[part 2 of 3: package /Cluster]
AUTOSAR XML (schema 00048)
package /Cluster
  5 x can cluster, all with protocol-name=CAN:
    ATOM_CANFD_Matrix_CH_V600_202502  # ATOM_CANFD_Matrix_CH_V6.0.0_20250507 | Revision:V1.0, Revision:V1.0.1, Revision:V1.0.1, Revision:V1.0.1, Revision:V1.0.1, Revision:V1.0.2, Revision:V1.0.2, Revision:V1.0.2, Revision:V1.0.2, Revision:V1.0.2, Revision:V1.0.2, Revision:V1.0.2, Revision:V1.0.2, Revision:V1.0.2, Revision:V1.0.2, Revision:V1.0.2, Revision:V1.0.2, Revision:V1.0.2, Revision:V1.0.2, Revision:V1.0.2, Revision:V1.0.2, Revision:V1.0.2, Revision:V1.0.2, Revision:V1.0.2, Revision:V1.1, Revision:V1.1, Revision:V1.1, Revision:V1.1, Revision:V1.1, Revision:V1.1, Revision:V1.1, Revision:V1.1, Revision:V1.1, Revision:V1.1, Revision:V1.1, Revision:V1.1, Revision:V1.1, Revision:V1.1, Revision:V1.1, Revision:V1.1, Revision:V1.1, Revision:V1.1, Revision:V1.1, Revision:V1.1, Revision:V1.1, Revision:V1.1, Revision:V1.2, Revision:V0.1.3, Revision:V0.1.3, Revision:V0.1.3, Revision:V0.1.3, Revision:V0.1.3, Revision:V0.1.3, Revision:V0.1.3, Revision:V0.1.3, Revision:V0.1.3, Revision:V0.1.3, Revision:V0.1.3, Revision:V0.1.3, Revision:
      can physical channel CHNL: comm-connectors=CN_ATOM_CANFD_Matrix_CH_V600_202502
        frame ACU_01_oATOM_CANFD_Matrix_CH_V600_202502: id 0xF5, to VCU, frame-length=8, can-addressing-mode=STANDARD, can-frame-rx-behavior=ANY, can-frame-tx-behavior=CAN-FD
          pdu ACU_01_oATOM_CANFD_Matrix_CH_V600_202502: length=8, minimum-delay=0, transmission-mode-false-timing=cyclic-timing={time-offset=0, time-period=0.02}, transmission-mode-true-timing=cyclic-timing={time-offset=0, time-period=0.02}, unused-bit-pattern=0
            signal Checksum_0F5_oACU_01_oATOM_CANFD_Matrix_CH_V600_202502: start 7, 8 bit, big-endian, i-signal-type=PRIMITIVE, init-value=0, base-type=uint8, compu {identical}, range raw 0..255, transfer-property=PENDING, to VCU  # Checksum signal for frame
            signal MessageCounter_0F5_oACU_01_oATOM_CANFD_Matrix_CH_V600_202502: start 11, 4 bit, big-endian, i-signal-type=PRIMITIVE, init-value=0, base-type=uint8, compu {15=CxF_Invalid}, range raw 0..15, transfer-property=PENDING, to VCU  # Message counter signal for frame
            signal ACU_YawRate_oACU_01_oATOM_CANFD_Matrix_CH_V600_202502: start 23, 16 bit, big-endian, i-signal-type=PRIMITIVE, init-value=30000, base-type=uint16, compu {65535=CxFFFF_Invalid, phys=raw*0.01-300 for raw 0..65534; unit degrees/s}, range raw 0..65535, unit=degrees/s, transfer-property=PENDING, to VCU  # Yaw rate (clockwise is negative, counterclockwise is positive)
            signal ACU_YawRateStatus_oACU_01_oATOM_CANFD_Matrix_CH_V600_202502: start 39, 2 bit, big-endian, i-signal-type=PRIMITIVE, init-value=0, base-type=uint8, compu {0=Cx0_Invalid, 1=Cx1_Valid, 2=Cx2_Reserved, 3=Cx3_Reserved}, range raw 0..3, transfer-property=PENDING, to VCU  # Yaw rate status
            mapping SG_ACU_01_SigGroup: i-signal-group=SG_ACU_01_SigGroup_oACU_01_oATOM_CANFD_Matrix_CH_V600_202502, transfer-property=PENDING
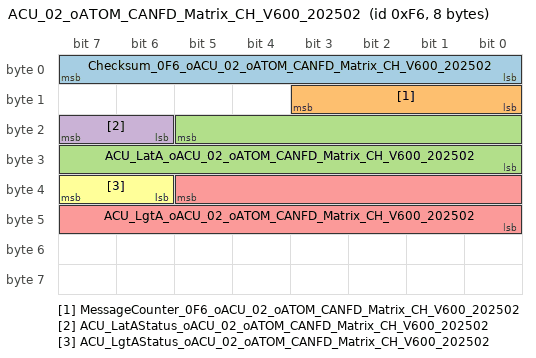
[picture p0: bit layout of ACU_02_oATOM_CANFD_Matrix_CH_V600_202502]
        frame ACU_02_oATOM_CANFD_Matrix_CH_V600_202502: id 0xF6, to VCU, frame-length=8, can-addressing-mode=STANDARD, can-frame-rx-behavior=ANY, can-frame-tx-behavior=CAN-FD
          pdu ACU_02_oATOM_CANFD_Matrix_CH_V600_202502: length=8, minimum-delay=0, transmission-mode-false-timing=cyclic-timing={time-offset=0, time-period=0.02}, transmission-mode-true-timing=cyclic-timing={time-offset=0, time-period=0.02}, unused-bit-pattern=0
            signal Checksum_0F6_oACU_02_oATOM_CANFD_Matrix_CH_V600_202502: start 7, 8 bit, big-endian, i-signal-type=PRIMITIVE, init-value=0, base-type=uint8, compu {identical}, range raw 0..255, transfer-property=PENDING, to VCU  # Checksum signal for frame
            signal MessageCounter_0F6_oACU_02_oATOM_CANFD_Matrix_CH_V600_202502: start 11, 4 bit, big-endian, i-signal-type=PRIMITIVE, init-value=0, base-type=uint8, compu {15=CxF_Invalid}, range raw 0..15, transfer-property=PENDING, to VCU  # Message counter signal for frame
            signal ACU_LatA_oACU_02_oATOM_CANFD_Matrix_CH_V600_202502: start 21, 14 bit, big-endian, i-signal-type=PRIMITIVE, init-value=4905, base-type=uint16, compu {16383=Cx3FFF_Invalid, phys=raw*0.01-49.05 for raw 0..16382; unit m/s^2} "Source signal range: [0,16383]", range raw 0..16383, unit=m/s^2, transfer-property=PENDING, to VCU  # Lateral acceleration(From the driver's perspective, from left to right is the positive direction of lateral acceleration)
            signal ACU_LatAStatus_oACU_02_oATOM_CANFD_Matrix_CH_V600_202502: start 23, 2 bit, big-endian, i-signal-type=PRIMITIVE, init-value=0, base-type=uint8, compu {0=Cx0_Invalid, 1=Cx1_Valid, 2=Cx2_Reserved, 3=Cx3_Reserved}, range raw 0..3, transfer-property=PENDING, to VCU  # Lateral acceleration status
            signal ACU_LgtA_oACU_02_oATOM_CANFD_Matrix_CH_V600_202502: start 37, 14 bit, big-endian, i-signal-type=PRIMITIVE, init-value=4905, base-type=uint16, compu {16383=Cx3FFF_Invalid, phys=raw*0.01-49.05 for raw 0..16382; unit m/s^2} "Source signal range: [0,16383]", range raw 0..16383, unit=m/s^2, transfer-property=PENDING, to VCU  # Longitudinal acceleration(The forward direction of the vehicle is the positive direction of the longitudinal acceleration)
            signal ACU_LgtAStatus_oACU_02_oATOM_CANFD_Matrix_CH_V600_202502: start 39, 2 bit, big-endian, i-signal-type=PRIMITIVE, init-value=0, base-type=uint8, compu {0=Cx0_Invalid, 1=Cx1_Valid, 2=Cx2_Reserved, 3=Cx3_Reserved}, range raw 0..3, transfer-property=PENDING, to VCU  # Longitudinal acceleration status
            mapping SG_ACU_02_SigGroup: i-signal-group=SG_ACU_02_SigGroup_oACU_02_oATOM_CANFD_Matrix_CH_V600_202502, transfer-property=PENDING
        frame ACU_info_oATOM_CANFD_Matrix_CH_V600_202502: id 0x97, to VCU, frame-length=8, can-addressing-mode=STANDARD, can-frame-rx-behavior=ANY, can-frame-tx-behavior=CAN-FD
          pdu ACU_info_oATOM_CANFD_Matrix_CH_V600_202502: length=8, minimum-delay=0, transmission-mode-false-timing=cyclic-timing={time-offset=0, time-period=0.02}, transmission-mode-true-timing=cyclic-timing={time-offset=0, time-period=0.02}, unused-bit-pattern=0
            signal Checksum_097_oACU_info_oATOM_CANFD_Matrix_CH_V600_202502: start 7, 8 bit, big-endian, i-signal-type=PRIMITIVE, init-value=0, base-type=uint8, compu {identical}, range raw 0..255, transfer-property=PENDING, to VCU  # Checksum signal for frame
            signal MessageCounter_097_oACU_info_oATOM_CANFD_Matrix_CH_V600_202502: start 11, 4 bit, big-endian, i-signal-type=PRIMITIVE, init-value=0, base-type=uint8, compu {15=CxF_Invalid}, range raw 0..15, transfer-property=PENDING, to VCU  # Message counter signal for frame
            signal ACU_CrashOutputStsValid_oACU_info_oATOM_CANFD_Matrix_CH_V600_202502: start 16, 1 bit, big-endian, i-signal-type=PRIMITIVE, init-value=1, base-type=boolean, compu {0=Cx0_INVALID, 1=Cx1_VALID}, range raw 0..1, transfer-property=PENDING, to VCU  # Collision signal effective indication
            signal ACU_CrashOutputSts_oACU_info_oATOM_CANFD_Matrix_CH_V600_202502: start 23, 5 bit, big-endian, i-signal-type=PRIMITIVE, init-value=0, base-type=uint8, compu {0=Cx00_No_Crash (No Crash), 1=Cx01_Rollover, 2=Cx02_BPT_Crash (BPT Crash), 3=Cx03_Rollover_BPT (Rollover + BPT), 4=Cx04_Front_Crash (Front Crash), 5=Cx05_Rollover_Front (Rollover + Front), 6=Cx06_BPT_Front (BPT+Front), 7=Cx07_Rollover_BPT_Front (Rollover+BPT+Front), 8=Cx08_Side_Crash (Side Crash), 9=Cx09_Rollover_Side (Rollover+Side), 10=Cx0A_BPT_Side (BPT+Side), 11=Cx0B_Rollover_BPT_Side (Rollover+BPT+Side), 12=Cx0C_Front_Side (Front+Side), 13=Cx0D_Rollover_Front_Side (Rollover+Front+Side), 14=Cx0E_BPT_Front_Side (BPT+Front+Side), 15=Cx0F_Rollover_BPT_Front_Side (Rollover+BPT+Front+Side), 16=Cx10_Rear_Crash (Rear Crash), 17=Cx11_Rollover_Rear (Rollover+Rear), 18=Cx12_BPT_Rear (BPT+Rear), 19=Cx13_Rollover_BPT_Rear (Rollover+BPT+Rear), 20=Cx14_Front_Rear (Front+Rear), 21=Cx15_Rollover_Front_Rear (Rollover+Front+Rear), 22=Cx16_BPT_Front_Rear (BPT+Front+Rear), 23=Cx17_Rollover_BPT_Front_Rear (Rollover+BPT+Front+Rear), 24=Cx18_Side_Rear (Side+Rear), 25=Cx19_Rollover_Side_Rear (Rollover+Side+Rear), 26=Cx1A_BPT_Side_Rear (BPT+Side+Rear), 27=Cx1B_Rollover_BPT_Side_Rear (Rollover+BPT+Side+Rear), 28=Cx1C_Front_Side_Rear (Front+Side+Rear), 29=Cx1D_Rollover_Front_Side_Rear (Rollover+Front+Side+Rear), 30=Cx1E_BPT_Front_Side_Rear (BPT+Front+Side+Rear), 31=Cx1F_Rollover_BPT_Front_Side_Rear (Rollover+BPT+Front+Side+Rear)}, range raw 0..31, transfer-property=PENDING, to VCU  # Crash Output Status
            signal ACU_PassengerSts_oACU_info_oATOM_CANFD_Matrix_CH_V600_202502: start 25, 1 bit, big-endian, i-signal-type=PRIMITIVE, init-value=0, base-type=boolean, compu {0=Cx0_UNOCCUPIED, 1=Cx1_OCCUPIED}, range raw 0..1, transfer-property=PENDING, to VCU  # Passenger seat occupied state
            signal ACU_PassengerSeatBeltStsValid_oACU_info_oATOM_CANFD_Matrix_CH_V600_202502: start 26, 1 bit, big-endian, i-signal-type=PRIMITIVE, init-value=0, base-type=boolean, compu {0=Cx0_INVALID, 1=Cx1_VALID}, range raw 0..1, transfer-property=PENDING, to VCU  # Passenger seat belt status invalid signal
            signal ACU_PassengerSeatBeltSts_oACU_info_oATOM_CANFD_Matrix_CH_V600_202502: start 27, 1 bit, big-endian, i-signal-type=PRIMITIVE, init-value=0, base-type=boolean, compu {0=Cx0_UNTIED, 1=Cx1_TIED}, range raw 0..1, transfer-property=PENDING, to VCU  # Passenger seat belt status
            signal ACU_DriverSeatBeltStsValid_oACU_info_oATOM_CANFD_Matrix_CH_V600_202502: start 30, 1 bit, big-endian, i-signal-type=PRIMITIVE, init-value=0, base-type=boolean, compu {0=Cx0_INVALID, 1=Cx1_VALID}, range raw 0..1, transfer-property=PENDING, to VCU  # Driver seat belt state invalid
            signal ACU_DriverSeatBeltSts_oACU_info_oATOM_CANFD_Matrix_CH_V600_202502: start 31, 1 bit, big-endian, i-signal-type=PRIMITIVE, init-value=0, base-type=boolean, compu {0=Cx0_UNTIED, 1=Cx1_TIED}, range raw 0..1, transfer-property=PENDING, to VCU  # Driver seat belt status
            signal ACU_SecondLeftSts_oACU_info_oATOM_CANFD_Matrix_CH_V600_202502: start 37, 1 bit, big-endian, i-signal-type=PRIMITIVE, init-value=0, base-type=boolean, compu {0=Cx0_UNOCCUPIED, 1=Cx1_OCCUPIED}, range raw 0..1, transfer-property=PENDING, to VCU  # The left seat of the second row is occupied
            signal ACU_RLSeatBeltStatusValid_oACU_info_oATOM_CANFD_Matrix_CH_V600_202502: start 38, 1 bit, big-endian, i-signal-type=PRIMITIVE, init-value=0, base-type=boolean, compu {0=Cx0_INVALID, 1=Cx1_VALID}, range raw 0..1, transfer-property=PENDING, to VCU  # Second row seat belt status on the left is valid
            signal ACU_SecondLeftSeatBeltSts_oACU_info_oATOM_CANFD_Matrix_CH_V600_202502: start 39, 1 bit, big-endian, i-signal-type=PRIMITIVE, init-value=0, base-type=boolean, compu {0=Cx0_UNTIED, 1=Cx1_TIED}, range raw 0..1, transfer-property=PENDING, to VCU  # Second row left seat belt condition
            signal ACU_SecondRightSts_oACU_info_oATOM_CANFD_Matrix_CH_V600_202502: start 53, 1 bit, big-endian, i-signal-type=PRIMITIVE, init-value=0, base-type=boolean, compu {0=Cx0_UNOCCUPIED, 1=Cx1_OCCUPIED}, range raw 0..1, transfer-property=PENDING, to VCU  # The right seat of the second row is occupied
            signal ACU_RRSeatBeltStatusValid_oACU_info_oATOM_CANFD_Matrix_CH_V600_202502: start 54, 1 bit, big-endian, i-signal-type=PRIMITIVE, init-value=0, base-type=boolean, compu {0=Cx0_INVALID, 1=Cx1_VALID}, range raw 0..1, transfer-property=PENDING, to VCU  # Second row seat belt status on the lright is valid
            signal ACU_SecondRightSeatBeltSts_oACU_info_oATOM_CANFD_Matrix_CH_V600_202502: start 55, 1 bit, big-endian, i-signal-type=PRIMITIVE, init-value=0, base-type=boolean, compu {0=Cx0_UNTIED, 1=Cx1_TIED}, range raw 0..1, transfer-property=PENDING, to VCU  # Second row right seat belt status
            signal ACU_WarningLampSts_oACU_info_oATOM_CANFD_Matrix_CH_V600_202502: start 57, 2 bit, big-endian, i-signal-type=PRIMITIVE, init-value=0, base-type=uint8, compu {0=Cx0_OFF, 1=Cx1_ON, 2=Cx2_FLASH}, range raw 0..2, transfer-property=PENDING, to VCU  # WarningLampStatus
            signal ACU_PassengerWarningLampSts_oACU_info_oATOM_CANFD_Matrix_CH_V600_202502: start 59, 2 bit, big-endian, i-signal-type=PRIMITIVE, init-value=0, base-type=uint8, compu {0=Cx0_OFF, 1=Cx1_ON, 2=Cx2_FLASH}, range raw 0..2, transfer-property=PENDING, to VCU  # Passenger Warning Lamp Status
            signal ACU_DriverWarningLampSts_oACU_info_oATOM_CANFD_Matrix_CH_V600_202502: start 61, 2 bit, big-endian, i-signal-type=PRIMITIVE, init-value=0, base-type=uint8, compu {0=Cx0_OFF, 1=Cx1_ON, 2=Cx2_FLASH}, range raw 0..2, transfer-property=PENDING, to VCU  # Driver Warning Lamp Status
            signal ACU_PassengerAirbagSts_oACU_info_oATOM_CANFD_Matrix_CH_V600_202502: start 63, 2 bit, big-endian, i-signal-type=PRIMITIVE, init-value=0, base-type=uint8, compu {0=Cx0_RESERVED, 1=Cx1_Disabled, 2=Cx2_Enabled, 3=Cx3_RESERVED}, range raw 0..3, transfer-property=PENDING, to VCU  # Passenger Airbag Status, closed or not
            mapping SG_ACU_info_SigGroup: i-signal-group=SG_ACU_info_SigGroup_oACU_info_oATOM_CANFD_Matrix_CH_V600_202502, transfer-property=PENDING
        frame ADCU_ACC_02_oATOM_CANFD_Matrix_CH_V600_202502: id 0xE0, to VCU, frame-length=8, can-addressing-mode=STANDARD, can-frame-rx-behavior=ANY, can-frame-tx-behavior=CAN-FD
          pdu ADCU_ACC_02_oATOM_CANFD_Matrix_CH_V600_202502: length=8, minimum-delay=0, transmission-mode-false-timing=cyclic-timing={time-offset=0, time-period=0.02}, transmission-mode-true-timing=cyclic-timing={time-offset=0, time-period=0.02}, unused-bit-pattern=0
            signal Checksum_0E0_oADCU_ACC_02_oATOM_CANFD_Matrix_CH_V600_202502: start 7, 8 bit, big-endian, i-signal-type=PRIMITIVE, init-value=0, base-type=uint8, compu {identical}, range raw 0..255, transfer-property=PENDING, to VCU  # Checksum signal for frame
            signal MessageCounter_0E0_oADCU_ACC_02_oATOM_CANFD_Matrix_CH_V600_202502: start 11, 4 bit, big-endian, i-signal-type=PRIMITIVE, init-value=0, base-type=uint8, compu {15=CxF_Invalid}, range raw 0..15, transfer-property=PENDING, to VCU  # Message counter signal for frame
            signal ADCU_ACCDA_HandsOFF_Warning_oADCU_ACC_02_oATOM_CANFD_Matrix_CH_V600_202502: start 18, 3 bit, big-endian, i-signal-type=PRIMITIVE, init-value=0, base-type=uint8, compu {0=Cx0_No_Warning (No Warning), 1=Cx1_Hands_Off_1st_Warning (Hands Off 1st Warning), 2=Cx2_Hands_Off_2nd_Warning (Hands Off 2nd Warning), 3=Cx3_Function_Automatic_exit_Warning (Function Automatic exit Warning), 4=Cx4_Reserved, 5=Cx5_Reserved, 6=Cx6_Reserved, 7=Cx7_Reserved}, range raw 0..7, transfer-property=PENDING, to VCU  # ACC/DA Hands off warning
            signal ADCU_ACC_Mode_oADCU_ACC_02_oATOM_CANFD_Matrix_CH_V600_202502: start 21, 3 bit, big-endian, i-signal-type=PRIMITIVE, init-value=0, base-type=uint8, compu {0=Cx0_Off, 1=Cx1_Active_State (Active State), 2=Cx2_Override_State (Override State), 3=Cx3_Shut_off_State (Shut-off State), 4=Cx4_Standby_State (Standby State), 5=Cx5_Fail_State (Fail State), 6=Cx6_Reserved, 7=Cx7_Reserved}, range raw 0..7, transfer-property=PENDING, to VCU  # ACC mode for system state
            signal ADCU_ACCDA_SYS_Failure_oADCU_ACC_02_oATOM_CANFD_Matrix_CH_V600_202502: start 23, 2 bit, big-endian, i-signal-type=PRIMITIVE, init-value=0, base-type=uint8, compu {0=Cx0_No_Error (No Error), 1=Cx1_Error, 2=Cx2_Reserved, 3=Cx3_Reserved}, range raw 0..3, transfer-property=PENDING, to VCU  # ACC/DA system failure state If this signal is set to anything other than 0, the IBS shall ignore any requests from ACC
            mapping SG_ADCU_ACC_02_SigGroup: i-signal-group=SG_ADCU_ACC_02_SigGroup_oADCU_ACC_02_oATOM_CANFD_Matrix_CH_V600_202502, transfer-property=PENDING
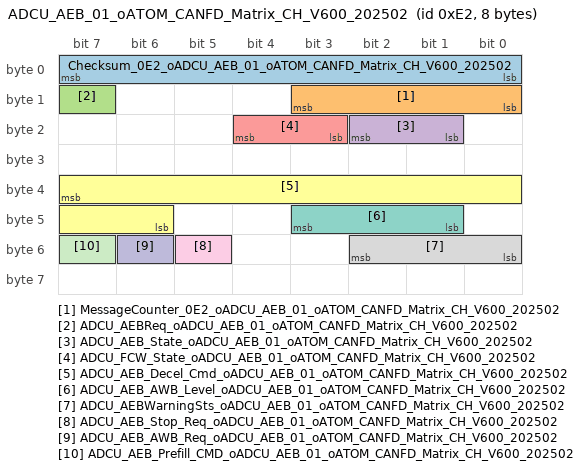
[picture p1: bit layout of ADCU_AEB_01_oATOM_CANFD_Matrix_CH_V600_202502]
        frame ADCU_AEB_01_oATOM_CANFD_Matrix_CH_V600_202502: id 0xE2, to VCU, frame-length=8, can-addressing-mode=STANDARD, can-frame-rx-behavior=ANY, can-frame-tx-behavior=CAN-FD
          pdu ADCU_AEB_01_oATOM_CANFD_Matrix_CH_V600_202502: length=8, minimum-delay=0, transmission-mode-false-timing=cyclic-timing={time-offset=0, time-period=0.02}, transmission-mode-true-timing=cyclic-timing={time-offset=0, time-period=0.02}, unused-bit-pattern=0
            signal Checksum_0E2_oADCU_AEB_01_oATOM_CANFD_Matrix_CH_V600_202502: start 7, 8 bit, big-endian, i-signal-type=PRIMITIVE, init-value=0, base-type=uint8, compu {identical}, range raw 0..255, transfer-property=PENDING, to VCU  # Checksum signal for frame
            signal MessageCounter_0E2_oADCU_AEB_01_oATOM_CANFD_Matrix_CH_V600_202502: start 11, 4 bit, big-endian, i-signal-type=PRIMITIVE, init-value=0, base-type=uint8, compu {15=CxF_Invalid}, range raw 0..15, transfer-property=PENDING, to VCU  # Message counter signal for frame
            signal ADCU_AEBReq_oADCU_AEB_01_oATOM_CANFD_Matrix_CH_V600_202502: start 15, 1 bit, big-endian, i-signal-type=PRIMITIVE, init-value=0, base-type=boolean, compu {0=Cx0_No_active (No active), 1=Cx1_active}, range raw 0..1, transfer-property=PENDING, to VCU  # A control requeset flag for AEB
            signal ADCU_AEB_State_oADCU_AEB_01_oATOM_CANFD_Matrix_CH_V600_202502: start 18, 2 bit, big-endian, i-signal-type=PRIMITIVE, init-value=0, base-type=uint8, compu {0=Cx0_Off, 1=Cx1_Standby, 2=Cx2_Active, 3=Cx3_Failure}, range raw 0..3, transfer-property=PENDING, to VCU  # This signal describes the state AEB Function.
            signal ADCU_FCW_State_oADCU_AEB_01_oATOM_CANFD_Matrix_CH_V600_202502: start 20, 2 bit, big-endian, i-signal-type=PRIMITIVE, init-value=0, base-type=uint8, compu {0=Cx0_Off, 1=Cx1_Standby, 2=Cx2_Active, 3=Cx3_Failure}, range raw 0..3, transfer-property=PENDING, to VCU  # This signal describes the state FCW Function.
            signal ADCU_AEB_Decel_Cmd_oADCU_AEB_01_oATOM_CANFD_Matrix_CH_V600_202502: start 39, 10 bit, big-endian, i-signal-type=PRIMITIVE, init-value=0, base-type=sint16, compu {phys=raw*0.05-16 for raw 0..511; unit m/s^2}, range raw 0..511, unit=m/s^2, transfer-property=PENDING, to VCU  # Depending on the driving situation, ADCU gives IBS the AEB deceleration command. IBS maintains the deceleration.
            signal ADCU_AEB_AWB_Level_oADCU_AEB_01_oATOM_CANFD_Matrix_CH_V600_202502: start 43, 3 bit, big-endian, i-signal-type=PRIMITIVE, init-value=0, base-type=uint8, compu {0=Cx0_No_level (No level), 1=Cx1_Level_1 (Level 1), 2=Cx2_Level_2 (Level 2), 3=Cx3_Level_3 (Level 3), 4=Cx4_Level_4 (Level 4), 5=Cx5_Reserved}, range raw 0..5, transfer-property=PENDING, to VCU  # AWB level
            signal ADCU_AEBWarningSts_oADCU_AEB_01_oATOM_CANFD_Matrix_CH_V600_202502: start 50, 3 bit, big-endian, i-signal-type=PRIMITIVE, init-value=0, base-type=uint8, compu {0=Cx0_NO_WARNING, 1=Cx1_PreWarning_to_car (PreWarning to car), 2=Cx2_Latent_distance_Warning (Latent distance Warning), 3=Cx3_Braking_to_car (Braking to car), 4=Cx4_PreWarning_to_PED (PreWarning to PED), 5=Cx5_Braking_to_PED (Braking to PED), 6=Cx6_Reserved, 7=Cx7_Reserved}, range raw 0..7, transfer-property=PENDING, to VCU  # PEBSWarning,include PreWarning and emergency Warning.
            signal ADCU_AEB_Stop_Req_oADCU_AEB_01_oATOM_CANFD_Matrix_CH_V600_202502: start 53, 1 bit, big-endian, i-signal-type=PRIMITIVE, init-value=0, base-type=boolean, compu {0=Cx0_No_request (No request), 1=Cx1_Stop_control_is_required (Stop control is required)}, range raw 0..1, transfer-property=PENDING, to VCU  # A control request flag for vehicle stop. AEB expects vehicle to be controlled to a complete stop and hold its state by ESC.
            signal ADCU_AEB_AWB_Req_oADCU_AEB_01_oATOM_CANFD_Matrix_CH_V600_202502: start 54, 1 bit, big-endian, i-signal-type=PRIMITIVE, init-value=0, base-type=boolean, compu {0=Cx0_No_Request (No Request), 1=Cx1_Request}, range raw 0..1, transfer-property=PENDING, to VCU  # This signal means command to activate AWB
            signal ADCU_AEB_Prefill_CMD_oADCU_AEB_01_oATOM_CANFD_Matrix_CH_V600_202502: start 55, 1 bit, big-endian, i-signal-type=PRIMITIVE, init-value=0, base-type=boolean, compu {0=Cx0_No_pre_fill (No pre-fill), 1=Cx1_Pre_fill_act (Pre-fill act)}, range raw 0..1, transfer-property=PENDING, to VCU  # This signal means command to activate pre-fill
            mapping SG_ADCU_AEB_01_SigGroup: i-signal-group=SG_ADCU_AEB_01_SigGroup_oADCU_AEB_01_oATOM_CANFD_Matrix_CH_V600_202502, transfer-property=PENDING
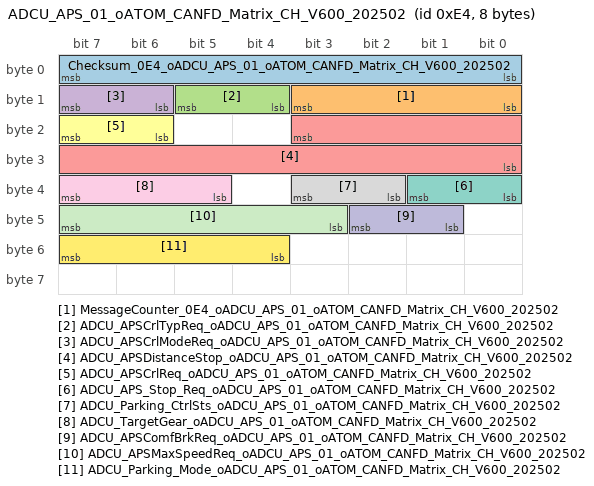
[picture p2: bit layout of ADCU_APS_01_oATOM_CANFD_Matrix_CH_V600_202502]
        frame ADCU_APS_01_oATOM_CANFD_Matrix_CH_V600_202502: id 0xE4, to VCU, frame-length=8, can-addressing-mode=STANDARD, can-frame-rx-behavior=ANY, can-frame-tx-behavior=CAN-FD
          pdu ADCU_APS_01_oATOM_CANFD_Matrix_CH_V600_202502: length=8, minimum-delay=0, transmission-mode-false-timing=cyclic-timing={time-offset=0, time-period=0.02}, transmission-mode-true-timing=cyclic-timing={time-offset=0, time-period=0.02}, unused-bit-pattern=0
            signal Checksum_0E4_oADCU_APS_01_oATOM_CANFD_Matrix_CH_V600_202502: start 7, 8 bit, big-endian, i-signal-type=PRIMITIVE, init-value=0, base-type=uint8, compu {identical}, range raw 0..255, transfer-property=PENDING, to VCU  # Checksum signal for frame
            signal MessageCounter_0E4_oADCU_APS_01_oATOM_CANFD_Matrix_CH_V600_202502: start 11, 4 bit, big-endian, i-signal-type=PRIMITIVE, init-value=0, base-type=uint8, compu {15=CxF_Invalid}, range raw 0..15, transfer-property=PENDING, to VCU  # Message counter signal for frame
            signal ADCU_APSCrlTypReq_oADCU_APS_01_oATOM_CANFD_Matrix_CH_V600_202502: start 13, 2 bit, big-endian, i-signal-type=PRIMITIVE, init-value=0, base-type=uint8, compu {0=Cx0_None, 1=Cx1_Comfort, 2=Cx2_Emergency, 3=Cx3_Reserved}, range raw 0..3, transfer-property=PENDING, to VCU  # Request comfort or emergency brake
            signal ADCU_APSCrlModeReq_oADCU_APS_01_oATOM_CANFD_Matrix_CH_V600_202502: start 15, 2 bit, big-endian, i-signal-type=PRIMITIVE, init-value=0, base-type=uint8, compu {0=Cx0_None, 1=Cx1_APS, 2=Cx2_RC, 3=Cx3_Reserved}, range raw 0..3, transfer-property=PENDING, to VCU  # Request Low Speed Maneuvering Control Mode (PAS (full/semi auto) or RC)
            signal ADCU_APSDistanceStop_oADCU_APS_01_oATOM_CANFD_Matrix_CH_V600_202502: start 19, 12 bit, big-endian, i-signal-type=PRIMITIVE, init-value=0, base-type=uint16, compu {4095=CxFFF_Invalid; unit cm}, range raw 0..4095, unit=cm, transfer-property=PENDING, to VCU  # Stopdistance request
            signal ADCU_APSCrlReq_oADCU_APS_01_oATOM_CANFD_Matrix_CH_V600_202502: start 23, 2 bit, big-endian, i-signal-type=PRIMITIVE, init-value=0, base-type=uint8, compu {0=Cx0_Req_None, 1=Cx1_Req_Drive, 2=Cx2_Req_LSM}, range raw 0..2, transfer-property=PENDING, to VCU  # Request Maneuvering dynamic control function (Driving or Low Speed Maneuvering)
            signal ADCU_APS_Stop_Req_oADCU_APS_01_oATOM_CANFD_Matrix_CH_V600_202502: start 33, 2 bit, big-endian, i-signal-type=PRIMITIVE, init-value=0, base-type=uint8, compu {0=Cx0_No_request (No request), 1=Cx1_Stop_control_is_required (Stop control is required), 2=Cx2_No_need_to_stop (No need to stop)}, range raw 0..2, transfer-property=PENDING, to VCU  # Request complete stop and hold its state by IBS
            signal ADCU_Parking_CtrlSts_oADCU_APS_01_oATOM_CANFD_Matrix_CH_V600_202502: start 35, 2 bit, big-endian, i-signal-type=PRIMITIVE, init-value=0, base-type=uint8, compu {0=Cx0_OFF, 1=Cx1_ON, 2=Cx2_Failure, 3=Cx3_Reserved}, range raw 0..3, transfer-property=PENDING, to VCU  # Parking indicator light status
            signal ADCU_TargetGear_oADCU_APS_01_oATOM_CANFD_Matrix_CH_V600_202502: start 39, 3 bit, big-endian, i-signal-type=PRIMITIVE, init-value=0, base-type=uint8, compu {0=Cx0_No_Request (No Request), 1=Cx1_P, 2=Cx2_N, 3=Cx3_R, 4=Cx4_D}, range raw 0..4, transfer-property=PENDING, to VCU  # Shift request signal
            signal ADCU_APSComfBrkReq_oADCU_APS_01_oATOM_CANFD_Matrix_CH_V600_202502: start 42, 2 bit, big-endian, i-signal-type=PRIMITIVE, init-value=0, base-type=uint8, compu {0=Cx0_ComfBrakeReq_NoReq, 1=Cx1_ComfBrakeReq_Type1, 2=Cx2_ComfBrakeReq_Type2}, range raw 0..2, transfer-property=PENDING, to VCU  # BrakeMode Request
            signal ADCU_APSMaxSpeedReq_oADCU_APS_01_oATOM_CANFD_Matrix_CH_V600_202502: start 47, 5 bit, big-endian, i-signal-type=PRIMITIVE, init-value=0, base-type=uint8, compu {31=Cx1F_Invalid; unit km/h} "Source signal range: [0,30]", range raw 0..31, unit=km/h, transfer-property=PENDING, to VCU  # V Max request
            signal ADCU_Parking_Mode_oADCU_APS_01_oATOM_CANFD_Matrix_CH_V600_202502: start 55, 4 bit, big-endian, i-signal-type=PRIMITIVE, init-value=0, base-type=uint8, compu {0=Cx0_Off, 1=Cx1_Standby, 2=Cx2_Background_searching (Background searching), 3=Cx3_Searching, 4=Cx4_Guidance_active (Guidance active), 5=Cx5_Recovery_interrupt (Recovery interrupt), 6=Cx6_Completed, 7=Cx7_Failure, 8=Cx8_Terminated, 9=Cx9_Reserved, 10=CxA_Reserved, 11=CxB_Reserved, 12=CxC_Reserved, 13=CxD_Reserved, 14=CxE_Reserved, 15=CxF_Reserved}, range raw 0..15, transfer-property=PENDING, to VCU  # APS function status.
            mapping SG_ADCU_APS_01_SigGroup: i-signal-group=SG_ADCU_APS_01_SigGroup_oADCU_APS_01_oATOM_CANFD_Matrix_CH_V600_202502, transfer-property=PENDING
        frame ADCU_APS_02_oATOM_CANFD_Matrix_CH_V600_202502: id 0x20D, to VCU, frame-length=8, can-addressing-mode=STANDARD, can-frame-rx-behavior=ANY, can-frame-tx-behavior=CAN-FD
          pdu ADCU_APS_02_oATOM_CANFD_Matrix_CH_V600_202502: length=8, minimum-delay=0, transmission-mode-false-timing=cyclic-timing={time-offset=0, time-period=0.1}, transmission-mode-true-timing=cyclic-timing={time-offset=0, time-period=0.1}, unused-bit-pattern=0
            signal ADCU_RemoteParkingMode_oADCU_APS_02_oATOM_CANFD_Matrix_CH_V600_202502: start 23, 4 bit, big-endian, i-signal-type=PRIMITIVE, init-value=0, base-type=uint8, compu {0=Cx0_Off, 1=Cx1_Prepare, 2=Cx2_Standby, 3=Cx3_Moving, 4=Cx4_Recovery_interrupt (Recovery interrupt), 5=Cx5_Voluntarily_Exit (Voluntarily Exit), 6=Cx6_Passive_Exit (Passive Exit), 7=Cx7_Failure, 8=Cx8_Reserved, 9=Cx9_Reserved, 10=CxA_Reserved, 11=CxB_Reserved, 12=CxC_Reserved, 13=CxD_Reserved, 14=CxE_Reserved, 15=CxF_Reserved}, range raw 0..15, transfer-property=PENDING, to VCU  # Remote parking function status
            mapping SG_ADCU_APS_02_SigGroup: i-signal-group=SG_ADCU_APS_02_SigGroup_oADCU_APS_02_oATOM_CANFD_Matrix_CH_V600_202502, transfer-property=PENDING
        frame ADCU_DA_oATOM_CANFD_Matrix_CH_V600_202502: id 0xE6, to VCU, frame-length=8, can-addressing-mode=STANDARD, can-frame-rx-behavior=ANY, can-frame-tx-behavior=CAN-FD
          pdu ADCU_DA_oATOM_CANFD_Matrix_CH_V600_202502: length=8, minimum-delay=0, transmission-mode-false-timing=cyclic-timing={time-offset=0, time-period=0.1}, transmission-mode-true-timing=cyclic-timing={time-offset=0, time-period=0.1}, unused-bit-pattern=0
            signal Checksum_0E6_oADCU_DA_oATOM_CANFD_Matrix_CH_V600_202502: start 7, 8 bit, big-endian, i-signal-type=PRIMITIVE, init-value=0, base-type=uint8, compu {identical}, range raw 0..255, transfer-property=PENDING, to VCU  # Checksum signal for frame
            signal MessageCounter_0E6_oADCU_DA_oATOM_CANFD_Matrix_CH_V600_202502: start 11, 4 bit, big-endian, i-signal-type=PRIMITIVE, init-value=0, base-type=uint8, compu {15=CxF_Invalid}, range raw 0..15, transfer-property=PENDING, to VCU  # Message counter signal for frame
            signal ADCU_DA_Mode_oADCU_DA_oATOM_CANFD_Matrix_CH_V600_202502: start 23, 3 bit, big-endian, i-signal-type=PRIMITIVE, init-value=0, base-type=uint8, compu {0=Cx0_Off, 1=Cx1_Standby_Inhibit (Standby-Inhibit), 2=Cx2_Standby_Available (Standby-Available), 3=Cx3_Active, 4=Cx4_Override_longitudinal (Override-longitudinal), 5=Cx5_Override_lateral (Override-lateral), 6=Cx6_Failure, 7=Cx7_Reserved}, range raw 0..7, transfer-property=PENDING, to VCU  # DA mode for system state
            mapping SG_ADCU_DA_SigGroup: i-signal-group=SG_ADCU_DA_SigGroup_oADCU_DA_oATOM_CANFD_Matrix_CH_V600_202502, transfer-property=PENDING
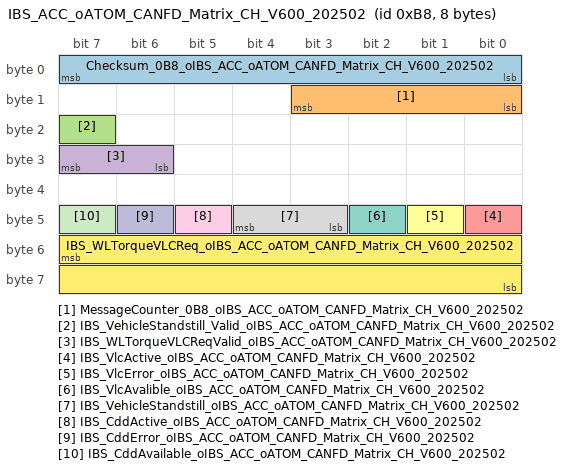
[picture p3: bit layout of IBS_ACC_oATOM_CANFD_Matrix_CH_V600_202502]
        frame IBS_ACC_oATOM_CANFD_Matrix_CH_V600_202502: id 0xB8, to VCU, frame-length=8, can-addressing-mode=STANDARD, can-frame-rx-behavior=ANY, can-frame-tx-behavior=CAN-FD
          pdu IBS_ACC_oATOM_CANFD_Matrix_CH_V600_202502: length=8, minimum-delay=0, transmission-mode-false-timing=cyclic-timing={time-offset=0, time-period=0.02}, transmission-mode-true-timing=cyclic-timing={time-offset=0, time-period=0.02}, unused-bit-pattern=0
            signal Checksum_0B8_oIBS_ACC_oATOM_CANFD_Matrix_CH_V600_202502: start 7, 8 bit, big-endian, i-signal-type=PRIMITIVE, init-value=0, base-type=uint8, compu {identical}, range raw 0..255, transfer-property=PENDING, to VCU  # Checksum signal for frame
            signal MessageCounter_0B8_oIBS_ACC_oATOM_CANFD_Matrix_CH_V600_202502: start 11, 4 bit, big-endian, i-signal-type=PRIMITIVE, init-value=0, base-type=uint8, compu {15=CxF_Invalid}, range raw 0..15, transfer-property=PENDING, to VCU  # Message counter signal for frame
            signal IBS_VehicleStandstill_Valid_oIBS_ACC_oATOM_CANFD_Matrix_CH_V600_202502: start 23, 1 bit, big-endian, i-signal-type=PRIMITIVE, init-value=0, base-type=boolean, compu {0=Cx0_Invalid, 1=Cx1_Valid}, range raw 0..1, transfer-property=PENDING, to VCU  # Validity of indicating signal IBS_vehiclestill
            signal IBS_WLTorqueVLCReqValid_oIBS_ACC_oATOM_CANFD_Matrix_CH_V600_202502: start 31, 2 bit, big-endian, i-signal-type=PRIMITIVE, init-value=0, base-type=uint8, compu {0=Cx0_NotIntialized, 1=Cx1_Normal, 2=Cx2_Faulty}, range raw 0..2, transfer-property=PENDING, to VCU  # VLC Wheel Torque Request Valid
            signal IBS_VlcActive_oIBS_ACC_oATOM_CANFD_Matrix_CH_V600_202502: start 40, 1 bit, big-endian, i-signal-type=PRIMITIVE, init-value=0, base-type=boolean, compu {0=Cx0_INACTIVE, 1=Cx1_ACTIVE}, range raw 0..1, transfer-property=PENDING, to VCU  # Indicates VLC is active or not.
            signal IBS_VlcError_oIBS_ACC_oATOM_CANFD_Matrix_CH_V600_202502: start 41, 1 bit, big-endian, i-signal-type=PRIMITIVE, init-value=0, base-type=boolean, compu {0=Cx0_NOT_ERROR, 1=Cx1_ERROR}, range raw 0..1, transfer-property=PENDING, to VCU  # Indicate the failure status of VLC.
            signal IBS_VlcAvalible_oIBS_ACC_oATOM_CANFD_Matrix_CH_V600_202502: start 42, 1 bit, big-endian, i-signal-type=PRIMITIVE, init-value=0, base-type=boolean, compu {0=Cx0_NOT_AVAILABLE, 1=Cx1_AVAILABLE}, range raw 0..1, transfer-property=PENDING, to VCU  # Indicating whether VLC is basically ready for activation or not. It could be combined with VLCFail.
            signal IBS_VehicleStandstill_oIBS_ACC_oATOM_CANFD_Matrix_CH_V600_202502: start 44, 2 bit, big-endian, i-signal-type=PRIMITIVE, init-value=0, base-type=uint8, compu {0=Cx0_NOT_STANDSTILL, 1=Cx1_STANDSTILL, 2=Cx2_RESERVED}, range raw 0..2, transfer-property=PENDING, to VCU  # Indicating whether the vehicle is standstill or not Cannot be set until standstill is surely reached.
            signal IBS_CddActive_oIBS_ACC_oATOM_CANFD_Matrix_CH_V600_202502: start 45, 1 bit, big-endian, i-signal-type=PRIMITIVE, init-value=0, base-type=boolean, compu {0=Cx0_INACTIVE, 1=Cx1_ACTIVE}, range raw 0..1, transfer-property=PENDING, to VCU  # Indicate CDD is active or not.
            signal IBS_CddError_oIBS_ACC_oATOM_CANFD_Matrix_CH_V600_202502: start 46, 1 bit, big-endian, i-signal-type=PRIMITIVE, init-value=0, base-type=boolean, compu {0=Cx0_NOT_ERROR, 1=Cx1_ERROR}, range raw 0..1, transfer-property=PENDING, to VCU  # Indicate the failure status of CDD
            signal IBS_CddAvailable_oIBS_ACC_oATOM_CANFD_Matrix_CH_V600_202502: start 47, 1 bit, big-endian, i-signal-type=PRIMITIVE, init-value=0, base-type=boolean, compu {0=Cx0_NOT_AVAILABLE, 1=Cx1_AVAILABLE}, range raw 0..1, transfer-property=PENDING, to VCU  # Indicate CDD is available or not.
            signal IBS_WLTorqueVLCReq_oIBS_ACC_oATOM_CANFD_Matrix_CH_V600_202502: start 55, 16 bit, big-endian, i-signal-type=PRIMITIVE, init-value=0, base-type=sint16, compu {phys=raw-20000 for raw 0..32767; unit Nm}, range raw 0..32767, unit=Nm, transfer-property=PENDING, to VCU  # VLC Wheel Torque Request
            mapping SG_IBS_ACC_SigGroup: i-signal-group=SG_IBS_ACC_SigGroup_oIBS_ACC_oATOM_CANFD_Matrix_CH_V600_202502, transfer-property=PENDING
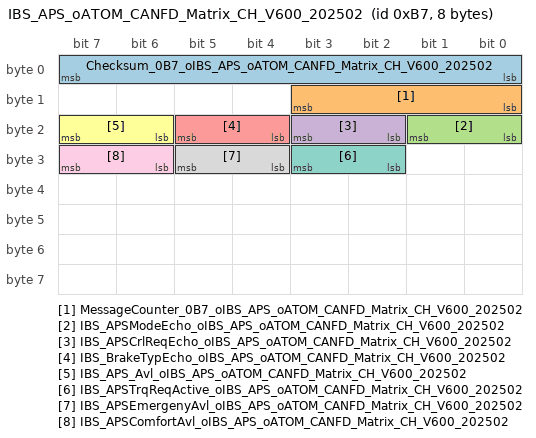
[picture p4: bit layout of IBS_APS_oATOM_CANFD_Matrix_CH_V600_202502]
        frame IBS_APS_oATOM_CANFD_Matrix_CH_V600_202502: id 0xB7, to VCU, frame-length=8, can-addressing-mode=STANDARD, can-frame-rx-behavior=ANY, can-frame-tx-behavior=CAN-FD
          pdu IBS_APS_oATOM_CANFD_Matrix_CH_V600_202502: length=8, minimum-delay=0, transmission-mode-false-timing=cyclic-timing={time-offset=0, time-period=0.02}, transmission-mode-true-timing=cyclic-timing={time-offset=0, time-period=0.02}, unused-bit-pattern=0
            signal Checksum_0B7_oIBS_APS_oATOM_CANFD_Matrix_CH_V600_202502: start 7, 8 bit, big-endian, i-signal-type=PRIMITIVE, init-value=0, base-type=uint8, compu {identical}, range raw 0..255, transfer-property=PENDING, to VCU  # Checksum signal for frame
            signal MessageCounter_0B7_oIBS_APS_oATOM_CANFD_Matrix_CH_V600_202502: start 11, 4 bit, big-endian, i-signal-type=PRIMITIVE, init-value=0, base-type=uint8, compu {15=CxF_Invalid}, range raw 0..15, transfer-property=PENDING, to VCU  # Message counter signal for frame
            signal IBS_APSModeEcho_oIBS_APS_oATOM_CANFD_Matrix_CH_V600_202502: start 17, 2 bit, big-endian, i-signal-type=PRIMITIVE, init-value=0, base-type=uint8, compu {0=Cx0_None, 1=Cx1_APS, 2=Cx2_RC, 3=Cx3_Reserved}, range raw 0..3, transfer-property=PENDING, to VCU  # FeedbackÂ to upper system
            signal IBS_APSCrlReqEcho_oIBS_APS_oATOM_CANFD_Matrix_CH_V600_202502: start 19, 2 bit, big-endian, i-signal-type=PRIMITIVE, init-value=0, base-type=uint8, compu {0=Cx0_None, 1=Cx1_Drive, 2=Cx2_LSM, 3=Cx3_reserved}, range raw 0..3, transfer-property=PENDING, to VCU  # Feedback control status to upper system
            signal IBS_BrakeTypEcho_oIBS_APS_oATOM_CANFD_Matrix_CH_V600_202502: start 21, 2 bit, big-endian, i-signal-type=PRIMITIVE, init-value=0, base-type=uint8, compu {0=Cx0_None, 1=Cx1_Comfort, 2=Cx2_Emergency, 3=Cx3_Reserved}, range raw 0..3, transfer-property=PENDING, to VCU  # Feedback Comfort or emergency to upper system
            signal IBS_APS_Avl_oIBS_APS_oATOM_CANFD_Matrix_CH_V600_202502: start 23, 2 bit, big-endian, i-signal-type=PRIMITIVE, init-value=0, base-type=uint8, compu {0=Cx0_AxCapbl_Full, 1=Cx1_reversed, 2=Cx2_AxCapbl_VehBlocked, 3=Cx3_reversed}, range raw 0..3, transfer-property=PENDING, to VCU  # Indicate the function availability
            signal IBS_APSTrqReqActive_oIBS_APS_oATOM_CANFD_Matrix_CH_V600_202502: start 27, 2 bit, big-endian, i-signal-type=PRIMITIVE, init-value=0, base-type=uint8, compu {0=Cx0_INACTIVE, 1=Cx1_ACTIVE}, range raw 0..1, transfer-property=PENDING, to VCU  # APS function activation flag bit
            signal IBS_APSEmergenyAvl_oIBS_APS_oATOM_CANFD_Matrix_CH_V600_202502: start 29, 2 bit, big-endian, i-signal-type=PRIMITIVE, init-value=0, base-type=uint8, compu {0=Cx0_NotAvailable, 1=Cx1_Brake_failure (Brake failure), 2=Cx2_Excessive_slope (Excessive slope), 3=Cx3_Available}, range raw 0..3, transfer-property=PENDING, to VCU  # Feedback ofÂ APS Emergency Availability
            signal IBS_APSComfortAvl_oIBS_APS_oATOM_CANFD_Matrix_CH_V600_202502: start 31, 2 bit, big-endian, i-signal-type=PRIMITIVE, init-value=0, base-type=uint8, compu {0=Cx0_NotAvailable, 1=Cx1_Brake_failure (Brake failure), 2=Cx2_Excessive_slope (Excessive slope), 3=Cx3_Available}, range raw 0..3, transfer-property=PENDING, to VCU  # Feedback of APS Comfort Availability
            mapping SG_IBS_APS_SigGroup: i-signal-group=SG_IBS_APS_SigGroup_oIBS_APS_oATOM_CANFD_Matrix_CH_V600_202502, transfer-property=PENDING
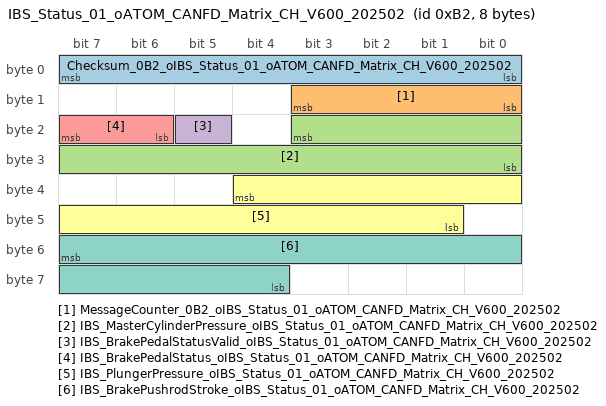
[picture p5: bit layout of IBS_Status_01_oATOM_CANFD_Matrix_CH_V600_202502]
        frame IBS_Status_01_oATOM_CANFD_Matrix_CH_V600_202502: id 0xB2, to VCU, frame-length=8, can-addressing-mode=STANDARD, can-frame-rx-behavior=ANY, can-frame-tx-behavior=CAN-FD
          pdu IBS_Status_01_oATOM_CANFD_Matrix_CH_V600_202502: length=8, minimum-delay=0, transmission-mode-false-timing=cyclic-timing={time-offset=0, time-period=0.02}, transmission-mode-true-timing=cyclic-timing={time-offset=0, time-period=0.02}, unused-bit-pattern=0
            signal Checksum_0B2_oIBS_Status_01_oATOM_CANFD_Matrix_CH_V600_202502: start 7, 8 bit, big-endian, i-signal-type=PRIMITIVE, init-value=0, base-type=uint8, compu {identical}, range raw 0..255, transfer-property=PENDING, to VCU  # Checksum signal for frame
            signal MessageCounter_0B2_oIBS_Status_01_oATOM_CANFD_Matrix_CH_V600_202502: start 11, 4 bit, big-endian, i-signal-type=PRIMITIVE, init-value=0, base-type=uint8, compu {15=CxF_Invalid}, range raw 0..15, transfer-property=PENDING, to VCU  # Message counter signal for frame
            signal IBS_MasterCylinderPressure_oIBS_Status_01_oATOM_CANFD_Matrix_CH_V600_202502: start 19, 12 bit, big-endian, i-signal-type=PRIMITIVE, init-value=0, base-type=uint16, compu {phys=raw*0.1 for raw 0..2500; unit BAR}, range raw 0..2500, unit=BAR, transfer-property=PENDING, to VCU  # EN: Master Cylinder Pressure signal
            signal IBS_BrakePedalStatusValid_oIBS_Status_01_oATOM_CANFD_Matrix_CH_V600_202502: start 21, 1 bit, big-endian, i-signal-type=PRIMITIVE, init-value=1, base-type=boolean, compu {0=Cx0_Invalid, 1=Cx1_Valid}, range raw 0..1, transfer-property=PENDING, to VCU  # Brake Pedal Status Valid
            signal IBS_BrakePedalStatus_oIBS_Status_01_oATOM_CANFD_Matrix_CH_V600_202502: start 23, 2 bit, big-endian, i-signal-type=PRIMITIVE, init-value=0, base-type=uint8, compu {0=Cx0_NOT_PRESSED_INIT_DEFAULT, 1=Cx1_PRESSED, 2=Cx2_RESERVED, 3=Cx3_ERROR}, range raw 0..3, transfer-property=PENDING, to VCU  # Brake Pedal Status
            signal IBS_PlungerPressure_oIBS_Status_01_oATOM_CANFD_Matrix_CH_V600_202502: start 36, 12 bit, big-endian, i-signal-type=PRIMITIVE, init-value=0, base-type=sint16, compu {phys=raw*0.1-5 for raw 0..2047; unit BAR}, range raw 0..2047, unit=BAR, transfer-property=PENDING, to VCU  # pressure of PSU
            signal IBS_BrakePushrodStroke_oIBS_Status_01_oATOM_CANFD_Matrix_CH_V600_202502: start 55, 12 bit, big-endian, i-signal-type=PRIMITIVE, init-value=0, base-type=sint16, compu {phys=raw/64-5 for raw 0..2047; unit mm}, range raw 0..2047, unit=mm, transfer-property=PENDING, to VCU  # IBS pushrod stroke
            mapping SG_IBS_Status_01_SigGroup: i-signal-group=SG_IBS_Status_01_SigGroup_oIBS_Status_01_oATOM_CANFD_Matrix_CH_V600_202502, transfer-property=PENDING
        frame IBS_Status_02_oATOM_CANFD_Matrix_CH_V600_202502: id 0xB3, to VCU, frame-length=8, can-addressing-mode=STANDARD, can-frame-rx-behavior=ANY, can-frame-tx-behavior=CAN-FD
          pdu IBS_Status_02_oATOM_CANFD_Matrix_CH_V600_202502: length=8, minimum-delay=0, transmission-mode-false-timing=cyclic-timing={time-offset=0, time-period=0.02}, transmission-mode-true-timing=cyclic-timing={time-offset=0, time-period=0.02}, unused-bit-pattern=0
            signal Checksum_0B3_oIBS_Status_02_oATOM_CANFD_Matrix_CH_V600_202502: start 7, 8 bit, big-endian, i-signal-type=PRIMITIVE, init-value=0, base-type=uint8, compu {identical}, range raw 0..255, transfer-property=PENDING, to VCU  # Checksum signal for frame
            signal MessageCounter_0B3_oIBS_Status_02_oATOM_CANFD_Matrix_CH_V600_202502: start 11, 4 bit, big-endian, i-signal-type=PRIMITIVE, init-value=0, base-type=uint8, compu {15=CxF_Invalid}, range raw 0..15, transfer-property=PENDING, to VCU  # Message counter signal for frame
            signal IBS_EPBworkingSts_oIBS_Status_02_oATOM_CANFD_Matrix_CH_V600_202502: start 19, 3 bit, big-endian, i-signal-type=PRIMITIVE, init-value=0, base-type=uint8, compu {0=Cx0_UNKNOWN, 1=Cx1_APPLIED, 2=Cx2_RELEASED, 3=Cx3_APPLY_IN_PROGRESS (APPLY IN PROGRESS), 4=Cx4_RELEASE_IN_PROGRESS (RELEASE IN PROGRESS), 5=Cx5_COMPLETELY_RELEASED (COMPLETELY RELEASED), 6=Cx6_DYNAMIC_APPLY (DYNAMIC APPLY), 7=Cx7_RESERVED}, range raw 0..7, transfer-property=PENDING, to VCU  # EN: EPB Status
            signal IBS_BrakeLightRequest_oIBS_Status_02_oATOM_CANFD_Matrix_CH_V600_202502: start 21, 2 bit, big-endian, i-signal-type=PRIMITIVE, init-value=0, base-type=uint8, compu {0=Cx0_brakelightOFF, 1=Cx1_brakelightON, 2=Cx2_notused, 3=Cx3_signalnotavailable}, range raw 0..3, transfer-property=PENDING, to VCU  # EN: IBS request to turn on the stop lamp when the active braking is triggered
            signal IBS_EPBFailureLamp_oIBS_Status_02_oATOM_CANFD_Matrix_CH_V600_202502: start 23, 2 bit, big-endian, i-signal-type=PRIMITIVE, init-value=0, base-type=uint8, compu {0=Cx0_LampOFF, 1=Cx1_LampON}, range raw 0..1, transfer-property=PENDING, to VCU  # EN: EPB Failure Lamp
            signal IBS_HHCAvailable_oIBS_Status_02_oATOM_CANFD_Matrix_CH_V600_202502: start 24, 1 bit, big-endian, i-signal-type=PRIMITIVE, init-value=0, base-type=boolean, compu {0=Cx0_NOT_AVAILABLE, 1=Cx1_AVAILABLE}, range raw 0..1, transfer-property=PENDING, to VCU  # EN: HHC Function Available
            signal IBS_HHCActive_oIBS_Status_02_oATOM_CANFD_Matrix_CH_V600_202502: start 25, 1 bit, big-endian, i-signal-type=PRIMITIVE, init-value=0, base-type=boolean, compu {0=Cx0_notactive, 1=Cx1_active}, range raw 0..1, transfer-property=PENDING, to VCU  # EN: HHC Function Active
            signal IBS_AEBActive_oIBS_Status_02_oATOM_CANFD_Matrix_CH_V600_202502: start 26, 1 bit, big-endian, i-signal-type=PRIMITIVE, init-value=0, base-type=boolean, compu {0=Cx0_notactive, 1=Cx1_active}, range raw 0..1, transfer-property=PENDING, to VCU  # EN: AEB Function Active
            signal IBS_HDCAvailable_oIBS_Status_02_oATOM_CANFD_Matrix_CH_V600_202502: start 27, 1 bit, big-endian, i-signal-type=PRIMITIVE, init-value=0, base-type=boolean, compu {0=Cx0_NOT_AVAILABLE, 1=Cx1_AVAILABLE}, range raw 0..1, transfer-property=PENDING, to VCU  # EN: HDC Function Available
            signal IBS_VDCActive_oIBS_Status_02_oATOM_CANFD_Matrix_CH_V600_202502: start 30, 1 bit, big-endian, i-signal-type=PRIMITIVE, init-value=0, base-type=boolean, compu {0=Cx0_NotActive, 1=Cx1_Active}, range raw 0..1, transfer-property=PENDING, to VCU  # EN: indicates VDC intervention active, ESP will detect other vehicle slip/slide situations, and brake individual wheels to counteract the vehicle slid
            signal IBS_TCSActive_oIBS_Status_02_oATOM_CANFD_Matrix_CH_V600_202502: start 31, 1 bit, big-endian, i-signal-type=PRIMITIVE, init-value=0, base-type=boolean, compu {0=Cx0_NotActive, 1=Cx1_Active}, range raw 0..1, transfer-property=PENDING, to VCU  # EN: Tindicates TCS intervention active,TCS will detect spinning wheels and request torque reduction/limitation
            signal IBS_AWBAvailable_oIBS_Status_02_oATOM_CANFD_Matrix_CH_V600_202502: start 32, 1 bit, big-endian, i-signal-type=PRIMITIVE, init-value=0, base-type=boolean, compu {0=Cx0_NOT_AVAILABLE, 1=Cx1_AVAILABLE}, range raw 0..1, transfer-property=PENDING, to VCU  # AWB is available or not
            signal IBS_AEBAvailable_oIBS_Status_02_oATOM_CANFD_Matrix_CH_V600_202502: start 33, 1 bit, big-endian, i-signal-type=PRIMITIVE, init-value=0, base-type=boolean, compu {0=Cx0_NOT_AVAILABLE, 1=Cx1_AVAILABLE}, range raw 0..1, transfer-property=PENDING, to VCU  # Information indicating whether braking control for AEB is possible or not
            signal IBS_EPBFunctionLamp_oIBS_Status_02_oATOM_CANFD_Matrix_CH_V600_202502: start 35, 2 bit, big-endian, i-signal-type=PRIMITIVE, init-value=0, base-type=uint8, compu {0=Cx0_LampOFF, 1=Cx1_LampON, 2=Cx2_flash, 3=Cx3_Invalid}, range raw 0..3, transfer-property=PENDING, to VCU  # EN: EPB Function Lamp
            signal IBS_AWBActive_oIBS_Status_02_oATOM_CANFD_Matrix_CH_V600_202502: start 36, 1 bit, big-endian, i-signal-type=PRIMITIVE, init-value=0, base-type=boolean, compu {0=Cx0_NotActive, 1=Cx1_Active}, range raw 0..1, transfer-property=PENDING, to VCU  # AWB is active or not
            signal IBS_HazWarnReq_oIBS_Status_02_oATOM_CANFD_Matrix_CH_V600_202502: start 38, 2 bit, big-endian, i-signal-type=PRIMITIVE, init-value=0, base-type=uint8, compu {0=Cx0_OFF, 1=Cx1_ON, 2=Cx2_Signalnotavailable}, range raw 0..2, transfer-property=PENDING, to VCU  # EN: Hazard warning Lamps
            signal IBS_AVHAvailable_oIBS_Status_02_oATOM_CANFD_Matrix_CH_V600_202502: start 39, 1 bit, big-endian, i-signal-type=PRIMITIVE, init-value=0, base-type=boolean, compu {0=Cx0_NOT_AVAILABLE, 1=Cx1_AVAILABLE}, range raw 0..1, transfer-property=PENDING, to VCU  # EN: AVH Function Available
            signal IBS_EPBControllerSts_oIBS_Status_02_oATOM_CANFD_Matrix_CH_V600_202502: start 47, 2 bit, big-endian, i-signal-type=PRIMITIVE, init-value=0, base-type=uint8, compu {0=Cx0_MasterMode, 1=Cx1_SlaveMode}, range raw 0..1, transfer-property=PENDING, to VCU  # Primary controller switchover status of an EPB
            mapping SG_IBS_Status_02_SigGroup: i-signal-group=SG_IBS_Status_02_SigGroup_oIBS_Status_02_oATOM_CANFD_Matrix_CH_V600_202502, transfer-property=PENDING
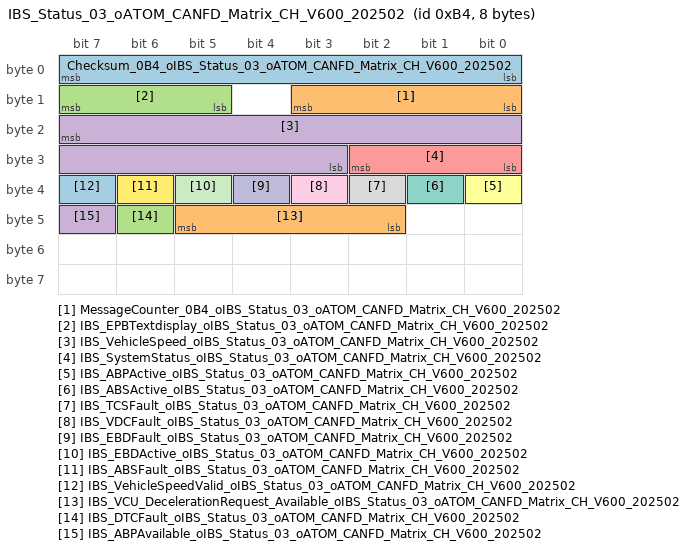
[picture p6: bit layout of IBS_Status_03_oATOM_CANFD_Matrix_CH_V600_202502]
        frame IBS_Status_03_oATOM_CANFD_Matrix_CH_V600_202502: id 0xB4, to VCU, frame-length=8, can-addressing-mode=STANDARD, can-frame-rx-behavior=ANY, can-frame-tx-behavior=CAN-FD
          pdu IBS_Status_03_oATOM_CANFD_Matrix_CH_V600_202502: length=8, minimum-delay=0, transmission-mode-false-timing=cyclic-timing={time-offset=0, time-period=0.02}, transmission-mode-true-timing=cyclic-timing={time-offset=0, time-period=0.02}, unused-bit-pattern=0
            signal Checksum_0B4_oIBS_Status_03_oATOM_CANFD_Matrix_CH_V600_202502: start 7, 8 bit, big-endian, i-signal-type=PRIMITIVE, init-value=0, base-type=uint8, compu {identical}, range raw 0..255, transfer-property=PENDING, to VCU  # Checksum signal for frame
            signal MessageCounter_0B4_oIBS_Status_03_oATOM_CANFD_Matrix_CH_V600_202502: start 11, 4 bit, big-endian, i-signal-type=PRIMITIVE, init-value=0, base-type=uint8, compu {15=CxF_Invalid}, range raw 0..15, transfer-property=PENDING, to VCU  # Message counter signal for frame
            signal IBS_EPBTextdisplay_oIBS_Status_03_oATOM_CANFD_Matrix_CH_V600_202502: start 15, 3 bit, big-endian, i-signal-type=PRIMITIVE, init-value=0, base-type=uint8, compu {0=Cx0_Off, 1=Cx1_Park_Brake_Applied (Park Brake Applied), 2=Cx2_Park_Brake_Released (Park Brake Released), 3=Cx3_Parking_brake_malfunction_Visit_service_center_to_fix_the_issue (Parking brake malfunction.Visit service center to fix the issue), 4=Cx4_Reserve}, range raw 0..4, transfer-property=PENDING, to VCU  # EN: EPB Text display
            signal IBS_VehicleSpeed_oIBS_Status_03_oATOM_CANFD_Matrix_CH_V600_202502: start 23, 13 bit, big-endian, i-signal-type=PRIMITIVE, init-value=0, base-type=uint16, compu {phys=raw*0.05625 for raw 0..6400; unit km/h}, range raw 0..6400, unit=km/h, transfer-property=PENDING, to VCU  # EN: Vehicle speed
            signal IBS_SystemStatus_oIBS_Status_03_oATOM_CANFD_Matrix_CH_V600_202502: start 26, 3 bit, big-endian, i-signal-type=PRIMITIVE, init-value=0, base-type=uint8, compu {0=Cx0_Normal, 1=Cx1_Degrade, 2=Cx2_Partial, 3=Cx3_Inhibit, 4=Cx4_Reserved, 5=Cx5_Reserved, 6=Cx6_Reserved, 7=Cx7_Reserved}, range raw 0..7, transfer-property=PENDING, to VCU  # IBS System Status
            signal IBS_ABPActive_oIBS_Status_03_oATOM_CANFD_Matrix_CH_V600_202502: start 32, 1 bit, big-endian, i-signal-type=PRIMITIVE, init-value=0, base-type=boolean, compu {0=Cx0_INACTIVE, 1=Cx1_ACTIVE}, range raw 0..1, transfer-property=PENDING, to VCU  # Prefill(ABP) is active or not.
            signal IBS_ABSActive_oIBS_Status_03_oATOM_CANFD_Matrix_CH_V600_202502: start 33, 1 bit, big-endian, i-signal-type=PRIMITIVE, init-value=0, base-type=boolean, compu {0=Cx0_Not_Active (Not Active), 1=Cx1_Active}, range raw 0..1, transfer-property=PENDING, to VCU  # indicates ABS intervention active.
            signal IBS_TCSFault_oIBS_Status_03_oATOM_CANFD_Matrix_CH_V600_202502: start 34, 1 bit, big-endian, i-signal-type=PRIMITIVE, init-value=0, base-type=boolean, compu {0=Cx0_Noerror, 1=Cx1_Error}, range raw 0..1, transfer-property=PENDING, to VCU  # EN: TCS status valid
            signal IBS_VDCFault_oIBS_Status_03_oATOM_CANFD_Matrix_CH_V600_202502: start 35, 1 bit, big-endian, i-signal-type=PRIMITIVE, init-value=0, base-type=boolean, compu {0=Cx0_Noerror, 1=Cx1_Error}, range raw 0..1, transfer-property=PENDING, to VCU  # EN: VDC status valid
            signal IBS_EBDFault_oIBS_Status_03_oATOM_CANFD_Matrix_CH_V600_202502: start 36, 1 bit, big-endian, i-signal-type=PRIMITIVE, init-value=0, base-type=boolean, compu {0=Cx0_Noerror, 1=Cx1_Error}, range raw 0..1, transfer-property=PENDING, to VCU  # ABS system has detected a heavy fault, which does not even allow a reliable electronic brake distribution and is therefore completely shut down.
            signal IBS_EBDActive_oIBS_Status_03_oATOM_CANFD_Matrix_CH_V600_202502: start 37, 1 bit, big-endian, i-signal-type=PRIMITIVE, init-value=0, base-type=boolean, compu {0=Cx0_Not_Active (Not Active), 1=Cx1_Active}, range raw 0..1, transfer-property=PENDING, to VCU  # EBD Active Status
            signal IBS_ABSFault_oIBS_Status_03_oATOM_CANFD_Matrix_CH_V600_202502: start 38, 1 bit, big-endian, i-signal-type=PRIMITIVE, init-value=0, base-type=boolean, compu {0=Cx0_Noerror, 1=Cx1_Error}, range raw 0..1, transfer-property=PENDING, to VCU  # ABS system has detected a failure which does not allow a reliable ABS regulation and is therefore switched off.
            signal IBS_VehicleSpeedValid_oIBS_Status_03_oATOM_CANFD_Matrix_CH_V600_202502: start 39, 1 bit, big-endian, i-signal-type=PRIMITIVE, init-value=0, base-type=boolean, compu {0=Cx0_Invalid, 1=Cx1_Valid}, range raw 0..1, transfer-property=PENDING, to VCU  # EN: Vehicle speed valid
            signal IBS_VCU_DecelerationRequest_Available_oIBS_Status_03_oATOM_CANFD_Matrix_CH_V600_202502: start 45, 4 bit, big-endian, i-signal-type=PRIMITIVE, init-value=0, base-type=uint8, compu {0=Cx0_Available, 1=Cx1_Not_Available (Not Available), 2=Cx2_Reserved, 3=Cx3_Reserved}, range raw 0..3, transfer-property=PENDING, to VCU  # Indicates whether the VCU-related deceleration request function is available
            signal IBS_DTCFault_oIBS_Status_03_oATOM_CANFD_Matrix_CH_V600_202502: start 46, 1 bit, big-endian, i-signal-type=PRIMITIVE, init-value=0, base-type=boolean, compu {0=Cx0_Noerror, 1=Cx1_Error}, range raw 0..1, transfer-property=PENDING, to VCU  # Drag Torque Control fault
            signal IBS_ABPAvailable_oIBS_Status_03_oATOM_CANFD_Matrix_CH_V600_202502: start 47, 1 bit, big-endian, i-signal-type=PRIMITIVE, init-value=0, base-type=boolean, compu {0=Cx0_NOT_AVAILABLE, 1=Cx1_AVAILABLE}, range raw 0..1, transfer-property=PENDING, to VCU  # Prefill(ABP) is available or not.
            mapping SG_IBS_Status_03_SigGroup: i-signal-group=SG_IBS_Status_03_SigGroup_oIBS_Status_03_oATOM_CANFD_Matrix_CH_V600_202502, transfer-property=PENDING
        frame IBS_Status_04_oATOM_CANFD_Matrix_CH_V600_202502: id 0xBA, to VCU, frame-length=8, can-addressing-mode=STANDARD, can-frame-rx-behavior=ANY, can-frame-tx-behavior=CAN-FD
          pdu IBS_Status_04_oATOM_CANFD_Matrix_CH_V600_202502: length=8, minimum-delay=0, transmission-mode-false-timing=cyclic-timing={time-offset=0, time-period=0.02}, transmission-mode-true-timing=cyclic-timing={time-offset=0, time-period=0.02}, unused-bit-pattern=0
            signal Checksum_0BA_oIBS_Status_04_oATOM_CANFD_Matrix_CH_V600_202502: start 7, 8 bit, big-endian, i-signal-type=PRIMITIVE, init-value=0, base-type=uint8, compu {identical}, range raw 0..255, transfer-property=PENDING, to VCU  # Checksum signal for frame
            signal MessageCounter_0BA_oIBS_Status_04_oATOM_CANFD_Matrix_CH_V600_202502: start 11, 4 bit, big-endian, i-signal-type=PRIMITIVE, init-value=0, base-type=uint8, compu {15=CxF_Invalid}, range raw 0..15, transfer-property=PENDING, to VCU  # Message counter signal for frame
            signal IBS_DTCActive_oIBS_Status_04_oATOM_CANFD_Matrix_CH_V600_202502: start 21, 1 bit, big-endian, i-signal-type=PRIMITIVE, init-value=0, base-type=boolean, compu {0=Cx0_Not_Active (Not Active), 1=Cx1_Active}, range raw 0..1, transfer-property=PENDING, to VCU  # Drag Torque Control
            signal IBS_CDPAvailable_oIBS_Status_04_oATOM_CANFD_Matrix_CH_V600_202502: start 22, 1 bit, big-endian, i-signal-type=PRIMITIVE, init-value=0, base-type=boolean, compu {0=Cx0_NOT_AVAILABLE, 1=Cx1_AVAILABLE}, range raw 0..1, transfer-property=PENDING, to VCU  # EN: CDP Function Available
            signal IBS_CDPActive_oIBS_Status_04_oATOM_CANFD_Matrix_CH_V600_202502: start 23, 1 bit, big-endian, i-signal-type=PRIMITIVE, init-value=0, base-type=boolean, compu {0=Cx0_Not_Active (Not Active), 1=Cx1_Active}, range raw 0..1, transfer-property=PENDING, to VCU  # Indicate CDP Control Active
            mapping SG_IBS_Status_04_SigGroup: i-signal-group=SG_IBS_Status_04_SigGroup_oIBS_Status_04_oATOM_CANFD_Matrix_CH_V600_202502, transfer-property=PENDING
        frame IBS_Status_06_oATOM_CANFD_Matrix_CH_V600_202502: id 0xBC, to VCU, frame-length=8, can-addressing-mode=STANDARD, can-frame-rx-behavior=ANY, can-frame-tx-behavior=CAN-FD
          pdu IBS_Status_06_oATOM_CANFD_Matrix_CH_V600_202502: length=8, minimum-delay=0, transmission-mode-false-timing=cyclic-timing={time-offset=0, time-period=0.02}, transmission-mode-true-timing=cyclic-timing={time-offset=0, time-period=0.02}, unused-bit-pattern=0
            signal Checksum_0BC_oIBS_Status_06_oATOM_CANFD_Matrix_CH_V600_202502: start 7, 8 bit, big-endian, i-signal-type=PRIMITIVE, init-value=0, base-type=uint8, compu {identical}, range raw 0..255, transfer-property=PENDING, to VCU  # Checksum signal for frame
            signal MessageCounter_0BC_oIBS_Status_06_oATOM_CANFD_Matrix_CH_V600_202502: start 11, 4 bit, big-endian, i-signal-type=PRIMITIVE, init-value=0, base-type=uint8, compu {15=CxF_Invalid}, range raw 0..15, transfer-property=PENDING, to VCU  # Message counter signal for frame
            signal IBS_FactoryMode_oIBS_Status_06_oATOM_CANFD_Matrix_CH_V600_202502: start 40, 1 bit, big-endian, i-signal-type=PRIMITIVE, init-value=0, base-type=boolean, compu {0=Cx0_Not_Active (Not Active), 1=Cx1_Active}, range raw 0..1, transfer-property=PENDING, to VCU  # Factory Mode Status
            signal IBS_RollerbenchMode_oIBS_Status_06_oATOM_CANFD_Matrix_CH_V600_202502: start 41, 1 bit, big-endian, i-signal-type=PRIMITIVE, init-value=0, base-type=boolean, compu {0=Cx0_Not_Active (Not Active), 1=Cx1_Active}, range raw 0..1, transfer-property=PENDING, to VCU  # Rollerbench Mode Status
            signal IBS_MaintenaceMode_oIBS_Status_06_oATOM_CANFD_Matrix_CH_V600_202502: start 42, 1 bit, big-endian, i-signal-type=PRIMITIVE, init-value=0, base-type=boolean, compu {0=Cx0_Not_Active (Not Active), 1=Cx1_Active}, range raw 0..1, transfer-property=PENDING, to VCU  # Maintenace Mode Status
            signal IBS_RWUAvailable_oIBS_Status_06_oATOM_CANFD_Matrix_CH_V600_202502: start 43, 1 bit, big-endian, i-signal-type=PRIMITIVE, init-value=0, base-type=boolean, compu {0=Cx0_NOT_AVAILABLE, 1=Cx1_AVAILABLE}, range raw 0..1, transfer-property=PENDING, to VCU  # EN: RWU Function Available
            signal IBS_RWUActive_oIBS_Status_06_oATOM_CANFD_Matrix_CH_V600_202502: start 44, 1 bit, big-endian, i-signal-type=PRIMITIVE, init-value=0, base-type=boolean, compu {0=Cx0_Not_Active (Not Active), 1=Cx1_Active}, range raw 0..1, transfer-property=PENDING, to VCU  # Indicate RWU Control Active
            signal IBS_ESCOffSts_oIBS_Status_06_oATOM_CANFD_Matrix_CH_V600_202502: start 45, 1 bit, big-endian, i-signal-type=PRIMITIVE, init-value=1, base-type=boolean, compu {0=Cx0_ESC_OFF (ESC OFF), 1=Cx1_ESC_ON (ESC ON)}, range raw 0..1, transfer-property=PENDING, to VCU  # ESC OFF Status
            signal IBS_HBAActive_oIBS_Status_06_oATOM_CANFD_Matrix_CH_V600_202502: start 46, 1 bit, big-endian, i-signal-type=PRIMITIVE, init-value=0, base-type=boolean, compu {0=Cx0_Not_Active (Not Active), 1=Cx1_Active}, range raw 0..1, transfer-property=PENDING, to VCU  # HBA Active Status
            signal IBS_BrakeFluidWarning_oIBS_Status_06_oATOM_CANFD_Matrix_CH_V600_202502: start 49, 2 bit, big-endian, i-signal-type=PRIMITIVE, init-value=0, base-type=uint8, compu {0=Cx0_BRAKEFLUID_NORMAL_INIT_DEFAULT, 1=Cx1_BRAKEFLUID_EMPTY, 2=Cx2_RESERVED, 3=Cx3_RESERVED}, range raw 0..3, transfer-property=PENDING, to VCU  # Brake Fluid Warning
            signal IBS_HDCSts_oIBS_Status_06_oATOM_CANFD_Matrix_CH_V600_202502: start 51, 2 bit, big-endian, i-signal-type=PRIMITIVE, init-value=0, base-type=uint8, compu {0=Cx0_OFF, 1=Cx1_STANDBY, 2=Cx2_ACTIVE}, range raw 0..2, transfer-property=PENDING, to VCU  # Indicates HDC in Active or Off
            signal IBS_ESClampdisplay_oIBS_Status_06_oATOM_CANFD_Matrix_CH_V600_202502: start 53, 2 bit, big-endian, i-signal-type=PRIMITIVE, init-value=0, base-type=uint8, compu {0=Cx0_ESC_lamp_ON (ESC lamp ON), 1=Cx1_ESC_lamp_OFF (ESC lamp OFF), 2=Cx2_ESC_lamp_FLASH (ESC lamp FLASH)}, range raw 0..2, transfer-property=PENDING, to VCU  # ESC function lamp display for IVI
            signal IBS_AVHSts_oIBS_Status_06_oATOM_CANFD_Matrix_CH_V600_202502: start 55, 2 bit, big-endian, i-signal-type=PRIMITIVE, init-value=0, base-type=uint8, compu {0=Cx0_OFF, 1=Cx1_STANDBY, 2=Cx2_ACTIVE}, range raw 0..2, transfer-property=PENDING, to VCU  # Indicates AVH in Active or Standby or Off
            signal IBS_TireWarnFrntRi_oIBS_Status_06_oATOM_CANFD_Matrix_CH_V600_202502: start 56, 1 bit, big-endian, i-signal-type=PRIMITIVE, init-value=0, base-type=boolean, compu {0=Cx0_Normal, 1=Cx1_Abnormal}, range raw 0..1, transfer-property=PENDING, to VCU  # Alarm status at right rear
            signal IBS_TireWarnFrntLe_oIBS_Status_06_oATOM_CANFD_Matrix_CH_V600_202502: start 57, 1 bit, big-endian, i-signal-type=PRIMITIVE, init-value=0, base-type=boolean, compu {0=Cx0_Normal, 1=Cx1_Abnormal}, range raw 0..1, transfer-property=PENDING, to VCU  # Alarm status at left front
            signal IBS_TireWarnReRi_oIBS_Status_06_oATOM_CANFD_Matrix_CH_V600_202502: start 58, 1 bit, big-endian, i-signal-type=PRIMITIVE, init-value=0, base-type=boolean, compu {0=Cx0_Normal, 1=Cx1_Abnormal}, range raw 0..1, transfer-property=PENDING, to VCU  # Alarm status at right rear
            signal IBS_TireWarnReLe_oIBS_Status_06_oATOM_CANFD_Matrix_CH_V600_202502: start 59, 1 bit, big-endian, i-signal-type=PRIMITIVE, init-value=0, base-type=boolean, compu {0=Cx0_Normal, 1=Cx1_Abnormal}, range raw 0..1, transfer-property=PENDING, to VCU  # Alarm status at left rear
            signal IBS_TPMS_ResetSts_oIBS_Status_06_oATOM_CANFD_Matrix_CH_V600_202502: start 60, 1 bit, big-endian, i-signal-type=PRIMITIVE, init-value=0, base-type=boolean, compu {0=Cx0_OFF, 1=Cx1_ON}, range raw 0..1, transfer-property=PENDING, to VCU  # Reset TPMS status
            signal IBS_TireMonSysSts_oIBS_Status_06_oATOM_CANFD_Matrix_CH_V600_202502: start 61, 1 bit, big-endian, i-signal-type=PRIMITIVE, init-value=1, base-type=boolean, compu {0=Cx0_System_not_OK (System not OK), 1=Cx1_System_OK (System OK)}, range raw 0..1, transfer-property=PENDING, to VCU  # TMPS system status
            signal IBS_EPBFailureStatus_oIBS_Status_06_oATOM_CANFD_Matrix_CH_V600_202502: start 63, 2 bit, big-endian, i-signal-type=PRIMITIVE, init-value=0, base-type=uint8, compu {0=Cx0_No_error (No error), 1=Cx1_error, 2=Cx2_Reserve, 3=Cx3_Reserve}, range raw 0..3, transfer-property=PENDING, to VCU  # EPB failure status
            mapping SG_IBS_Status_06_SigGroup: i-signal-group=SG_IBS_Status_06_SigGroup_oIBS_Status_06_oATOM_CANFD_Matrix_CH_V600_202502, transfer-property=PENDING
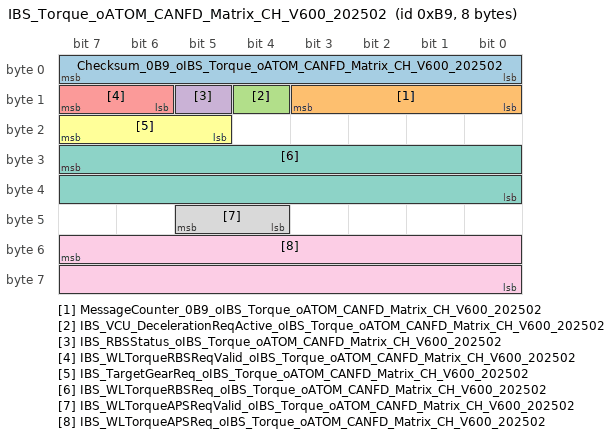
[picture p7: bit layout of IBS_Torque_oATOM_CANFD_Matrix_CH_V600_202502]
        frame IBS_Torque_oATOM_CANFD_Matrix_CH_V600_202502: id 0xB9, to VCU, frame-length=8, can-addressing-mode=STANDARD, can-frame-rx-behavior=ANY, can-frame-tx-behavior=CAN-FD
          pdu IBS_Torque_oATOM_CANFD_Matrix_CH_V600_202502: length=8, minimum-delay=0, transmission-mode-false-timing=cyclic-timing={time-offset=0, time-period=0.02}, transmission-mode-true-timing=cyclic-timing={time-offset=0, time-period=0.02}, unused-bit-pattern=0
            signal Checksum_0B9_oIBS_Torque_oATOM_CANFD_Matrix_CH_V600_202502: start 7, 8 bit, big-endian, i-signal-type=PRIMITIVE, init-value=0, base-type=uint8, compu {identical}, range raw 0..255, transfer-property=PENDING, to VCU  # Checksum signal for frame
            signal MessageCounter_0B9_oIBS_Torque_oATOM_CANFD_Matrix_CH_V600_202502: start 11, 4 bit, big-endian, i-signal-type=PRIMITIVE, init-value=0, base-type=uint8, compu {15=CxF_Invalid}, range raw 0..15, transfer-property=PENDING, to VCU  # Message counter signal for frame
            signal IBS_VCU_DecelerationReqActive_oIBS_Torque_oATOM_CANFD_Matrix_CH_V600_202502: start 12, 1 bit, big-endian, i-signal-type=PRIMITIVE, init-value=0, base-type=boolean, compu {0=Cx0_NotActive, 1=Cx1_Active}, range raw 0..1, transfer-property=PENDING, to VCU  # IBS activation signal in response to VCU deceleration request
            signal IBS_RBSStatus_oIBS_Torque_oATOM_CANFD_Matrix_CH_V600_202502: start 13, 1 bit, big-endian, i-signal-type=PRIMITIVE, init-value=0, base-type=boolean, compu {0=Cx0_NotActive, 1=Cx1_Active}, range raw 0..1, transfer-property=PENDING, to VCU  # EN: Energy recovery status
            signal IBS_WLTorqueRBSReqValid_oIBS_Torque_oATOM_CANFD_Matrix_CH_V600_202502: start 15, 2 bit, big-endian, i-signal-type=PRIMITIVE, init-value=0, base-type=uint8, compu {0=Cx0_NotIntialized, 1=Cx1_Normal, 2=Cx2_Faulty}, range raw 0..2, transfer-property=PENDING, to VCU  # EN: CRBS wheel torque request valid
            signal IBS_TargetGearReq_oIBS_Torque_oATOM_CANFD_Matrix_CH_V600_202502: start 23, 3 bit, big-endian, i-signal-type=PRIMITIVE, init-value=0, base-type=uint8, compu {0=Cx0_No_Request (No Request), 1=Cx1_P, 2=Cx2_N, 3=Cx3_R, 4=Cx4_D}, range raw 0..4, transfer-property=PENDING, to VCU  # IBS fotwarded APS Gear request
            signal IBS_WLTorqueRBSReq_oIBS_Torque_oATOM_CANFD_Matrix_CH_V600_202502: start 31, 16 bit, big-endian, i-signal-type=PRIMITIVE, init-value=0, base-type=uint16, compu {phys=raw-20000 for raw 0..40000; unit Nm}, range raw 0..40000, unit=Nm, transfer-property=PENDING, to VCU  # EN: CRBS wheel torque request
            signal IBS_WLTorqueAPSReqValid_oIBS_Torque_oATOM_CANFD_Matrix_CH_V600_202502: start 45, 2 bit, big-endian, i-signal-type=PRIMITIVE, init-value=0, base-type=uint8, compu {0=Cx0_NotIntialized, 1=Cx1_Normal, 2=Cx2_Faulty}, range raw 0..2, transfer-property=PENDING, to VCU  # APS wheel torque request valid
            signal IBS_WLTorqueAPSReq_oIBS_Torque_oATOM_CANFD_Matrix_CH_V600_202502: start 55, 16 bit, big-endian, i-signal-type=PRIMITIVE, init-value=0, base-type=uint16, compu {phys=raw-20000 for raw 0..40000; unit Nm}, range raw 0..40000, unit=Nm, transfer-property=PENDING, to VCU  # APS wheel torque request
            mapping SG_IBS_Torque_SigGroup: i-signal-group=SG_IBS_Torque_SigGroup_oIBS_Torque_oATOM_CANFD_Matrix_CH_V600_202502, transfer-property=PENDING
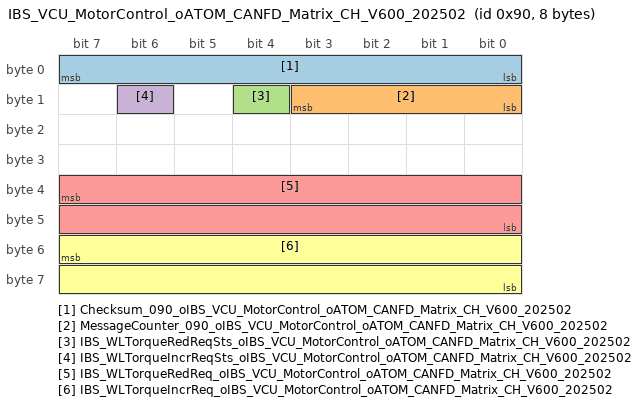
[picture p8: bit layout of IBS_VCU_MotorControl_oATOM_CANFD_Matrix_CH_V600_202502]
        frame IBS_VCU_MotorControl_oATOM_CANFD_Matrix_CH_V600_202502: id 0x90, to VCU, frame-length=8, can-addressing-mode=STANDARD, can-frame-rx-behavior=ANY, can-frame-tx-behavior=CAN-FD
          pdu IBS_VCU_MotorControl_oATOM_CANFD_Matrix_CH_V600_202502: length=8, minimum-delay=0, transmission-mode-false-timing=cyclic-timing={time-offset=0, time-period=0.01}, transmission-mode-true-timing=cyclic-timing={time-offset=0, time-period=0.01}, unused-bit-pattern=0
            signal Checksum_090_oIBS_VCU_MotorControl_oATOM_CANFD_Matrix_CH_V600_202502: start 7, 8 bit, big-endian, i-signal-type=PRIMITIVE, init-value=0, base-type=uint8, compu {identical}, range raw 0..255, transfer-property=PENDING, to VCU  # Checksum signal for frame
            signal MessageCounter_090_oIBS_VCU_MotorControl_oATOM_CANFD_Matrix_CH_V600_202502: start 11, 4 bit, big-endian, i-signal-type=PRIMITIVE, init-value=0, base-type=uint8, compu {15=CxF_Invalid}, range raw 0..15, transfer-property=PENDING, to VCU  # Message counter signal for frame
            signal IBS_WLTorqueRedReqSts_oIBS_VCU_MotorControl_oATOM_CANFD_Matrix_CH_V600_202502: start 12, 1 bit, big-endian, i-signal-type=PRIMITIVE, init-value=0, base-type=boolean, compu {0=Cx0_INACTIVE, 1=Cx1_ACTIVE}, range raw 0..1, transfer-property=PENDING, to VCU  # Wheel torque reduction request status.
            signal IBS_WLTorqueIncrReqSts_oIBS_VCU_MotorControl_oATOM_CANFD_Matrix_CH_V600_202502: start 14, 1 bit, big-endian, i-signal-type=PRIMITIVE, init-value=0, base-type=boolean, compu {0=Cx0_INACTIVE, 1=Cx1_ACTIVE}, range raw 0..1, transfer-property=PENDING, to VCU  # Wheel torque increase request status.
            signal IBS_WLTorqueRedReq_oIBS_VCU_MotorControl_oATOM_CANFD_Matrix_CH_V600_202502: start 39, 16 bit, big-endian, i-signal-type=PRIMITIVE, init-value=0, base-type=uint16, compu {phys=raw-20000 for raw 0..40000; unit Nm}, range raw 0..40000, unit=Nm, transfer-property=PENDING, to VCU  # Wheel torque reduction request.
            signal IBS_WLTorqueIncrReq_oIBS_VCU_MotorControl_oATOM_CANFD_Matrix_CH_V600_202502: start 55, 16 bit, big-endian, i-signal-type=PRIMITIVE, init-value=0, base-type=uint16, compu {phys=raw-20000 for raw 0..40000; unit Nm}, range raw 0..40000, unit=Nm, transfer-property=PENDING, to VCU  # Wheel torque increase request
            mapping SG_IBS_VCU_MotorControl_SigGroup: i-signal-group=SG_IBS_VCU_MotorControl_SigGroup_oIBS_VCU_MotorControl_oATOM_CANFD_Matrix_CH_V600_202502, transfer-property=PENDING
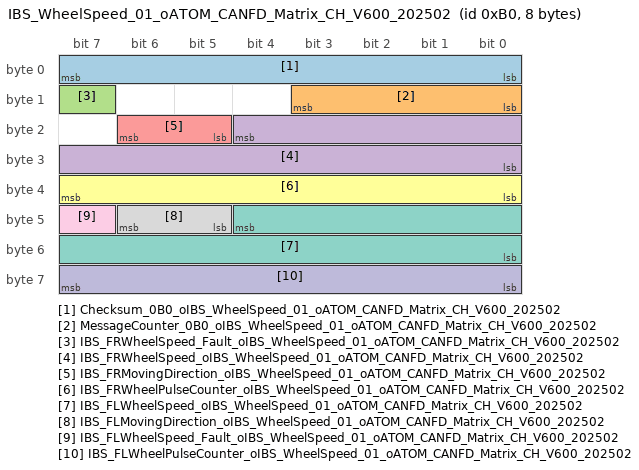
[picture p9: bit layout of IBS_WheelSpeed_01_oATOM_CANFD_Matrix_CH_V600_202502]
        frame IBS_WheelSpeed_01_oATOM_CANFD_Matrix_CH_V600_202502: id 0xB0, to VCU, frame-length=8, can-addressing-mode=STANDARD, can-frame-rx-behavior=ANY, can-frame-tx-behavior=CAN-FD
          pdu IBS_WheelSpeed_01_oATOM_CANFD_Matrix_CH_V600_202502: length=8, minimum-delay=0, transmission-mode-false-timing=cyclic-timing={time-offset=0, time-period=0.02}, transmission-mode-true-timing=cyclic-timing={time-offset=0, time-period=0.02}, unused-bit-pattern=0
            signal Checksum_0B0_oIBS_WheelSpeed_01_oATOM_CANFD_Matrix_CH_V600_202502: start 7, 8 bit, big-endian, i-signal-type=PRIMITIVE, init-value=0, base-type=uint8, compu {identical}, range raw 0..255, transfer-property=PENDING, to VCU  # Checksum signal for frame
            signal MessageCounter_0B0_oIBS_WheelSpeed_01_oATOM_CANFD_Matrix_CH_V600_202502: start 11, 4 bit, big-endian, i-signal-type=PRIMITIVE, init-value=0, base-type=uint8, compu {15=CxF_Invalid}, range raw 0..15, transfer-property=PENDING, to VCU  # Message counter signal for frame
            signal IBS_FRWheelSpeed_Fault_oIBS_WheelSpeed_01_oATOM_CANFD_Matrix_CH_V600_202502: start 15, 1 bit, big-endian, i-signal-type=PRIMITIVE, init-value=0, base-type=boolean, compu {0=Cx0_No_error (No error), 1=Cx1_Error}, range raw 0..1, transfer-property=PENDING, to VCU  # EN: Front right wheel speed signal valid
            signal IBS_FRWheelSpeed_oIBS_WheelSpeed_01_oATOM_CANFD_Matrix_CH_V600_202502: start 20, 13 bit, big-endian, i-signal-type=PRIMITIVE, init-value=0, base-type=uint16, compu {phys=raw*0.05625 for raw 0..6400; unit km/h}, range raw 0..6400, unit=km/h, transfer-property=PENDING, to VCU  # EN: Front right wheel speed
            signal IBS_FRMovingDirection_oIBS_WheelSpeed_01_oATOM_CANFD_Matrix_CH_V600_202502: start 22, 2 bit, big-endian, i-signal-type=PRIMITIVE, init-value=0, base-type=uint8, compu {0=Cx0_Standstill, 1=Cx1_Forward, 2=Cx2_Backward}, range raw 0..2, transfer-property=PENDING, to VCU  # EN: Front right wheel direction
            signal IBS_FRWheelPulseCounter_oIBS_WheelSpeed_01_oATOM_CANFD_Matrix_CH_V600_202502: start 39, 8 bit, big-endian, i-signal-type=PRIMITIVE, init-value=0, base-type=uint8, compu {identical}, range raw 0..255, transfer-property=PENDING, to VCU  # EN: Front right wheel speed pulse
            signal IBS_FLWheelSpeed_oIBS_WheelSpeed_01_oATOM_CANFD_Matrix_CH_V600_202502: start 44, 13 bit, big-endian, i-signal-type=PRIMITIVE, init-value=0, base-type=uint16, compu {phys=raw*0.05625 for raw 0..6400; unit km/h}, range raw 0..6400, unit=km/h, transfer-property=PENDING, to VCU  # EN: Front left wheel speed
            signal IBS_FLMovingDirection_oIBS_WheelSpeed_01_oATOM_CANFD_Matrix_CH_V600_202502: start 46, 2 bit, big-endian, i-signal-type=PRIMITIVE, init-value=0, base-type=uint8, compu {0=Cx0_Standstill, 1=Cx1_Forward, 2=Cx2_Backward}, range raw 0..2, transfer-property=PENDING, to VCU  # EN: Front left wheel direction
            signal IBS_FLWheelSpeed_Fault_oIBS_WheelSpeed_01_oATOM_CANFD_Matrix_CH_V600_202502: start 47, 1 bit, big-endian, i-signal-type=PRIMITIVE, init-value=0, base-type=boolean, compu {0=Cx0_No_error (No error), 1=Cx1_Error}, range raw 0..1, transfer-property=PENDING, to VCU  # EN: Front left wheel speed signal valid
            signal IBS_FLWheelPulseCounter_oIBS_WheelSpeed_01_oATOM_CANFD_Matrix_CH_V600_202502: start 63, 8 bit, big-endian, i-signal-type=PRIMITIVE, init-value=0, base-type=uint8, compu {identical}, range raw 0..255, transfer-property=PENDING, to VCU  # EN: Front left wheel speed pulse
            mapping SG_IBS_WheelSpeed_01_SigGroup: i-signal-group=SG_IBS_WheelSpeed_01_SigGroup_oIBS_WheelSpeed_01_oATOM_CANFD_Matrix_CH_V600_202502, transfer-property=PENDING
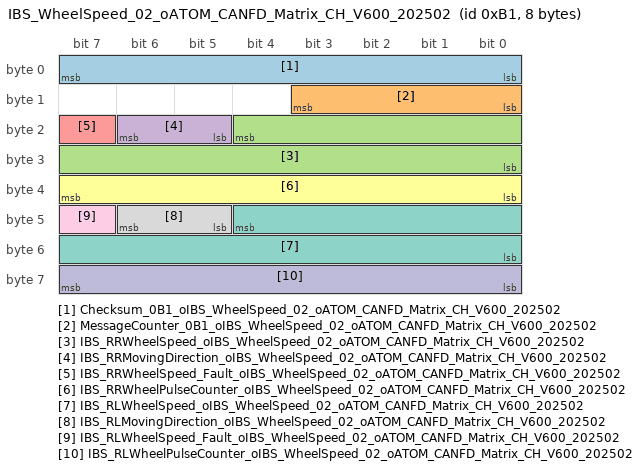
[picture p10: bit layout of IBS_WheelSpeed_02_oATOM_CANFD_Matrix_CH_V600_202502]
        frame IBS_WheelSpeed_02_oATOM_CANFD_Matrix_CH_V600_202502: id 0xB1, to VCU, frame-length=8, can-addressing-mode=STANDARD, can-frame-rx-behavior=ANY, can-frame-tx-behavior=CAN-FD
          pdu IBS_WheelSpeed_02_oATOM_CANFD_Matrix_CH_V600_202502: length=8, minimum-delay=0, transmission-mode-false-timing=cyclic-timing={time-offset=0, time-period=0.02}, transmission-mode-true-timing=cyclic-timing={time-offset=0, time-period=0.02}, unused-bit-pattern=0
            signal Checksum_0B1_oIBS_WheelSpeed_02_oATOM_CANFD_Matrix_CH_V600_202502: start 7, 8 bit, big-endian, i-signal-type=PRIMITIVE, init-value=0, base-type=uint8, compu {identical}, range raw 0..255, transfer-property=PENDING, to VCU  # Checksum signal for frame
            signal MessageCounter_0B1_oIBS_WheelSpeed_02_oATOM_CANFD_Matrix_CH_V600_202502: start 11, 4 bit, big-endian, i-signal-type=PRIMITIVE, init-value=0, base-type=uint8, compu {15=CxF_Invalid}, range raw 0..15, transfer-property=PENDING, to VCU  # Message counter signal for frame
            signal IBS_RRWheelSpeed_oIBS_WheelSpeed_02_oATOM_CANFD_Matrix_CH_V600_202502: start 20, 13 bit, big-endian, i-signal-type=PRIMITIVE, init-value=0, base-type=uint16, compu {phys=raw*0.05625 for raw 0..6400; unit km/h}, range raw 0..6400, unit=km/h, transfer-property=PENDING, to VCU  # EN: Rear right wheel speed
            signal IBS_RRMovingDirection_oIBS_WheelSpeed_02_oATOM_CANFD_Matrix_CH_V600_202502: start 22, 2 bit, big-endian, i-signal-type=PRIMITIVE, init-value=0, base-type=uint8, compu {0=Cx0_Standstill, 1=Cx1_Forward, 2=Cx2_Backward}, range raw 0..2, transfer-property=PENDING, to VCU  # EN: Rear right wheel direction
            signal IBS_RRWheelSpeed_Fault_oIBS_WheelSpeed_02_oATOM_CANFD_Matrix_CH_V600_202502: start 23, 1 bit, big-endian, i-signal-type=PRIMITIVE, init-value=0, base-type=boolean, compu {0=Cx0_No_error (No error), 1=Cx1_Error}, range raw 0..1, transfer-property=PENDING, to VCU  # EN: Rear right wheel speed signal valid
            signal IBS_RRWheelPulseCounter_oIBS_WheelSpeed_02_oATOM_CANFD_Matrix_CH_V600_202502: start 39, 8 bit, big-endian, i-signal-type=PRIMITIVE, init-value=0, base-type=uint8, compu {identical}, range raw 0..255, transfer-property=PENDING, to VCU  # EN: Rear right wheel speed pulse
            signal IBS_RLWheelSpeed_oIBS_WheelSpeed_02_oATOM_CANFD_Matrix_CH_V600_202502: start 44, 13 bit, big-endian, i-signal-type=PRIMITIVE, init-value=0, base-type=uint16, compu {phys=raw*0.05625 for raw 0..6400; unit km/h}, range raw 0..6400, unit=km/h, transfer-property=PENDING, to VCU  # EN: Rear left wheel speed
            signal IBS_RLMovingDirection_oIBS_WheelSpeed_02_oATOM_CANFD_Matrix_CH_V600_202502: start 46, 2 bit, big-endian, i-signal-type=PRIMITIVE, init-value=0, base-type=uint8, compu {0=Cx0_Standstill, 1=Cx1_Forward, 2=Cx2_Backward}, range raw 0..2, transfer-property=PENDING, to VCU  # EN: Rear left wheel direction
            signal IBS_RLWheelSpeed_Fault_oIBS_WheelSpeed_02_oATOM_CANFD_Matrix_CH_V600_202502: start 47, 1 bit, big-endian, i-signal-type=PRIMITIVE, init-value=0, base-type=boolean, compu {0=Cx0_No_error (No error), 1=Cx1_Error}, range raw 0..1, transfer-property=PENDING, to VCU  # EN: Rear left wheel speed signal valid
            signal IBS_RLWheelPulseCounter_oIBS_WheelSpeed_02_oATOM_CANFD_Matrix_CH_V600_202502: start 63, 8 bit, big-endian, i-signal-type=PRIMITIVE, init-value=0, base-type=uint8, compu {identical}, range raw 0..255, transfer-property=PENDING, to VCU  # EN: Rear left wheel speed pulse
            mapping SG_IBS_WheelSpeed_02_SigGroup: i-signal-group=SG_IBS_WheelSpeed_02_SigGroup_oIBS_WheelSpeed_02_oATOM_CANFD_Matrix_CH_V600_202502, transfer-property=PENDING
        frame NM_CGW_oATOM_CANFD_Matrix_CH_V600_202502: id 0x502, to VCU, frame-length=8, can-addressing-mode=STANDARD, can-frame-rx-behavior=ANY, can-frame-tx-behavior=CAN-20
          nm pdu NM_CGW_oATOM_CANFD_Matrix_CH_V600_202502: length=8, unused-bit-pattern=0
        frame NM_VCU_oATOM_CANFD_Matrix_CH_V600_202502: id 0x52C, from VCU, frame-length=8, can-addressing-mode=STANDARD, can-frame-rx-behavior=ANY, can-frame-tx-behavior=CAN-20
          nm pdu NM_VCU_oATOM_CANFD_Matrix_CH_V600_202502: length=8, unused-bit-pattern=0
        frame SGW_17_oATOM_CANFD_Matrix_CH_V600_202502: id 0x352, to VCU, frame-length=8, can-addressing-mode=STANDARD, can-frame-rx-behavior=ANY, can-frame-tx-behavior=CAN-FD
          pdu SGW_17_oATOM_CANFD_Matrix_CH_V600_202502: length=8, minimum-delay=0.02, transmission-mode-false-timing={cyclic-timing={time-offset=0, time-period=0.2}, event-controlled-timing={number-of-repetitions=3, repetition-period=0.02}}, transmission-mode-true-timing={cyclic-timing={time-offset=0, time-period=0.2}, event-controlled-timing={number-of-repetitions=3, repetition-period=0.02}}, unused-bit-pattern=0
            signal SGW_BLESystemReadyReq_oSGW_17_oATOM_CANFD_Matrix_CH_V600_202502: start 3, 2 bit, big-endian, i-signal-type=PRIMITIVE, init-value=0, base-type=uint8, compu {0=Cx0_No_Request (No Request), 1=Cx1_Request_Ready_Remote (Request Ready_Remote), 2=Cx2_Reserve, 3=Cx3_Reserve}, range raw 0..3, transfer-property=TRIGGERED-ON-CHANGE, to VCU  # CBM request ready
            mapping SG_SGW_17_SigGroup: i-signal-group=SG_SGW_17_SigGroup_oSGW_17_oATOM_CANFD_Matrix_CH_V600_202502, transfer-property=PENDING
        frame VCU_02_oATOM_CANFD_Matrix_CH_V600_202502: id 0x319, from VCU, frame-length=8, can-addressing-mode=STANDARD, can-frame-rx-behavior=ANY, can-frame-tx-behavior=CAN-FD
          pdu VCU_02_oATOM_CANFD_Matrix_CH_V600_202502: length=8, minimum-delay=0, transmission-mode-false-timing=cyclic-timing={time-offset=0, time-period=0.2}, transmission-mode-true-timing=cyclic-timing={time-offset=0, time-period=0.2}, unused-bit-pattern=0
            signal VCU_BS_IBSBatSOC_oVCU_02_oATOM_CANFD_Matrix_CH_V600_202502: start 7, 8 bit, big-endian, i-signal-type=PRIMITIVE, init-value=80, base-type=uint8, compu {255=CxFF_Invalid; unit percent} "Source signal range: [0,100]", range raw 0..255, unit=percent, transfer-property=PENDING  # LV Battery SOC
            signal VCU_BS_Current_oVCU_02_oATOM_CANFD_Matrix_CH_V600_202502: start 15, 14 bit, big-endian, i-signal-type=PRIMITIVE, init-value=0, base-type=uint16, compu {phys=raw*0.001-8.192 for raw 0..16383}, range raw 0..16383, transfer-property=PENDING  # LV Battery current(Route Lin signal ' BS_BatCrntRawVal')
            signal VCU_BS_IndicatorSts_oVCU_02_oATOM_CANFD_Matrix_CH_V600_202502: start 31, 1 bit, big-endian, i-signal-type=PRIMITIVE, init-value=0, base-type=boolean, compu {0=Cx0_No_request (No request), 1=Cx1_Low_SOH (Low SOH)}, range raw 0..1, transfer-property=PENDING  # Battery failure
            signal VCU_BS_LV_Batt_oVCU_02_oATOM_CANFD_Matrix_CH_V600_202502: start 47, 15 bit, big-endian, i-signal-type=PRIMITIVE, init-value=0, base-type=uint16, compu {phys=raw*0.001 for raw 0..32767; unit V}, range raw 0..32767, unit=V, transfer-property=PENDING  # LV Battery voltage(Route Lin signal 'BS_BatVltHIRes')
            signal VCU_WakeUpStatus_oVCU_02_oATOM_CANFD_Matrix_CH_V600_202502: start 63, 8 bit, big-endian, i-signal-type=PRIMITIVE, init-value=0, base-type=uint8, compu {identical}, range raw 0..255, transfer-property=PENDING  # VCU Wake Up Status
            mapping SG_VCU_02_SigGroup: i-signal-group=SG_VCU_02_SigGroup_oVCU_02_oATOM_CANFD_Matrix_CH_V600_202502, transfer-property=PENDING
        frame VCU_03_oATOM_CANFD_Matrix_CH_V600_202502: id 0x222, from VCU, frame-length=8, can-addressing-mode=STANDARD, can-frame-rx-behavior=ANY, can-frame-tx-behavior=CAN-FD
          pdu VCU_03_oATOM_CANFD_Matrix_CH_V600_202502: length=8, minimum-delay=0, transmission-mode-false-timing=cyclic-timing={time-offset=0, time-period=0.1}, transmission-mode-true-timing=cyclic-timing={time-offset=0, time-period=0.1}, unused-bit-pattern=0
            signal VCU_DCFCCurrent_oVCU_03_oATOM_CANFD_Matrix_CH_V600_202502: start 23, 10 bit, big-endian, i-signal-type=PRIMITIVE, init-value=0, base-type=uint16, compu {identical}, range raw 0..1023, unit=A, transfer-property=PENDING  # DC charging current calculated by VCU
            signal VCU_ChargeProcessComment_oVCU_03_oATOM_CANFD_Matrix_CH_V600_202502: start 25, 2 bit, big-endian, i-signal-type=PRIMITIVE, init-value=0, base-type=uint8, compu {0=Cx0_No_comment (No comment), 1=Cx1_Charge_Fault_and_slow (Charge Fault and slow), 2=Cx2_Reserved, 3=Cx3_Reserved}, range raw 0..3, transfer-property=PENDING  # Abnormal prompt in charging stage
            signal VCU_BrakeCompensateStatus_oVCU_03_oATOM_CANFD_Matrix_CH_V600_202502: start 27, 2 bit, big-endian, i-signal-type=PRIMITIVE, init-value=0, base-type=uint8, compu {0=Cx0_Invalid, 1=Cx1_OFF, 2=Cx2_ON, 3=Cx3_Reserved}, range raw 0..3, transfer-property=PENDING  # Brake compensation open state
            signal VCU_EnergyV2L_oVCU_03_oATOM_CANFD_Matrix_CH_V600_202502: start 55, 12 bit, big-endian, i-signal-type=PRIMITIVE, init-value=0, base-type=uint16, compu {phys=raw*0.1 for raw 0..1023; unit kWh}, range raw 0..1023, unit=kWh, transfer-property=PENDING  # VCU feedback discharge quantity signal
            signal VCU_MemoryChargeFault_oVCU_03_oATOM_CANFD_Matrix_CH_V600_202502: start 59, 1 bit, big-endian, i-signal-type=PRIMITIVE, init-value=0, base-type=boolean, compu {0=Cx0_Normal, 1=Cx1_Charge_Fault (Charge Fault)}, range raw 0..1, transfer-property=PENDING  # Charging fault status of VCU memory
            mapping SG_VCU_03_SigGroup: i-signal-group=SG_VCU_03_SigGroup_oVCU_03_oATOM_CANFD_Matrix_CH_V600_202502, transfer-property=PENDING
        frame VCU_04_oATOM_CANFD_Matrix_CH_V600_202502: id 0x223, from VCU, frame-length=8, can-addressing-mode=STANDARD, can-frame-rx-behavior=ANY, can-frame-tx-behavior=CAN-FD
          pdu VCU_04_oATOM_CANFD_Matrix_CH_V600_202502: length=8, minimum-delay=0, transmission-mode-false-timing=cyclic-timing={time-offset=0, time-period=0.1}, transmission-mode-true-timing=cyclic-timing={time-offset=0, time-period=0.1}, unused-bit-pattern=0
            signal VCU_ManuallyUnlockComment_oVCU_04_oATOM_CANFD_Matrix_CH_V600_202502: start 14, 1 bit, big-endian, i-signal-type=PRIMITIVE, init-value=0, base-type=boolean, compu {0=Cx0_False, 1=Cx1_True}, range raw 0..1, transfer-property=PENDING  # Manual unlock electronic lock reminder signal
            signal VCU_ForwardVmaxlimitStatus_oVCU_04_oATOM_CANFD_Matrix_CH_V600_202502: start 15, 1 bit, big-endian, i-signal-type=PRIMITIVE, init-value=0, base-type=boolean, compu {0=Cx0_Inactive, 1=Cx1_Active}, range raw 0..1, transfer-property=PENDING  # maximum speed limit status in D gear
            mapping SG_VCU_04_SigGroup: i-signal-group=SG_VCU_04_SigGroup_oVCU_04_oATOM_CANFD_Matrix_CH_V600_202502, transfer-property=PENDING
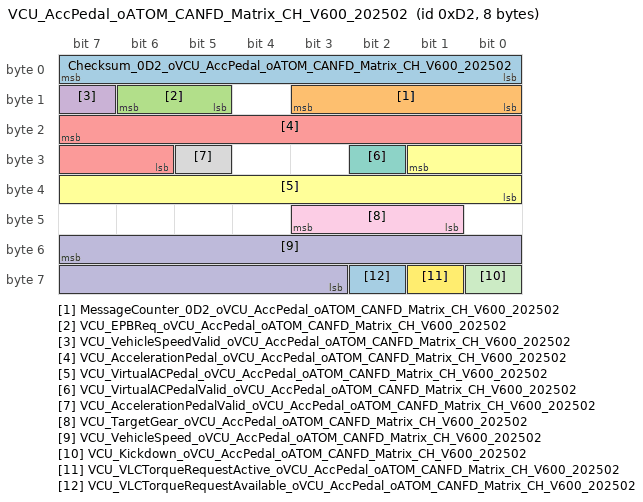
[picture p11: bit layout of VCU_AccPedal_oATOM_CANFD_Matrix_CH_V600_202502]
        frame VCU_AccPedal_oATOM_CANFD_Matrix_CH_V600_202502: id 0xD2, from VCU, frame-length=8, can-addressing-mode=STANDARD, can-frame-rx-behavior=ANY, can-frame-tx-behavior=CAN-FD
          pdu VCU_AccPedal_oATOM_CANFD_Matrix_CH_V600_202502: length=8, minimum-delay=0, transmission-mode-false-timing=cyclic-timing={time-offset=0, time-period=0.02}, transmission-mode-true-timing=cyclic-timing={time-offset=0, time-period=0.02}, unused-bit-pattern=0
            signal Checksum_0D2_oVCU_AccPedal_oATOM_CANFD_Matrix_CH_V600_202502: start 7, 8 bit, big-endian, i-signal-type=PRIMITIVE, init-value=0, base-type=uint8, compu {identical}, range raw 0..255, transfer-property=PENDING  # Checksum signal for frame
            signal MessageCounter_0D2_oVCU_AccPedal_oATOM_CANFD_Matrix_CH_V600_202502: start 11, 4 bit, big-endian, i-signal-type=PRIMITIVE, init-value=0, base-type=uint8, compu {15=CxF_Invalid}, range raw 0..15, transfer-property=PENDING  # Message counter signal for frame
            signal VCU_EPBReq_oVCU_AccPedal_oATOM_CANFD_Matrix_CH_V600_202502: start 14, 2 bit, big-endian, i-signal-type=PRIMITIVE, init-value=0, base-type=uint8, compu {0=Cx0_Not_Request (Not Request), 1=Cx1_Apply_Request (Apply Request), 2=Cx2_Release_Request (Release Request), 3=Cx3_Reserved}, range raw 0..3, transfer-property=PENDING  # VCU request EPB
            signal VCU_VehicleSpeedValid_oVCU_AccPedal_oATOM_CANFD_Matrix_CH_V600_202502: start 15, 1 bit, big-endian, i-signal-type=PRIMITIVE, init-value=0, base-type=boolean, compu {0=Cx0_invalid, 1=Cx1_valid}, range raw 0..1, transfer-property=PENDING  # Speed Validity Flag
            signal VCU_AccelerationPedal_oVCU_AccPedal_oATOM_CANFD_Matrix_CH_V600_202502: start 23, 10 bit, big-endian, i-signal-type=PRIMITIVE, init-value=0, base-type=uint16, compu {phys=raw*0.1 for raw 0..1000; unit percent}, range raw 0..1000, unit=percent, transfer-property=PENDING  # Acceleration Pedal percentage
            signal VCU_VirtualACPedal_oVCU_AccPedal_oATOM_CANFD_Matrix_CH_V600_202502: start 25, 10 bit, big-endian, i-signal-type=PRIMITIVE, init-value=0, base-type=uint16, compu {phys=raw*0.1 for raw 0..1000; unit percent}, range raw 0..1000, unit=percent, transfer-property=PENDING  # Virtual acceleration Pedal percentage
            signal VCU_VirtualACPedalValid_oVCU_AccPedal_oATOM_CANFD_Matrix_CH_V600_202502: start 26, 1 bit, big-endian, i-signal-type=PRIMITIVE, init-value=0, base-type=boolean, compu {0=Cx0_Invalid, 1=Cx1_Valid}, range raw 0..1, transfer-property=PENDING  # Virtual acceleration Pedal percentage valid status
            signal VCU_AccelerationPedalValid_oVCU_AccPedal_oATOM_CANFD_Matrix_CH_V600_202502: start 29, 1 bit, big-endian, i-signal-type=PRIMITIVE, init-value=0, base-type=boolean, compu {0=Cx0_Invalid, 1=Cx1_Valid}, range raw 0..1, transfer-property=PENDING  # Acceleration Pedal percentage valid status
            signal VCU_TargetGear_oVCU_AccPedal_oATOM_CANFD_Matrix_CH_V600_202502: start 43, 3 bit, big-endian, i-signal-type=PRIMITIVE, init-value=0, base-type=uint8, compu {0=Cx0_Reserve, 1=Cx1_P, 2=Cx2_N, 3=Cx3_R, 4=Cx4_D}, range raw 0..4, transfer-property=PENDING  # Target Gear position
            signal VCU_VehicleSpeed_oVCU_AccPedal_oATOM_CANFD_Matrix_CH_V600_202502: start 55, 13 bit, big-endian, i-signal-type=PRIMITIVE, init-value=0, base-type=uint16, compu {phys=raw*0.05625 for raw 0..6400; unit km/h}, range raw 0..6400, unit=km/h, transfer-property=PENDING  # VCU calculates the output vehicle speed
            signal VCU_Kickdown_oVCU_AccPedal_oATOM_CANFD_Matrix_CH_V600_202502: start 56, 1 bit, big-endian, i-signal-type=PRIMITIVE, init-value=0, base-type=boolean, compu {0=Cx0_Invalid, 1=Cx1_Valid}, range raw 0..1, transfer-property=PENDING  # Kickdown
            signal VCU_VLCTorqueRequestActive_oVCU_AccPedal_oATOM_CANFD_Matrix_CH_V600_202502: start 57, 1 bit, big-endian, i-signal-type=PRIMITIVE, init-value=0, base-type=boolean, compu {0=Cx0_Not_Active (Not Active), 1=Cx1_Active}, range raw 0..1, transfer-property=PENDING  # Is the VCU responding to VLC torque request function activated
            signal VCU_VLCTorqueRequestAvailable_oVCU_AccPedal_oATOM_CANFD_Matrix_CH_V600_202502: start 58, 1 bit, big-endian, i-signal-type=PRIMITIVE, init-value=0, base-type=boolean, compu {0=Cx0_Not_Available (Not Available), 1=Cx1_Available}, range raw 0..1, transfer-property=PENDING  # Is VCU available to respond to VLC torque requests
            mapping SG_VCU_AccPedal_SigGroup: i-signal-group=SG_VCU_AccPedal_SigGroup_oVCU_AccPedal_oATOM_CANFD_Matrix_CH_V600_202502, transfer-property=PENDING
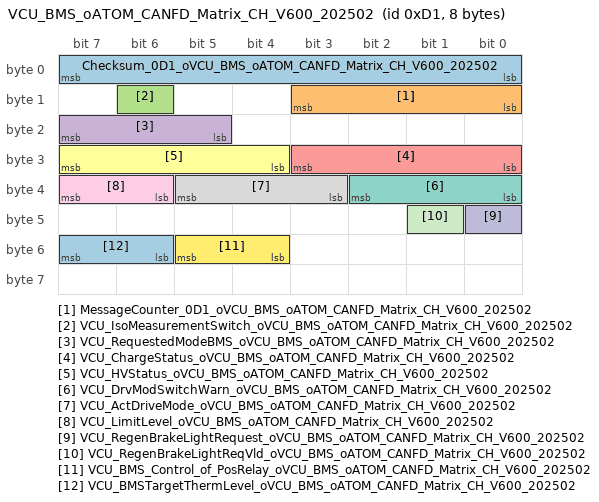
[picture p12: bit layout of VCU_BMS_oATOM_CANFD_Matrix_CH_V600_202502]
        frame VCU_BMS_oATOM_CANFD_Matrix_CH_V600_202502: id 0xD1, from VCU, frame-length=8, can-addressing-mode=STANDARD, can-frame-rx-behavior=ANY, can-frame-tx-behavior=CAN-FD
          pdu VCU_BMS_oATOM_CANFD_Matrix_CH_V600_202502: length=8, minimum-delay=0, transmission-mode-false-timing=cyclic-timing={time-offset=0, time-period=0.02}, transmission-mode-true-timing=cyclic-timing={time-offset=0, time-period=0.02}, unused-bit-pattern=0
            signal Checksum_0D1_oVCU_BMS_oATOM_CANFD_Matrix_CH_V600_202502: start 7, 8 bit, big-endian, i-signal-type=PRIMITIVE, init-value=0, base-type=uint8, compu {identical}, range raw 0..255, transfer-property=PENDING  # Checksum signal for frame
            signal MessageCounter_0D1_oVCU_BMS_oATOM_CANFD_Matrix_CH_V600_202502: start 11, 4 bit, big-endian, i-signal-type=PRIMITIVE, init-value=0, base-type=uint8, compu {15=CxF_Invalid}, range raw 0..15, transfer-property=PENDING  # Message counter signal for frame
            signal VCU_IsoMeasurementSwitch_oVCU_BMS_oATOM_CANFD_Matrix_CH_V600_202502: start 14, 1 bit, big-endian, i-signal-type=PRIMITIVE, init-value=1, base-type=boolean, compu {0=Cx0_OFF, 1=Cx1_ON}, range raw 0..1, transfer-property=PENDING  # Insulation detection enable instruction.
            signal VCU_RequestedModeBMS_oVCU_BMS_oATOM_CANFD_Matrix_CH_V600_202502: start 23, 3 bit, big-endian, i-signal-type=PRIMITIVE, init-value=0, base-type=uint8, compu {0=Cx0_InActive, 1=Cx1_HVActive, 2=Cx2_Reserved, 3=Cx3_Reserved, 4=Cx4_Reserved, 5=Cx5_EmergencyOff, 6=Cx6_Reserved, 7=Cx7_Invalid}, range raw 0..7, transfer-property=PENDING  # Interface to request eletric energy storage target mode
            signal VCU_ChargeStatus_oVCU_BMS_oATOM_CANFD_Matrix_CH_V600_202502: start 27, 4 bit, big-endian, i-signal-type=PRIMITIVE, init-value=0, base-type=uint8, compu {0=Cx0_Init, 1=Cx1_Off_Plug (Off Plug), 2=Cx2_AC_Plug_Detected (AC Plug Detected), 3=Cx3_DC_Plug_Detected (DC Plug Detected), 4=Cx4_V2L_Plug_Detected (V2L Plug Detected), 5=Cx5_AC_Charging (AC Charging), 6=Cx6_DC_Charging (DC Charging), 7=Cx7_V2L_Discharging (V2L Discharging), 8=Cx8_Charging_Completed (Charging Completed), 9=Cx9_Charging_Fault (Charging Fault), 10=CxA_AC_Preheating (AC Preheating), 11=CxB_DC_Preheating (DC Preheating), 12=CxC_V2L_completed (V2L completed), 13=CxD_KeepWarming, 14=CxE_V2L_Fault (V2L Fault)}, range raw 0..14, transfer-property=PENDING  # Charge state
            signal VCU_HVStatus_oVCU_BMS_oATOM_CANFD_Matrix_CH_V600_202502: start 31, 4 bit, big-endian, i-signal-type=PRIMITIVE, init-value=0, base-type=uint8, compu {0=Cx0_Init, 1=Cx1_Standby, 2=Cx2_HV_Ready (HV Ready), 3=Cx3_Drive_ready (Drive ready), 4=Cx4_Preheating, 5=Cx5_Sleep}, range raw 0..5, transfer-property=PENDING  # HV System state
            signal VCU_DrvModSwitchWarn_oVCU_BMS_oATOM_CANFD_Matrix_CH_V600_202502: start 34, 3 bit, big-endian, i-signal-type=PRIMITIVE, init-value=0, base-type=uint8, compu {0=Cx0_RESERVE, 1=Cx1_unrecommed_Sport_Low_SOC (unrecommed Sport-Low SOC), 2=Cx2_Vehicle_not_in_P_gear_single_pedal_unavailable (Vehicle not in P gear,single pedal unavailable), 3=Cx3_Vehicle_failure_single_pedal_unavailable_ (Vehicle failure, single pedal unavailable.), 4=Cx4_Reserved, 5=Cx5_Reserved, 6=Cx6_Reserved, 7=Cx7_Reserved}, range raw 0..7, transfer-property=PENDING  # Warning dispaly when dirve mode swich
            signal VCU_ActDriveMode_oVCU_BMS_oATOM_CANFD_Matrix_CH_V600_202502: start 37, 3 bit, big-endian, i-signal-type=PRIMITIVE, init-value=0, base-type=uint8, compu {0=Cx0_INVALID, 1=Cx1_ECO, 2=Cx2_NORMAL, 3=Cx3_SPORT, 4=Cx4_OnePedal}, range raw 0..4, transfer-property=PENDING  # Actual drive mode
            signal VCU_LimitLevel_oVCU_BMS_oATOM_CANFD_Matrix_CH_V600_202502: start 39, 2 bit, big-endian, i-signal-type=PRIMITIVE, init-value=0, base-type=uint8, compu {0=Cx0_level_0_No_limit (level 0-No limit), 1=Cx1_level_1 (level 1), 2=Cx2_level_2 (level 2), 3=Cx3_level_3 (level 3)}, range raw 0..3, transfer-property=PENDING  # Low-voltage energy management limit level
            signal VCU_RegenBrakeLightRequest_oVCU_BMS_oATOM_CANFD_Matrix_CH_V600_202502: start 40, 1 bit, big-endian, i-signal-type=PRIMITIVE, init-value=0, base-type=boolean, compu {0=Cx0_Brake_lights_Off (Brake lights Off), 1=Cx1_Brake_lights_On (Brake lights On)}, range raw 0..1, transfer-property=PENDING  # Request to illuminate the brake lights from the Powertrain if regen creates deceleration greater than 0.07g.
            signal VCU_RegenBrakeLightReqVld_oVCU_BMS_oATOM_CANFD_Matrix_CH_V600_202502: start 41, 1 bit, big-endian, i-signal-type=PRIMITIVE, init-value=0, base-type=boolean, compu {0=Cx0_INVALID, 1=Cx1_VALID}, range raw 0..1, transfer-property=PENDING  # Valid status of Request to illuminate the brake lights from the Powertrain
            signal VCU_BMS_Control_of_PosRelay_oVCU_BMS_oATOM_CANFD_Matrix_CH_V600_202502: start 53, 2 bit, big-endian, i-signal-type=PRIMITIVE, init-value=0, base-type=uint8, compu {0=Cx0_Invaild, 1=Cx1_Open, 2=Cx2_Close}, range raw 0..2, transfer-property=PENDING  # Request for closing positive relay
            signal VCU_BMSTargetThermLevel_oVCU_BMS_oATOM_CANFD_Matrix_CH_V600_202502: start 55, 2 bit, big-endian, i-signal-type=PRIMITIVE, init-value=0, base-type=uint8, compu {0=Cx0_Level_1_low_ (Level 1(low)), 1=Cx1_Level_2_medium_ (Level 2(medium)), 2=Cx2_Level_3_high_ (Level 3(high)), 3=Cx3_Reserved}, range raw 0..3, transfer-property=PENDING  # BMS target temperature level
            mapping SG_VCU_BMS_SigGroup: i-signal-group=SG_VCU_BMS_SigGroup_oVCU_BMS_oATOM_CANFD_Matrix_CH_V600_202502, transfer-property=PENDING
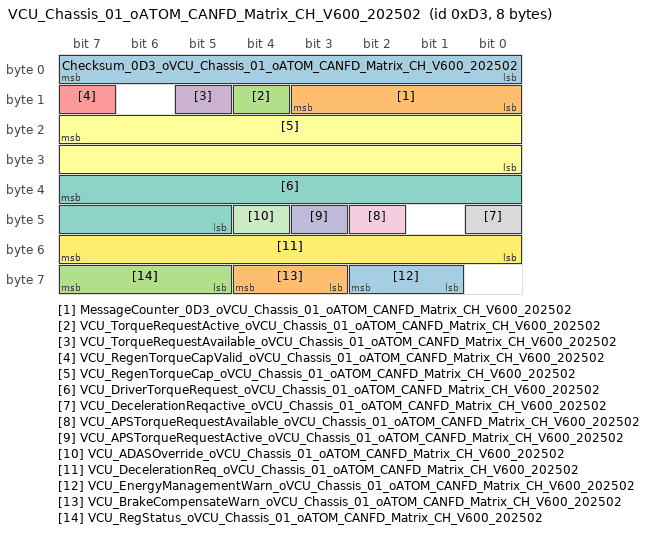
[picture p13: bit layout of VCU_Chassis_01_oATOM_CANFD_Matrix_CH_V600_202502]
        frame VCU_Chassis_01_oATOM_CANFD_Matrix_CH_V600_202502: id 0xD3, from VCU, frame-length=8, can-addressing-mode=STANDARD, can-frame-rx-behavior=ANY, can-frame-tx-behavior=CAN-FD
          pdu VCU_Chassis_01_oATOM_CANFD_Matrix_CH_V600_202502: length=8, minimum-delay=0, transmission-mode-false-timing=cyclic-timing={time-offset=0, time-period=0.02}, transmission-mode-true-timing=cyclic-timing={time-offset=0, time-period=0.02}, unused-bit-pattern=0
            signal Checksum_0D3_oVCU_Chassis_01_oATOM_CANFD_Matrix_CH_V600_202502: start 7, 8 bit, big-endian, i-signal-type=PRIMITIVE, init-value=0, base-type=uint8, compu {identical}, range raw 0..255, transfer-property=PENDING  # Checksum signal for frame
            signal MessageCounter_0D3_oVCU_Chassis_01_oATOM_CANFD_Matrix_CH_V600_202502: start 11, 4 bit, big-endian, i-signal-type=PRIMITIVE, init-value=0, base-type=uint8, compu {15=CxF_Invalid}, range raw 0..15, transfer-property=PENDING  # Message counter signal for frame
            signal VCU_TorqueRequestActive_oVCU_Chassis_01_oATOM_CANFD_Matrix_CH_V600_202502: start 12, 1 bit, big-endian, i-signal-type=PRIMITIVE, init-value=0, base-type=boolean, compu {0=Cx0_Not_Active (Not Active), 1=Cx1_Active}, range raw 0..1, transfer-property=PENDING  # Active status of VCU in response to the external torque request
            signal VCU_TorqueRequestAvailable_oVCU_Chassis_01_oATOM_CANFD_Matrix_CH_V600_202502: start 13, 1 bit, big-endian, i-signal-type=PRIMITIVE, init-value=0, base-type=boolean, compu {0=Cx0_Not_Available (Not Available), 1=Cx1_Available}, range raw 0..1, transfer-property=PENDING  # Available status of VCU in response to the external torque request
            signal VCU_RegenTorqueCapValid_oVCU_Chassis_01_oATOM_CANFD_Matrix_CH_V600_202502: start 15, 1 bit, big-endian, i-signal-type=PRIMITIVE, init-value=0, base-type=boolean, compu {0=Cx0_invalid, 1=Cx1_valid}, range raw 0..1, transfer-property=PENDING  # brake recovery torque cap valid
            signal VCU_RegenTorqueCap_oVCU_Chassis_01_oATOM_CANFD_Matrix_CH_V600_202502: start 23, 16 bit, big-endian, i-signal-type=PRIMITIVE, init-value=0, base-type=uint16, compu {phys=raw-20000 for raw 0..40000}, range raw 0..40000, transfer-property=PENDING  # Maximum brake recovery torque of motor
            signal VCU_DriverTorqueRequest_oVCU_Chassis_01_oATOM_CANFD_Matrix_CH_V600_202502: start 39, 11 bit, big-endian, i-signal-type=PRIMITIVE, init-value=0, base-type=uint16, compu {phys=raw-1023 for raw 0..2045}, range raw 0..2045, transfer-property=PENDING  # Driver torque request
            signal VCU_DecelerationReqactive_oVCU_Chassis_01_oATOM_CANFD_Matrix_CH_V600_202502: start 40, 1 bit, big-endian, i-signal-type=PRIMITIVE, init-value=0, base-type=boolean, compu {0=Cx0_Inactive_ (Inactive;), 1=Cx1_Active}, range raw 0..1, transfer-property=PENDING  # Request deceleration from IBS
            signal VCU_APSTorqueRequestAvailable_oVCU_Chassis_01_oATOM_CANFD_Matrix_CH_V600_202502: start 42, 1 bit, big-endian, i-signal-type=PRIMITIVE, init-value=0, base-type=boolean, compu {0=Cx0_Not_Available (Not Available), 1=Cx1_Available}, range raw 0..1, transfer-property=PENDING  # Is VCU available to respond to VLC torque requests
            signal VCU_APSTorqueRequestActive_oVCU_Chassis_01_oATOM_CANFD_Matrix_CH_V600_202502: start 43, 1 bit, big-endian, i-signal-type=PRIMITIVE, init-value=0, base-type=boolean, compu {0=Cx0_Not_Active (Not Active), 1=Cx1_Active}, range raw 0..1, transfer-property=PENDING  # Is the VCU responding to VLC torque request function activated
            signal VCU_ADASOverride_oVCU_Chassis_01_oATOM_CANFD_Matrix_CH_V600_202502: start 44, 1 bit, big-endian, i-signal-type=PRIMITIVE, init-value=0, base-type=boolean, compu {0=Cx0_off, 1=Cx1_on}, range raw 0..1, transfer-property=PENDING  # Override signal
            signal VCU_DecelerationReq_oVCU_Chassis_01_oATOM_CANFD_Matrix_CH_V600_202502: start 55, 8 bit, big-endian, i-signal-type=PRIMITIVE, init-value=0, base-type=uint8, compu {phys=raw*0.05-5 for raw 0..255; unit m/s^2}, range raw 0..255, unit=m/s^2, transfer-property=PENDING  # One-pedal VCU deceleration request
            signal VCU_EnergyManagementWarn_oVCU_Chassis_01_oATOM_CANFD_Matrix_CH_V600_202502: start 58, 2 bit, big-endian, i-signal-type=PRIMITIVE, init-value=0, base-type=uint8, compu {0=Cx0_OFF, 1=Cx1_Battery_is_discharging_recommended_to_turn_off_the_air_conditioner_or_other_loads_ (Battery is discharging, recommended to turn off the air conditioner or other loads.), 2=Cx2_Insufficient_vehicle_power_recommended_to_turn_off_the_air_conditioner_or_other_loads_ (Insufficient vehicle power,recommended to turn off the air conditioner or other loads.), 3=Cx3_Reserved}, range raw 0..3, transfer-property=PENDING  # The warning of energy management
            signal VCU_BrakeCompensateWarn_oVCU_Chassis_01_oATOM_CANFD_Matrix_CH_V600_202502: start 60, 2 bit, big-endian, i-signal-type=PRIMITIVE, init-value=0, base-type=uint8, compu {0=Cx0_No_display (No display), 1=Cx1_Vehicle_failure_brake_compensation_failed_to_open_ (Vehicle failure, brake compensation failed to open.), 2=Cx2_Reserved, 3=Cx3_Reserved}, range raw 0..3, transfer-property=PENDING  # The warning of brake compensation failure.
            signal VCU_RegStatus_oVCU_Chassis_01_oATOM_CANFD_Matrix_CH_V600_202502: start 63, 3 bit, big-endian, i-signal-type=PRIMITIVE, init-value=0, base-type=uint8, compu {0=Cx0_Reserve, 1=Cx1_OFF, 2=Cx2_Primary_energy_recovery_weak_ (Primary energy recovery (weak)), 3=Cx3_Secondary_energy_recovery_medium_ (Secondary energy recovery(medium)), 4=Cx4_Tertiary_energy_recovery_strong_ (Tertiary energy recovery (strong)), 5=Cx5_Reserved, 6=Cx6_Reserved, 7=Cx7_Reserved}, range raw 0..7, transfer-property=PENDING  # The energy recovery level
            mapping SG_VCU_Chassis_01_SigGroup: i-signal-group=SG_VCU_Chassis_01_SigGroup_oVCU_Chassis_01_oATOM_CANFD_Matrix_CH_V600_202502, transfer-property=PENDING
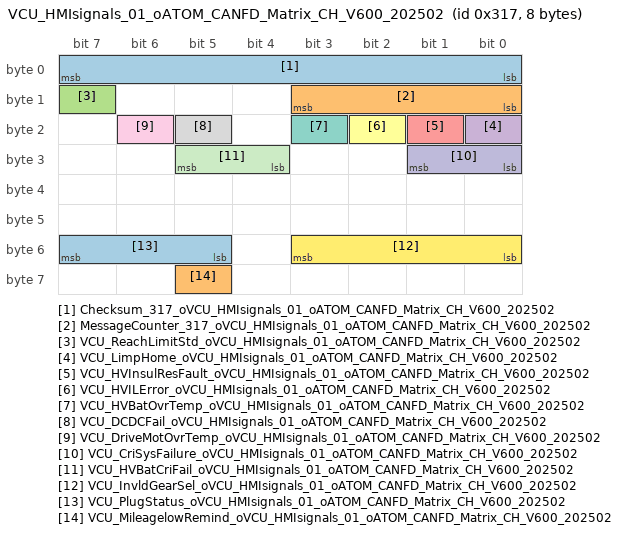
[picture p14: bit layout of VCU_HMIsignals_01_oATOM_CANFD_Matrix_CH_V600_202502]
        frame VCU_HMIsignals_01_oATOM_CANFD_Matrix_CH_V600_202502: id 0x317, from VCU, frame-length=8, can-addressing-mode=STANDARD, can-frame-rx-behavior=ANY, can-frame-tx-behavior=CAN-FD
          pdu VCU_HMIsignals_01_oATOM_CANFD_Matrix_CH_V600_202502: length=8, minimum-delay=0, transmission-mode-false-timing=cyclic-timing={time-offset=0, time-period=0.2}, transmission-mode-true-timing=cyclic-timing={time-offset=0, time-period=0.2}, unused-bit-pattern=0
            signal Checksum_317_oVCU_HMIsignals_01_oATOM_CANFD_Matrix_CH_V600_202502: start 7, 8 bit, big-endian, i-signal-type=PRIMITIVE, init-value=0, base-type=uint8, compu {identical}, range raw 0..255, transfer-property=PENDING  # Checksum signal for frame
            signal MessageCounter_317_oVCU_HMIsignals_01_oATOM_CANFD_Matrix_CH_V600_202502: start 11, 4 bit, big-endian, i-signal-type=PRIMITIVE, init-value=0, base-type=uint8, compu {15=CxF_Invalid}, range raw 0..15, transfer-property=PENDING  # Message counter signal for frame
            signal VCU_ReachLimitStd_oVCU_HMIsignals_01_oATOM_CANFD_Matrix_CH_V600_202502: start 15, 1 bit, big-endian, i-signal-type=PRIMITIVE, init-value=0, base-type=boolean, compu {0=Cx0_No_request (No request), 1=Cx1_Request}, range raw 0..1, transfer-property=PENDING  # SOC reaches the limit level prompt
            signal VCU_LimpHome_oVCU_HMIsignals_01_oATOM_CANFD_Matrix_CH_V600_202502: start 16, 1 bit, big-endian, i-signal-type=PRIMITIVE, init-value=0, base-type=boolean, compu {0=Cx0_False, 1=Cx1_True}, range raw 0..1, transfer-property=PENDING  # Limp home: GB/T 4094.2, Table 1, No. 3
            signal VCU_HVInsulResFault_oVCU_HMIsignals_01_oATOM_CANFD_Matrix_CH_V600_202502: start 17, 1 bit, big-endian, i-signal-type=PRIMITIVE, init-value=0, base-type=boolean, compu {0=Cx0_False, 1=Cx1_True}, range raw 0..1, transfer-property=PENDING  # Insulation resistance/creepage distance indication: rrequired via GB/T 19836
            signal VCU_HVILError_oVCU_HMIsignals_01_oATOM_CANFD_Matrix_CH_V600_202502: start 18, 1 bit, big-endian, i-signal-type=PRIMITIVE, init-value=0, base-type=boolean, compu {0=Cx0_False, 1=Cx1_True}, range raw 0..1, transfer-property=PENDING  # HVIL error (Interlock monitoring device): required via GB/T 19836
            signal VCU_HVBatOvrTemp_oVCU_HMIsignals_01_oATOM_CANFD_Matrix_CH_V600_202502: start 19, 1 bit, big-endian, i-signal-type=PRIMITIVE, init-value=0, base-type=boolean, compu {0=Cx0_False, 1=Cx1_True}, range raw 0..1, transfer-property=PENDING  # HV battery over temperature indicator
            signal VCU_DCDCFail_oVCU_HMIsignals_01_oATOM_CANFD_Matrix_CH_V600_202502: start 21, 1 bit, big-endian, i-signal-type=PRIMITIVE, init-value=0, base-type=boolean, compu {0=Cx0_False, 1=Cx1_True}, range raw 0..1, transfer-property=PENDING  # DCDC failure status indicator
            signal VCU_DriveMotOvrTemp_oVCU_HMIsignals_01_oATOM_CANFD_Matrix_CH_V600_202502: start 22, 1 bit, big-endian, i-signal-type=PRIMITIVE, init-value=0, base-type=boolean, compu {0=Cx0_False, 1=Cx1_True}, range raw 0..1, transfer-property=PENDING  # Over-temp required via GB/T 19836. Additional components may be needed.
            signal VCU_CriSysFailure_oVCU_HMIsignals_01_oATOM_CANFD_Matrix_CH_V600_202502: start 25, 2 bit, big-endian, i-signal-type=PRIMITIVE, init-value=0, base-type=uint8, compu {0=Cx0_No_Warning, 1=Cx1_Leve1_lighting_prompt_only_ (Leve1 (lighting prompt only)), 2=Cx2_Leve2_power_loss_ (Leve2 (power loss)), 3=Cx3_Leve3_emergency_power_off_ (Leve3 (emergency power off))}, range raw 0..3, transfer-property=PENDING  # System failure tell-tale: GB/T 4094.2, Table 2, No. 3
            signal VCU_HVBatCriFail_oVCU_HMIsignals_01_oATOM_CANFD_Matrix_CH_V600_202502: start 29, 2 bit, big-endian, i-signal-type=PRIMITIVE, init-value=0, base-type=uint8, compu {0=Cx0_False, 1=Cx1_Yellow, 2=Cx2_Red, 3=Cx3_Reserve}, range raw 0..3, transfer-property=PENDING  # Traction battery failure: GB/T 4094.2, Table 2, No. 1
            signal VCU_InvldGearSel_oVCU_HMIsignals_01_oATOM_CANFD_Matrix_CH_V600_202502: start 51, 4 bit, big-endian, i-signal-type=PRIMITIVE, init-value=0, base-type=uint8, compu {0=Cx0_Normal, 1=Cx1_Shifting_fails_please_brake (Shifting fails, please brake), 2=Cx2_Danger_Too_high_speed_do_not_switch_D_gear (Danger _ Too high speed _ do not switch D gear), 3=Cx3_Danger_Too_high_speed_do_not_switch_R_gear (Danger _ Too high speed _ do not switch R gear), 4=Cx4_Danger_Too_high_speed_do_not_switch_P_gear (Danger _ Too high speed _ do not switch P gear), 5=Cx5_Danger_The_accelerator_pedal_is_too_large_it_is_forbidden_to_switch_driving_gear (Danger _ The accelerator pedal is too large _ it is forbidden to switch driving gear), 6=Cx6_Charging_gun_connected_do_not_switch_gear (Charging gun connected, do not switch gear), 7=Cx7_The_shift_button_is_faulty_Screen_shift_is_recommended (The shift button is faulty _ Screen shift is recommended), 8=Cx8_The_vehicle_is_not_ready_it_is_forbidden_to_switch_driving_gears (The vehicle is not ready_it is forbidden to switch driving gears), 9=Cx9_EPB_unresponsive_unable_to_engage_in_P_gear (EPB unresponsive_unable to engage in P gear), 10=CxA_EPB_unresponsive_unable_to_exit_in_P_gear (EPB unresponsive_unable to exit in P gear), 11=CxB_SWP_is_faulty_PRND_button_is_recommended (SWP is faulty _ PRND button is recommended), 12=CxC_Fault_detected_shift_failed_please_restart_the_vehicle_or_contact_customer_service (Fault detected, shift failed, please restart the vehicle or contact customer service), 13=CxD_Danger_Too_high_speed_do_not_switch_N_gear (Danger _ Too high speed _ do not switch N gear), 14=CxE_Gun_insertion_detected_execute_automatic_P_gear (Gun insertion detected. execute automatic P-gear), 15=CxF_Immo_state_enable_forbid_gear_shifting (Immo state enable,forbid gear shifting)}, range raw 0..15, transfer-property=PENDING  # Invalid Gear Selection Flag
            signal VCU_PlugStatus_oVCU_HMIsignals_01_oATOM_CANFD_Matrix_CH_V600_202502: start 55, 3 bit, big-endian, i-signal-type=PRIMITIVE, init-value=0, base-type=uint8, compu {0=Cx0_Init, 1=Cx1_No_Plug_connected, 2=Cx2_AC_Plug_connected_Unlock, 3=Cx3_AC_Plug_connected_Locked, 4=Cx4_DC_Plug_connected, 5=Cx5_V2L_Plug_connected, 6=Cx6_AC_Plug_DC_Plug_Connected (AC Plug&DC Plug Connected), 7=Cx7_Fault}, range raw 0..7, transfer-property=PENDING  # Charge and discharge gun connection state
            signal VCU_MileagelowRemind_oVCU_HMIsignals_01_oATOM_CANFD_Matrix_CH_V600_202502: start 61, 1 bit, big-endian, i-signal-type=PRIMITIVE, init-value=0, base-type=boolean, compu {0=Cx0_No_comment (No comment), 1=Cx1_The_mileage_is_too_low_please_charge (The mileage is too low, please charge)}, range raw 0..1, transfer-property=PENDING  # Mileage low Reminding
            mapping SG_VCU_HMIsignals_01_SigGroup: i-signal-group=SG_VCU_HMIsignals_01_SigGroup_oVCU_HMIsignals_01_oATOM_CANFD_Matrix_CH_V600_202502, transfer-property=PENDING
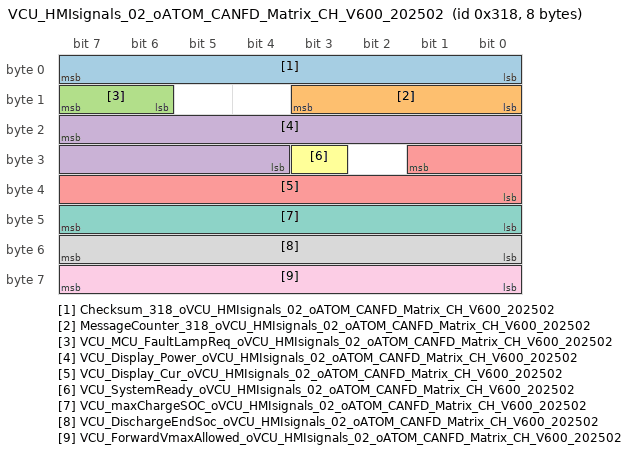
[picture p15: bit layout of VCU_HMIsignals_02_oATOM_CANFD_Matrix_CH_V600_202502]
        frame VCU_HMIsignals_02_oATOM_CANFD_Matrix_CH_V600_202502: id 0x318, from VCU, frame-length=8, can-addressing-mode=STANDARD, can-frame-rx-behavior=ANY, can-frame-tx-behavior=CAN-FD
          pdu VCU_HMIsignals_02_oATOM_CANFD_Matrix_CH_V600_202502: length=8, minimum-delay=0, transmission-mode-false-timing=cyclic-timing={time-offset=0, time-period=0.2}, transmission-mode-true-timing=cyclic-timing={time-offset=0, time-period=0.2}, unused-bit-pattern=0
            signal Checksum_318_oVCU_HMIsignals_02_oATOM_CANFD_Matrix_CH_V600_202502: start 7, 8 bit, big-endian, i-signal-type=PRIMITIVE, init-value=0, base-type=uint8, compu {identical}, range raw 0..255, transfer-property=PENDING  # Checksum signal for frame
            signal MessageCounter_318_oVCU_HMIsignals_02_oATOM_CANFD_Matrix_CH_V600_202502: start 11, 4 bit, big-endian, i-signal-type=PRIMITIVE, init-value=0, base-type=uint8, compu {15=CxF_Invalid}, range raw 0..15, transfer-property=PENDING  # Message counter signal for frame
            signal VCU_MCU_FaultLampReq_oVCU_HMIsignals_02_oATOM_CANFD_Matrix_CH_V600_202502: start 15, 2 bit, big-endian, i-signal-type=PRIMITIVE, init-value=0, base-type=uint8, compu {0=Cx0_No_Request (No Request), 1=Cx1_Yellow_LED_request (Yellow-LED request), 2=Cx2_Red_LED_request (Red-LED request), 3=Cx3_Reserve}, range raw 0..3, transfer-property=PENDING  # MCU failure indicator
            signal VCU_Display_Power_oVCU_HMIsignals_02_oATOM_CANFD_Matrix_CH_V600_202502: start 23, 12 bit, big-endian, i-signal-type=PRIMITIVE, init-value=0, base-type=uint16, compu {phys=raw*0.1 for raw 0..4095; unit kW}, range raw 0..4095, unit=kW, transfer-property=PENDING  # Charge and discharge power (display)
            signal VCU_Display_Cur_oVCU_HMIsignals_02_oATOM_CANFD_Matrix_CH_V600_202502: start 25, 10 bit, big-endian, i-signal-type=PRIMITIVE, init-value=0, base-type=uint16, compu {identical}, range raw 0..1023, unit=A, transfer-property=PENDING  # Charge and discharge current (display)
            signal VCU_SystemReady_oVCU_HMIsignals_02_oATOM_CANFD_Matrix_CH_V600_202502: start 27, 1 bit, big-endian, i-signal-type=PRIMITIVE, init-value=0, base-type=boolean, compu {0=Cx0_Not_Ready (Not Ready), 1=Cx1_Ready}, range raw 0..1, transfer-property=PENDING  # Ready lamp indicator
            signal VCU_maxChargeSOC_oVCU_HMIsignals_02_oATOM_CANFD_Matrix_CH_V600_202502: start 47, 8 bit, big-endian, i-signal-type=PRIMITIVE, init-value=255, base-type=uint8, compu {254=CxFE_No_Request (No Request), 255=CxFF_Invalid}, range raw 0..255, transfer-property=PENDING  # Target charging level setting feedback signal
            signal VCU_DischargeEndSoc_oVCU_HMIsignals_02_oATOM_CANFD_Matrix_CH_V600_202502: start 55, 8 bit, big-endian, i-signal-type=PRIMITIVE, init-value=50, base-type=uint8, compu {identical}, range raw 0..255, unit=percent, transfer-property=PENDING  # Discharge cutoff SOC
            signal VCU_ForwardVmaxAllowed_oVCU_HMIsignals_02_oATOM_CANFD_Matrix_CH_V600_202502: start 63, 8 bit, big-endian, i-signal-type=PRIMITIVE, init-value=0, base-type=uint8, compu {0=Cx00_No_request (No request), 1=Cx01_1_170 (1-170), 2=Cx02_1_170 (1-170), 3=Cx03_1_170 (1-170), 4=Cx04_1_170 (1-170), 5=Cx05_1_170 (1-170), 6=Cx06_1_170 (1-170), 7=Cx07_1_170 (1-170), 8=Cx08_1_170 (1-170), 9=Cx09_1_170 (1-170), 10=Cx0A_1_170 (1-170), 11=Cx0B_1_170 (1-170), 12=Cx0C_1_170 (1-170), 13=Cx0D_1_170 (1-170), 14=Cx0E_1_170 (1-170), 15=Cx0F_1_170 (1-170), 16=Cx10_1_170 (1-170), 17=Cx11_1_170 (1-170), 18=Cx12_1_170 (1-170), 19=Cx13_1_170 (1-170), 20=Cx14_1_170 (1-170), 21=Cx15_1_170 (1-170), 22=Cx16_1_170 (1-170), 23=Cx17_1_170 (1-170), 24=Cx18_1_170 (1-170), 25=Cx19_1_170 (1-170), 26=Cx1A_1_170 (1-170), 27=Cx1B_1_170 (1-170), 28=Cx1C_1_170 (1-170), 29=Cx1D_1_170 (1-170), 30=Cx1E_1_170 (1-170), 31=Cx1F_1_170 (1-170), 32=Cx20_1_170 (1-170), 33=Cx21_1_170 (1-170), 34=Cx22_1_170 (1-170), 35=Cx23_1_170 (1-170), 36=Cx24_1_170 (1-170), 37=Cx25_1_170 (1-170), 38=Cx26_1_170 (1-170), 39=Cx27_1_170 (1-170), 40=Cx28_1_170 (1-170), 41=Cx29_1_170 (1-170), 42=Cx2A_1_170 (1-170), 43=Cx2B_1_170 (1-170), 44=Cx2C_1_170 (1-170), 45=Cx2D_1_170 (1-170), 46=Cx2E_1_170 (1-170), 47=Cx2F_1_170 (1-170), 48=Cx30_1_170 (1-170), 49=Cx31_1_170 (1-170), 50=Cx32_1_170 (1-170), 51=Cx33_1_170 (1-170), 52=Cx34_1_170 (1-170), 53=Cx35_1_170 (1-170), 54=Cx36_1_170 (1-170), 55=Cx37_1_170 (1-170), 56=Cx38_1_170 (1-170), 57=Cx39_1_170 (1-170), 58=Cx3A_1_170 (1-170), 59=Cx3B_1_170 (1-170), 60=Cx3C_1_170 (1-170), 61=Cx3D_1_170 (1-170), 62=Cx3E_1_170 (1-170), 63=Cx3F_1_170 (1-170), 64=Cx40_1_170 (1-170), 65=Cx41_1_170 (1-170), 66=Cx42_1_170 (1-170), 67=Cx43_1_170 (1-170), 68=Cx44_1_170 (1-170), 69=Cx45_1_170 (1-170), 70=Cx46_1_170 (1-170), 71=Cx47_1_170 (1-170), 72=Cx48_1_170 (1-170), 73=Cx49_1_170 (1-170), 74=Cx4A_1_170 (1-170), 75=Cx4B_1_170 (1-170), 76=Cx4C_1_170 (1-170), 77=Cx4D_1_170 (1-170), 78=Cx4E_1_170 (1-170), 79=Cx4F_1_170 (1-170), 80=Cx50_1_170 (1-170), 81=Cx51_1_170 (1-170), 82=Cx52_1_170 (1-170), 83=Cx53_1_170 (1-170), 84=Cx54_1_170 (1-170), 85=Cx55_1_170 (1-170), 86=Cx56_1_170 (1-170), 87=Cx57_1_170 (1-170), 88=Cx58_1_170 (1-170), 89=Cx59_1_170 (1-170), 90=Cx5A_1_170 (1-170), 91=Cx5B_1_170 (1-170), 92=Cx5C_1_170 (1-170), 93=Cx5D_1_170 (1-170), 94=Cx5E_1_170 (1-170), 95=Cx5F_1_170 (1-170), 96=Cx60_1_170 (1-170), 97=Cx61_1_170 (1-170), 98=Cx62_1_170 (1-170), 99=Cx63_1_170 (1-170), 100=Cx64_1_170 (1-170), 101=Cx65_1_170 (1-170), 102=Cx66_1_170 (1-170), 103=Cx67_1_170 (1-170), 104=Cx68_1_170 (1-170), 105=Cx69_1_170 (1-170), 106=Cx6A_1_170 (1-170), 107=Cx6B_1_170 (1-170), 108=Cx6C_1_170 (1-170), 109=Cx6D_1_170 (1-170), 110=Cx6E_1_170 (1-170), 111=Cx6F_1_170 (1-170), 112=Cx70_1_170 (1-170), 113=Cx71_1_170 (1-170), 114=Cx72_1_170 (1-170), 115=Cx73_1_170 (1-170), 116=Cx74_1_170 (1-170), 117=Cx75_1_170 (1-170), 118=Cx76_1_170 (1-170), 119=Cx77_1_170 (1-170), 120=Cx78_1_170 (1-170), 121=Cx79_1_170 (1-170), 122=Cx7A_1_170 (1-170), 123=Cx7B_1_170 (1-170), 124=Cx7C_1_170 (1-170), 125=Cx7D_1_170 (1-170), 126=Cx7E_1_170 (1-170), 127=Cx7F_1_170 (1-170), 128=Cx80_1_170 (1-170), 129=Cx81_1_170 (1-170), 130=Cx82_1_170 (1-170), 131=Cx83_1_170 (1-170), 132=Cx84_1_170 (1-170), 133=Cx85_1_170 (1-170), 134=Cx86_1_170 (1-170), 135=Cx87_1_170 (1-170), 136=Cx88_1_170 (1-170), 137=Cx89_1_170 (1-170), 138=Cx8A_1_170 (1-170), 139=Cx8B_1_170 (1-170), 140=Cx8C_1_170 (1-170), 141=Cx8D_1_170 (1-170), 142=Cx8E_1_170 (1-170), 143=Cx8F_1_170 (1-170), 144=Cx90_1_170 (1-170), 145=Cx91_1_170 (1-170), 146=Cx92_1_170 (1-170), 147=Cx93_1_170 (1-170), 148=Cx94_1_170 (1-170), 149=Cx95_1_170 (1-170), 150=Cx96_1_170 (1-170), 151=Cx97_1_170 (1-170), 152=Cx98_1_170 (1-170), 153=Cx99_1_170 (1-170), 154=Cx9A_1_170 (1-170), 155=Cx9B_1_170 (1-170), 156=Cx9C_1_170 (1-170), 157=Cx9D_1_170 (1-170), 158=Cx9E_1_170 (1-170), 159=Cx9F_1_170 (1-170), 160=CxA0_1_170 (1-170), 161=CxA1_1_170 (1-170), 162=CxA2_1_170 (1-170), 163=CxA3_1_170 (1-170), 164=CxA4_1_170 (1-170), 165=CxA5_1_170 (1-170), 166=CxA6_1_170 (1-170), 167=CxA7_1_170 (1-170), 168=CxA8_1_170 (1-170), 169=CxA9_1_170 (1-170), 170=CxAA_1_170 (1-170), 171=CxAB_Reserved, 172=CxAC_Reserved, 173=CxAD_Reserved, 174=CxAE_Reserved, 175=CxAF_Reserved, 176=CxB0_Reserved, 177=CxB1_Reserved, 178=CxB2_Reserved, 179=CxB3_Reserved, 180=CxB4_Reserved, 181=CxB5_Reserved, 182=CxB6_Reserved, 183=CxB7_Reserved, 184=CxB8_Reserved, 185=CxB9_Reserved, 186=CxBA_Reserved, 187=CxBB_Reserved, 188=CxBC_Reserved, 189=CxBD_Reserved, 190=CxBE_Reserved, 191=CxBF_Reserved, 192=CxC0_Reserved, 193=CxC1_Reserved, 194=CxC2_Reserved, 195=CxC3_Reserved, 196=CxC4_Reserved, 197=CxC5_Reserved, 198=CxC6_Reserved, 199=CxC7_Reserved, 200=CxC8_Reserved, 201=CxC9_Reserved, 202=CxCA_Reserved, 203=CxCB_Reserved, 204=CxCC_Reserved, 205=CxCD_Reserved, 206=CxCE_Reserved, 207=CxCF_Reserved, 208=CxD0_Reserved, 209=CxD1_Reserved, 210=CxD2_Reserved, 211=CxD3_Reserved, 212=CxD4_Reserved, 213=CxD5_Reserved, 214=CxD6_Reserved, 215=CxD7_Reserved, 216=CxD8_Reserved, 217=CxD9_Reserved, 218=CxDA_Reserved, 219=CxDB_Reserved, 220=CxDC_Reserved, 221=CxDD_Reserved, 222=CxDE_Reserved, 223=CxDF_Reserved, 224=CxE0_Reserved, 225=CxE1_Reserved, 226=CxE2_Reserved, 227=CxE3_Reserved, 228=CxE4_Reserved, 229=CxE5_Reserved, 230=CxE6_Reserved, 231=CxE7_Reserved, 232=CxE8_Reserved, 233=CxE9_Reserved, 234=CxEA_Reserved, 235=CxEB_Reserved, 236=CxEC_Reserved, 237=CxED_Reserved, 238=CxEE_Reserved, 239=CxEF_Reserved, 240=CxF0_Reserved, 241=CxF1_Reserved, 242=CxF2_Reserved, 243=CxF3_Reserved, 244=CxF4_Reserved, 245=CxF5_Reserved, 246=CxF6_Reserved, 247=CxF7_Reserved, 248=CxF8_Reserved, 249=CxF9_Reserved, 250=CxFA_Reserved, 251=CxFB_Reserved, 252=CxFC_Reserved, 253=CxFD_Reserved, 254=CxFE_Reserved, 255=CxFF_Reserved}, range raw 0..255, transfer-property=PENDING  # Maximum speed setting state of D gear
            mapping SG_VCU_HMIsignals_02_SigGroup: i-signal-group=SG_VCU_HMIsignals_02_SigGroup_oVCU_HMIsignals_02_oATOM_CANFD_Matrix_CH_V600_202502, transfer-property=PENDING
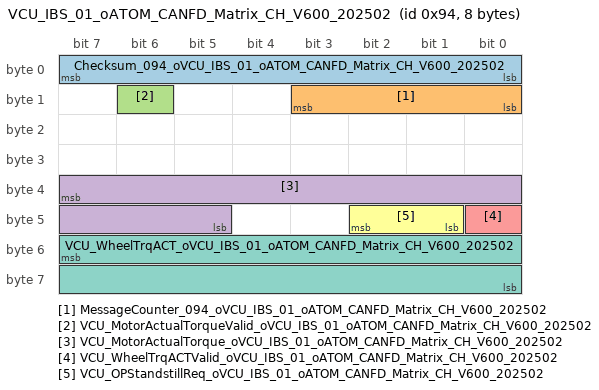
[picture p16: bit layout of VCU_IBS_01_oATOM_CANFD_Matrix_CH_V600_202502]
        frame VCU_IBS_01_oATOM_CANFD_Matrix_CH_V600_202502: id 0x94, from VCU, frame-length=8, can-addressing-mode=STANDARD, can-frame-rx-behavior=ANY, can-frame-tx-behavior=CAN-FD
          pdu VCU_IBS_01_oATOM_CANFD_Matrix_CH_V600_202502: length=8, minimum-delay=0, transmission-mode-false-timing=cyclic-timing={time-offset=0, time-period=0.01}, transmission-mode-true-timing=cyclic-timing={time-offset=0, time-period=0.01}, unused-bit-pattern=0
            signal Checksum_094_oVCU_IBS_01_oATOM_CANFD_Matrix_CH_V600_202502: start 7, 8 bit, big-endian, i-signal-type=PRIMITIVE, init-value=0, base-type=uint8, compu {identical}, range raw 0..255, transfer-property=PENDING  # Checksum signal for frame
            signal MessageCounter_094_oVCU_IBS_01_oATOM_CANFD_Matrix_CH_V600_202502: start 11, 4 bit, big-endian, i-signal-type=PRIMITIVE, init-value=0, base-type=uint8, compu {15=CxF_Invalid}, range raw 0..15, transfer-property=PENDING  # Message counter signal for frame
            signal VCU_MotorActualTorqueValid_oVCU_IBS_01_oATOM_CANFD_Matrix_CH_V600_202502: start 14, 1 bit, big-endian, i-signal-type=PRIMITIVE, init-value=0, base-type=boolean, compu {0=Cx0_Invalid, 1=Cx1_Valid}, range raw 0..1, transfer-property=PENDING  # the actual torque of motor valid
            signal VCU_MotorActualTorque_oVCU_IBS_01_oATOM_CANFD_Matrix_CH_V600_202502: start 39, 11 bit, big-endian, i-signal-type=PRIMITIVE, init-value=0, base-type=uint16, compu {phys=raw-1024 for raw 0..2047}, range raw 0..2047, transfer-property=PENDING  # the actual torque of motor
            signal VCU_WheelTrqACTValid_oVCU_IBS_01_oATOM_CANFD_Matrix_CH_V600_202502: start 40, 1 bit, big-endian, i-signal-type=PRIMITIVE, init-value=0, base-type=boolean, compu {0=Cx0_invalid, 1=Cx1_valid}, range raw 0..1, transfer-property=PENDING  # Actual motor torque on wheel valid
            signal VCU_OPStandstillReq_oVCU_IBS_01_oATOM_CANFD_Matrix_CH_V600_202502: start 42, 2 bit, big-endian, i-signal-type=PRIMITIVE, init-value=0, base-type=uint8, compu {0=Cx0_NO_DEMAND, 1=Cx1_DEMAND, 2=Cx2_Reserve, 3=Cx3_Reserve}, range raw 0..3, transfer-property=PENDING  # the requirement of standstill
            signal VCU_WheelTrqACT_oVCU_IBS_01_oATOM_CANFD_Matrix_CH_V600_202502: start 55, 16 bit, big-endian, i-signal-type=PRIMITIVE, init-value=0, base-type=uint16, compu {phys=raw-20000 for raw 0..40000; unit Nm}, range raw 0..40000, unit=Nm, transfer-property=PENDING  # Actual motor torque on wheel
            mapping SG_VCU_IBS_01_SigGroup: i-signal-group=SG_VCU_IBS_01_SigGroup_oVCU_IBS_01_oATOM_CANFD_Matrix_CH_V600_202502, transfer-property=PENDING
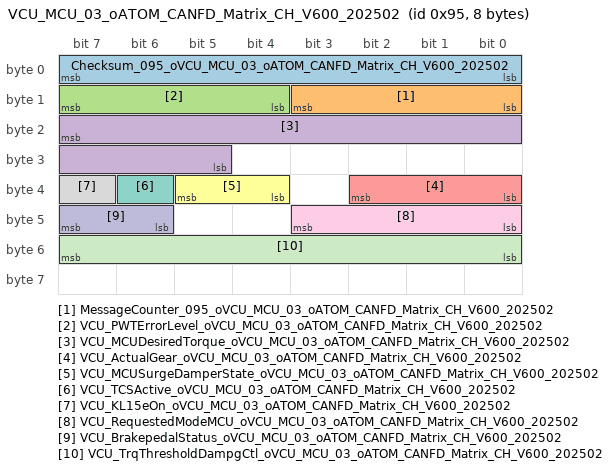
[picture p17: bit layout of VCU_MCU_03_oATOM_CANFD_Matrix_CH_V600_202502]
        frame VCU_MCU_03_oATOM_CANFD_Matrix_CH_V600_202502: id 0x95, from VCU, frame-length=8, can-addressing-mode=STANDARD, can-frame-rx-behavior=ANY, can-frame-tx-behavior=CAN-FD
          pdu VCU_MCU_03_oATOM_CANFD_Matrix_CH_V600_202502: length=8, minimum-delay=0, transmission-mode-false-timing=cyclic-timing={time-offset=0, time-period=0.01}, transmission-mode-true-timing=cyclic-timing={time-offset=0, time-period=0.01}, unused-bit-pattern=0
            signal Checksum_095_oVCU_MCU_03_oATOM_CANFD_Matrix_CH_V600_202502: start 7, 8 bit, big-endian, i-signal-type=PRIMITIVE, init-value=0, base-type=uint8, compu {identical}, range raw 0..255, transfer-property=PENDING  # Checksum signal for frame
            signal MessageCounter_095_oVCU_MCU_03_oATOM_CANFD_Matrix_CH_V600_202502: start 11, 4 bit, big-endian, i-signal-type=PRIMITIVE, init-value=0, base-type=uint8, compu {15=CxF_Invalid}, range raw 0..15, transfer-property=PENDING  # Message counter signal for frame
            signal VCU_PWTErrorLevel_oVCU_MCU_03_oATOM_CANFD_Matrix_CH_V600_202502: start 15, 4 bit, big-endian, i-signal-type=PRIMITIVE, init-value=0, base-type=uint8, compu {0=Cx0_Fault_Level0 (Fault Level0), 1=Cx1_Fault_Level1 (Fault Level1), 2=Cx2_Fault_Level2 (Fault Level2), 3=Cx3_Fault_Level3 (Fault Level3), 4=Cx4_Fault_Level4 (Fault Level4), 5=Cx5_Fault_Level5 (Fault Level5), 6=Cx6_Fault_Level6 (Fault Level6), 7=Cx7_Fault_Level7 (Fault Level7), 8=Cx8_Fault_Level8 (Fault Level8), 9=Cx9_Fault_Level9 (Fault Level9), 10=CxA_Fault_Level10 (Fault Level10), 11=CxB_Fault_Level11 (Fault Level11), 12=CxC_Fault_Level12 (Fault Level12), 13=CxD_Fault_Level13 (Fault Level13), 14=CxE_Fault_Level14 (Fault Level14), 15=CxF_Fault_Level15 (Fault Level15)}, range raw 0..15, transfer-property=PENDING  # Fault level of the power domain
            signal VCU_MCUDesiredTorque_oVCU_MCU_03_oATOM_CANFD_Matrix_CH_V600_202502: start 23, 11 bit, big-endian, i-signal-type=PRIMITIVE, init-value=0, base-type=uint16, compu {2046=Cx7FE_Init, 2047=Cx7FF_Error, phys=raw-1023 for raw 0..2045; unit Nm} "Source signal range: [0,2045]", range raw 0..2047, unit=Nm, transfer-property=PENDING  # Desired torque electric machine
            signal VCU_ActualGear_oVCU_MCU_03_oATOM_CANFD_Matrix_CH_V600_202502: start 34, 3 bit, big-endian, i-signal-type=PRIMITIVE, init-value=0, base-type=uint8, compu {0=Cx0_Reserve, 1=Cx1_P, 2=Cx2_N, 3=Cx3_R, 4=Cx4_D}, range raw 0..4, transfer-property=PENDING  # The actual gear status
            signal VCU_MCUSurgeDamperState_oVCU_MCU_03_oATOM_CANFD_Matrix_CH_V600_202502: start 37, 2 bit, big-endian, i-signal-type=PRIMITIVE, init-value=0, base-type=uint8, compu {0=Cx0_DstC_off, 1=Cx1_DstC_ext, 2=Cx2_DstC_int_ext; unit SED}, range raw 0..2, unit=SED, transfer-property=PENDING  # Requested surge damper state
            signal VCU_TCSActive_oVCU_MCU_03_oATOM_CANFD_Matrix_CH_V600_202502: start 38, 1 bit, big-endian, i-signal-type=PRIMITIVE, init-value=0, base-type=boolean, compu {0=Cx0_NotActive, 1=Cx1_Active}, range raw 0..1, transfer-property=PENDING  # EN: Tindicates TCS intervention active,TCS will detect spinning wheels and request torque reduction/limitation
            signal VCU_KL15eOn_oVCU_MCU_03_oATOM_CANFD_Matrix_CH_V600_202502: start 39, 1 bit, big-endian, i-signal-type=PRIMITIVE, init-value=0, base-type=boolean, compu {0=Cx0_Off, 1=Cx1_On}, range raw 0..1, transfer-property=PENDING  # the bit status of KL15e signal
            signal VCU_RequestedModeMCU_oVCU_MCU_03_oATOM_CANFD_Matrix_CH_V600_202502: start 43, 4 bit, big-endian, i-signal-type=PRIMITIVE, init-value=0, base-type=uint8, compu {0=Cx0_Ready, 1=Cx1_TrqCtrl, 2=Cx2_Active_Hearting (Active Hearting), 3=Cx3_Discharge, 4=Cx4_SpeedCtrl}, range raw 0..4, transfer-property=PENDING  # Request to the electric machine
            signal VCU_BrakepedalStatus_oVCU_MCU_03_oATOM_CANFD_Matrix_CH_V600_202502: start 47, 2 bit, big-endian, i-signal-type=PRIMITIVE, init-value=0, base-type=uint8, compu {0=Cx0_No_pressed (No pressed), 1=Cx1_pressed, 2=Cx2_Invalid}, range raw 0..2, transfer-property=PENDING  # the break pedal status
            signal VCU_TrqThresholdDampgCtl_oVCU_MCU_03_oATOM_CANFD_Matrix_CH_V600_202502: start 55, 8 bit, big-endian, i-signal-type=PRIMITIVE, init-value=0, base-type=uint8, compu {254=CxFE_Init, 255=CxFF_Error, phys=raw*0.1 for raw 0..250; unit Nm} "Source signal range: [0,250]", range raw 0..255, unit=Nm, transfer-property=PENDING  # Threshold torque for damping control
            mapping SG_VCU_MCU_03_SigGroup: i-signal-group=SG_VCU_MCU_03_SigGroup_oVCU_MCU_03_oATOM_CANFD_Matrix_CH_V600_202502, transfer-property=PENDING
        frame VCU_PlugInChrgInfo_oATOM_CANFD_Matrix_CH_V600_202502: id 0x391, from VCU, frame-length=8, can-addressing-mode=STANDARD, can-frame-rx-behavior=ANY, can-frame-tx-behavior=CAN-FD
          pdu VCU_PlugInChrgInfo_oATOM_CANFD_Matrix_CH_V600_202502: length=8, minimum-delay=0, transmission-mode-false-timing=cyclic-timing={time-offset=0, time-period=0.2}, transmission-mode-true-timing=cyclic-timing={time-offset=0, time-period=0.2}, unused-bit-pattern=0
            signal VCU_RemainChrgTime_oVCU_PlugInChrgInfo_oATOM_CANFD_Matrix_CH_V600_202502: start 7, 12 bit, big-endian, i-signal-type=PRIMITIVE, init-value=0, base-type=uint16, compu {1022=Cx3FE_Init, 1023=Cx3FF_Error; unit min}, range raw 0..3600, unit=min, transfer-property=PENDING  # Remaining charging time (displayed)
            signal VCU_DischargeEndReason_oVCU_PlugInChrgInfo_oATOM_CANFD_Matrix_CH_V600_202502: start 34, 2 bit, big-endian, i-signal-type=PRIMITIVE, init-value=0, base-type=uint8, compu {0=Cx0_No_Display (No Display), 1=Cx1_Reach_the_discharge_cut_off_SOC (Reach the discharge cut-off SOC), 2=Cx2_reserved, 3=Cx3_reserved}, range raw 0..3, transfer-property=PENDING  # Reason for stopping discharging
            signal VCU_ChargeEndReason_oVCU_PlugInChrgInfo_oATOM_CANFD_Matrix_CH_V600_202502: start 36, 2 bit, big-endian, i-signal-type=PRIMITIVE, init-value=0, base-type=uint8, compu {0=Cx0_No_Display (No Display), 1=Cx1_Reach_the_charge_cut_off_SOC (Reach the charge cut-off SOC), 2=Cx2_reserved, 3=Cx3_reserved}, range raw 0..3, transfer-property=PENDING  # Reason for stopping charging
            signal VCU_HVConnectFault_oVCU_PlugInChrgInfo_oATOM_CANFD_Matrix_CH_V600_202502: start 37, 1 bit, big-endian, i-signal-type=PRIMITIVE, init-value=0, base-type=boolean, compu {0=Cx0_Normal, 1=Cx1_Fault}, range raw 0..1, transfer-property=PENDING  # Local high voltage failure prompt
            mapping SG_VCU_PlugInChrgInfo_SigGroup: i-signal-group=SG_VCU_PlugInChrgInfo_SigGroup_oVCU_PlugInChrgInfo_oATOM_CANFD_Matrix_CH_V600_202502, transfer-property=PENDING
    TC37X_VCU_CAN00: baudrate=500000  # VCU_CAN00
      can physical channel CHNL: comm-connectors=CN_TC37X_VCU_CAN00
        frame VCU_Rx_500h_NM_oTC37X_VCU_CAN00: id 0x500, to VCU, frame-length=8, can-addressing-mode=STANDARD
          nm pdu VCU_Rx_500h_NM_oTC37X_VCU_CAN00: length=8, unused-bit-pattern=0
        frame VCU_Tx_51Ch_NM_oTC37X_VCU_CAN00: id 0x51C, from VCU, frame-length=8, can-addressing-mode=STANDARD
          nm pdu VCU_Tx_51Ch_NM_oTC37X_VCU_CAN00: length=8, unused-bit-pattern=0
        frame Vcu_Uds_Func_Request_oTC37X_VCU_CAN00: id 0x700, to VCU, frame-length=8, can-addressing-mode=STANDARD
          n pdu Vcu_Uds_Func_Request_Tp_oTC37X_VCU_CAN00: length=8
        frame Vcu_Uds_Phy_Request_oTC37X_VCU_CAN00: id 0x701, to VCU, frame-length=8, can-addressing-mode=STANDARD
          n pdu Vcu_Uds_Phy_Request_Tp_oTC37X_VCU_CAN00: length=8
        frame Vcu_Uds_Response_oTC37X_VCU_CAN00: id 0x781, from VCU, frame-length=8, can-addressing-mode=STANDARD
          n pdu Vcu_Uds_Response_Tp_oTC37X_VCU_CAN00: length=8
        frame VcuRxMsg1_oTC37X_VCU_CAN00: id 0x200, to VCU, frame-length=8, can-addressing-mode=STANDARD
          pdu VcuRxMsg1_oTC37X_VCU_CAN00: length=8, minimum-delay=0, transmission-mode-false-timing=cyclic-timing={time-offset=0, time-period=0.5}, transmission-mode-true-timing=cyclic-timing={time-offset=0, time-period=0.5}, unused-bit-pattern=0
            signal VcuRxMsg1_Sig0_oVcuRxMsg1_oTC37X_VCU_CAN00: start 0, 16 bit, little-endian, i-signal-type=PRIMITIVE, init-value=0, base-type=sint16, compu {identical}, range raw -32768..32767, transfer-property=PENDING, to VCU
            signal VcuRxMsg1_Sig1_oVcuRxMsg1_oTC37X_VCU_CAN00: start 16, 16 bit, little-endian, i-signal-type=PRIMITIVE, init-value=0, base-type=sint16, compu {identical}, range raw -32768..32767, transfer-property=PENDING, to VCU
            signal VcuRxMsg1_Sig2_oVcuRxMsg1_oTC37X_VCU_CAN00: start 32, 16 bit, little-endian, i-signal-type=PRIMITIVE, init-value=0, base-type=sint16, compu {identical}, range raw -32768..32767, transfer-property=PENDING, to VCU
            signal VcuRxMsg1_Sig3_oVcuRxMsg1_oTC37X_VCU_CAN00: start 48, 16 bit, little-endian, i-signal-type=PRIMITIVE, init-value=0, base-type=sint16, compu {identical}, range raw -32768..32767, transfer-property=PENDING, to VCU
        frame VcuRxMsg2_oTC37X_VCU_CAN00: id 0x201, to VCU, frame-length=8, can-addressing-mode=STANDARD
          pdu VcuRxMsg2_oTC37X_VCU_CAN00: length=8, minimum-delay=0, transmission-mode-false-timing=cyclic-timing={time-offset=0, time-period=0.5}, transmission-mode-true-timing=cyclic-timing={time-offset=0, time-period=0.5}, unused-bit-pattern=0
            signal VcuRxMsg2_Sig0_oVcuRxMsg2_oTC37X_VCU_CAN00: start 0, 16 bit, little-endian, i-signal-type=PRIMITIVE, init-value=0, base-type=sint16, compu {identical}, range raw -32768..32767, transfer-property=PENDING, to VCU
            signal VcuRxMsg2_Sig1_oVcuRxMsg2_oTC37X_VCU_CAN00: start 16, 16 bit, little-endian, i-signal-type=PRIMITIVE, init-value=0, base-type=sint16, compu {identical}, range raw -32768..32767, transfer-property=PENDING, to VCU
            signal VcuRxMsg2_Sig2_oVcuRxMsg2_oTC37X_VCU_CAN00: start 32, 16 bit, little-endian, i-signal-type=PRIMITIVE, init-value=0, base-type=sint16, compu {identical}, range raw -32768..32767, transfer-property=PENDING, to VCU
            signal VcuRxMsg2_Sig3_oVcuRxMsg2_oTC37X_VCU_CAN00: start 48, 16 bit, little-endian, i-signal-type=PRIMITIVE, init-value=0, base-type=sint16, compu {identical}, range raw -32768..32767, transfer-property=PENDING, to VCU
        frame VcuTxIoMsg1_oTC37X_VCU_CAN00: id 0x104, from VCU, frame-length=8, can-addressing-mode=STANDARD
          pdu VcuTxIoMsg1_oTC37X_VCU_CAN00: length=8, minimum-delay=0, transmission-mode-false-timing=cyclic-timing={time-offset=0, time-period=0.5}, transmission-mode-true-timing=cyclic-timing={time-offset=0, time-period=0.5}, unused-bit-pattern=0
            signal EXT_A_IN1_oVcuTxIoMsg1_oTC37X_VCU_CAN00: start 0, 16 bit, little-endian, i-signal-type=PRIMITIVE, init-value=0, base-type=sint16, compu {identical}, range raw -256..255, unit=¡ãC, transfer-property=PENDING
            signal EXT1_Valid_oVcuTxIoMsg1_oTC37X_VCU_CAN00: start 16, 16 bit, little-endian, i-signal-type=PRIMITIVE, init-value=0, base-type=uint16, compu {identical}, range raw 0..1, transfer-property=PENDING
            signal EXT_A_IN2_oVcuTxIoMsg1_oTC37X_VCU_CAN00: start 32, 16 bit, little-endian, i-signal-type=PRIMITIVE, init-value=0, base-type=sint16, compu {identical}, range raw -32768..32767, unit=¡ãC, transfer-property=PENDING
            signal EXT2_Valid_oVcuTxIoMsg1_oTC37X_VCU_CAN00: start 48, 16 bit, little-endian, i-signal-type=PRIMITIVE, init-value=0, base-type=uint16, compu {identical}, range raw 0..1, transfer-property=PENDING
        frame VcuTxIoMsg2_oTC37X_VCU_CAN00: id 0x105, from VCU, frame-length=8, can-addressing-mode=STANDARD
          pdu VcuTxIoMsg2_oTC37X_VCU_CAN00: length=8, minimum-delay=0, transmission-mode-false-timing=cyclic-timing={time-offset=0, time-period=0.5}, transmission-mode-true-timing=cyclic-timing={time-offset=0, time-period=0.5}, unused-bit-pattern=0
            signal EXT_A_IN3_oVcuTxIoMsg2_oTC37X_VCU_CAN00: start 0, 16 bit, little-endian, i-signal-type=PRIMITIVE, init-value=0, base-type=sint16, compu {identical}, range raw -256..255, unit=¡ãC, transfer-property=PENDING
            signal EXT3_Valid_oVcuTxIoMsg2_oTC37X_VCU_CAN00: start 16, 16 bit, little-endian, i-signal-type=PRIMITIVE, init-value=0, base-type=uint16, compu {identical}, range raw 0..1, transfer-property=PENDING
            signal EXT_A_IN4_oVcuTxIoMsg2_oTC37X_VCU_CAN00: start 32, 16 bit, little-endian, i-signal-type=PRIMITIVE, init-value=0, base-type=sint16, compu {identical}, range raw -32768..32767, unit=¡ãC, transfer-property=PENDING
            signal EXT4_Valid_oVcuTxIoMsg2_oTC37X_VCU_CAN00: start 48, 16 bit, little-endian, i-signal-type=PRIMITIVE, init-value=0, base-type=uint16, compu {identical}, range raw 0..1, transfer-property=PENDING
        frame VcuTxIoMsg3_oTC37X_VCU_CAN00: id 0x106, from VCU, frame-length=8, can-addressing-mode=STANDARD
          pdu VcuTxIoMsg3_oTC37X_VCU_CAN00: length=8, minimum-delay=0, transmission-mode-false-timing=cyclic-timing={time-offset=0, time-period=0.5}, transmission-mode-true-timing=cyclic-timing={time-offset=0, time-period=0.5}, unused-bit-pattern=0
            signal EXT_A_IN5_oVcuTxIoMsg3_oTC37X_VCU_CAN00: start 0, 16 bit, little-endian, i-signal-type=PRIMITIVE, init-value=0, base-type=sint16, compu {identical}, range raw -256..255, unit=¡ãC, transfer-property=PENDING
            signal EXT5_Valid_oVcuTxIoMsg3_oTC37X_VCU_CAN00: start 16, 16 bit, little-endian, i-signal-type=PRIMITIVE, init-value=0, base-type=uint16, compu {identical}, range raw 0..1, transfer-property=PENDING
            signal EXT_A_IN6_oVcuTxIoMsg3_oTC37X_VCU_CAN00: start 32, 16 bit, little-endian, i-signal-type=PRIMITIVE, init-value=0, base-type=sint16, compu {identical}, range raw -32768..32767, unit=¡ãC, transfer-property=PENDING
            signal EXT6_Valid_oVcuTxIoMsg3_oTC37X_VCU_CAN00: start 48, 16 bit, little-endian, i-signal-type=PRIMITIVE, init-value=0, base-type=uint16, compu {identical}, range raw 0..1, transfer-property=PENDING
        frame VcuTxIoMsg4_oTC37X_VCU_CAN00: id 0x107, from VCU, frame-length=8, can-addressing-mode=STANDARD
          pdu VcuTxIoMsg4_oTC37X_VCU_CAN00: length=8, minimum-delay=0, transmission-mode-false-timing=cyclic-timing={time-offset=0, time-period=0.5}, transmission-mode-true-timing=cyclic-timing={time-offset=0, time-period=0.5}, unused-bit-pattern=0
            signal EXT_A_IN7_oVcuTxIoMsg4_oTC37X_VCU_CAN00: start 0, 16 bit, little-endian, i-signal-type=PRIMITIVE, init-value=0, base-type=sint16, compu {identical}, range raw -256..255, unit=¡ãC, transfer-property=PENDING
            signal EXT7_Valid_oVcuTxIoMsg4_oTC37X_VCU_CAN00: start 16, 16 bit, little-endian, i-signal-type=PRIMITIVE, init-value=0, base-type=uint16, compu {identical}, range raw 0..1, transfer-property=PENDING
            signal EXT_A_IN8_oVcuTxIoMsg4_oTC37X_VCU_CAN00: start 32, 16 bit, little-endian, i-signal-type=PRIMITIVE, init-value=0, base-type=sint16, compu {identical}, range raw -32768..32767, unit=¡ãC, transfer-property=PENDING
            signal EXT8_Valid_oVcuTxIoMsg4_oTC37X_VCU_CAN00: start 48, 16 bit, little-endian, i-signal-type=PRIMITIVE, init-value=0, base-type=uint16, compu {identical}, range raw 0..1, transfer-property=PENDING
        frame VcuTxIoMsg5_oTC37X_VCU_CAN00: id 0x108, from VCU, frame-length=8, can-addressing-mode=STANDARD
          pdu VcuTxIoMsg5_oTC37X_VCU_CAN00: length=8, minimum-delay=0, transmission-mode-false-timing=cyclic-timing={time-offset=0, time-period=0.5}, transmission-mode-true-timing=cyclic-timing={time-offset=0, time-period=0.5}, unused-bit-pattern=0
            signal EXT_A_IN9_oVcuTxIoMsg5_oTC37X_VCU_CAN00: start 0, 16 bit, little-endian, i-signal-type=PRIMITIVE, init-value=0, base-type=sint16, compu {identical}, range raw -256..255, unit=¡ãC, transfer-property=PENDING
            signal EXT9_Valid_oVcuTxIoMsg5_oTC37X_VCU_CAN00: start 16, 16 bit, little-endian, i-signal-type=PRIMITIVE, init-value=0, base-type=uint16, compu {identical}, range raw 0..1, transfer-property=PENDING
            signal EXT_A_IN10_oVcuTxIoMsg5_oTC37X_VCU_CAN00: start 32, 16 bit, little-endian, i-signal-type=PRIMITIVE, init-value=0, base-type=sint16, compu {identical}, range raw -32768..32767, unit=¡ãC, transfer-property=PENDING
            signal EXT10_Valid_oVcuTxIoMsg5_oTC37X_VCU_CAN00: start 48, 16 bit, little-endian, i-signal-type=PRIMITIVE, init-value=0, base-type=uint16, compu {identical}, range raw 0..1, transfer-property=PENDING
        frame VcuTxIoMsg6_oTC37X_VCU_CAN00: id 0x109, from VCU, frame-length=8, can-addressing-mode=STANDARD
          pdu VcuTxIoMsg6_oTC37X_VCU_CAN00: length=8, minimum-delay=0, transmission-mode-false-timing=cyclic-timing={time-offset=0, time-period=0.5}, transmission-mode-true-timing=cyclic-timing={time-offset=0, time-period=0.5}, unused-bit-pattern=0
            signal EXT_A_IN11_oVcuTxIoMsg6_oTC37X_VCU_CAN00: start 0, 16 bit, little-endian, i-signal-type=PRIMITIVE, init-value=0, base-type=sint16, compu {identical}, range raw -256..255, unit=¡ãC, transfer-property=PENDING
            signal EXT11_Valid_oVcuTxIoMsg6_oTC37X_VCU_CAN00: start 16, 16 bit, little-endian, i-signal-type=PRIMITIVE, init-value=0, base-type=uint16, compu {identical}, range raw 0..1, transfer-property=PENDING
            signal EXT_A_IN12_oVcuTxIoMsg6_oTC37X_VCU_CAN00: start 32, 16 bit, little-endian, i-signal-type=PRIMITIVE, init-value=0, base-type=sint16, compu {identical}, range raw -32768..32767, unit=¡ãC, transfer-property=PENDING
            signal EXT12_Valid_oVcuTxIoMsg6_oTC37X_VCU_CAN00: start 48, 16 bit, little-endian, i-signal-type=PRIMITIVE, init-value=0, base-type=uint16, compu {identical}, range raw 0..1, transfer-property=PENDING
        frame VcuTxIoMsg7_oTC37X_VCU_CAN00: id 0x10A, from VCU, frame-length=8, can-addressing-mode=STANDARD
          pdu VcuTxIoMsg7_oTC37X_VCU_CAN00: length=8, minimum-delay=0, transmission-mode-false-timing=cyclic-timing={time-offset=0, time-period=0.5}, transmission-mode-true-timing=cyclic-timing={time-offset=0, time-period=0.5}, unused-bit-pattern=0
            signal EXT_A_IN13_oVcuTxIoMsg7_oTC37X_VCU_CAN00: start 0, 16 bit, little-endian, i-signal-type=PRIMITIVE, init-value=0, base-type=sint16, compu {identical}, range raw -256..255, unit=¡ãC, transfer-property=PENDING
            signal EXT13_Valid_oVcuTxIoMsg7_oTC37X_VCU_CAN00: start 16, 16 bit, little-endian, i-signal-type=PRIMITIVE, init-value=0, base-type=uint16, compu {identical}, range raw 0..1, transfer-property=PENDING
            signal EXT_A_IN14_oVcuTxIoMsg7_oTC37X_VCU_CAN00: start 32, 16 bit, little-endian, i-signal-type=PRIMITIVE, init-value=0, base-type=sint16, compu {identical}, range raw -32768..32767, unit=¡ãC, transfer-property=PENDING
            signal EXT14_Valid_oVcuTxIoMsg7_oTC37X_VCU_CAN00: start 48, 16 bit, little-endian, i-signal-type=PRIMITIVE, init-value=0, base-type=uint16, compu {identical}, range raw 0..1, transfer-property=PENDING
        frame VcuTxIoMsg8_oTC37X_VCU_CAN00: id 0x10B, from VCU, frame-length=8, can-addressing-mode=STANDARD
          pdu VcuTxIoMsg8_oTC37X_VCU_CAN00: length=8, minimum-delay=0, transmission-mode-false-timing=cyclic-timing={time-offset=0, time-period=0.5}, transmission-mode-true-timing=cyclic-timing={time-offset=0, time-period=0.5}, unused-bit-pattern=0
            signal EXT_A_IN15_oVcuTxIoMsg8_oTC37X_VCU_CAN00: start 0, 16 bit, little-endian, i-signal-type=PRIMITIVE, init-value=0, base-type=sint16, compu {identical}, range raw -256..255, unit=¡ãC, transfer-property=PENDING
            signal EXT15_Valid_oVcuTxIoMsg8_oTC37X_VCU_CAN00: start 16, 16 bit, little-endian, i-signal-type=PRIMITIVE, init-value=0, base-type=uint16, compu {identical}, range raw 0..1, transfer-property=PENDING
            signal EXT_A_IN16_oVcuTxIoMsg8_oTC37X_VCU_CAN00: start 32, 16 bit, little-endian, i-signal-type=PRIMITIVE, init-value=0, base-type=sint16, compu {identical}, range raw -32768..32767, unit=¡ãC, transfer-property=PENDING
            signal EXT16_Valid_oVcuTxIoMsg8_oTC37X_VCU_CAN00: start 48, 16 bit, little-endian, i-signal-type=PRIMITIVE, init-value=0, base-type=uint16, compu {identical}, range raw 0..1, transfer-property=PENDING
        frame VcuTxMsg1_oTC37X_VCU_CAN00: id 0x100, from VCU, frame-length=8, can-addressing-mode=STANDARD
          pdu VcuTxMsg1_oTC37X_VCU_CAN00: length=8, minimum-delay=0, transmission-mode-false-timing=cyclic-timing={time-offset=0, time-period=0.5}, transmission-mode-true-timing=cyclic-timing={time-offset=0, time-period=0.5}, unused-bit-pattern=0
            signal VcuTxMsg1_Sig0_oVcuTxMsg1_oTC37X_VCU_CAN00: start 0, 16 bit, little-endian, i-signal-type=PRIMITIVE, init-value=0, base-type=sint16, compu {identical}, range raw -32768..32767, transfer-property=PENDING
            signal VcuTxMsg1_Sig1_oVcuTxMsg1_oTC37X_VCU_CAN00: start 16, 16 bit, little-endian, i-signal-type=PRIMITIVE, init-value=0, base-type=sint16, compu {identical}, range raw -32768..32767, transfer-property=PENDING
            signal VcuTxMsg1_Sig2_oVcuTxMsg1_oTC37X_VCU_CAN00: start 32, 16 bit, little-endian, i-signal-type=PRIMITIVE, init-value=0, base-type=sint16, compu {identical}, range raw -32768..32767, transfer-property=PENDING
            signal VcuTxMsg1_Sig3_oVcuTxMsg1_oTC37X_VCU_CAN00: start 48, 16 bit, little-endian, i-signal-type=PRIMITIVE, init-value=0, base-type=sint16, compu {identical}, range raw -32768..32767, transfer-property=PENDING
        frame VcuTxMsg2_oTC37X_VCU_CAN00: id 0x101, from VCU, frame-length=8, can-addressing-mode=STANDARD
          pdu VcuTxMsg2_oTC37X_VCU_CAN00: length=8, minimum-delay=0, transmission-mode-false-timing=cyclic-timing={time-offset=0, time-period=0.5}, transmission-mode-true-timing=cyclic-timing={time-offset=0, time-period=0.5}, unused-bit-pattern=0
            signal VcuTxMsg2_Sig0_oVcuTxMsg2_oTC37X_VCU_CAN00: start 0, 16 bit, little-endian, i-signal-type=PRIMITIVE, init-value=0, base-type=sint16, compu {identical}, range raw -32768..32767, transfer-property=PENDING
            signal VcuTxMsg2_Sig1_oVcuTxMsg2_oTC37X_VCU_CAN00: start 16, 16 bit, little-endian, i-signal-type=PRIMITIVE, init-value=0, base-type=sint16, compu {identical}, range raw -32768..32767, transfer-property=PENDING
            signal VcuTxMsg2_Sig2_oVcuTxMsg2_oTC37X_VCU_CAN00: start 32, 16 bit, little-endian, i-signal-type=PRIMITIVE, init-value=0, base-type=sint16, compu {identical}, range raw -32768..32767, transfer-property=PENDING
            signal VcuTxMsg2_Sig3_oVcuTxMsg2_oTC37X_VCU_CAN00: start 48, 16 bit, little-endian, i-signal-type=PRIMITIVE, init-value=0, base-type=sint16, compu {identical}, range raw -32768..32767, transfer-property=PENDING
        frame XCP_Request_oTC37X_VCU_CAN00: id 0x606, to VCU, frame-length=8, can-addressing-mode=STANDARD
          xcp pdu XCP_Request_oTC37X_VCU_CAN00: length=8
        frame XCP_Response_oTC37X_VCU_CAN00: id 0x607, from VCU, frame-length=8, can-addressing-mode=STANDARD
          xcp pdu XCP_Response_oTC37X_VCU_CAN00: length=8
        pdu triggering PT_Vcu_Uds_Func_Request: pdu=Vcu_Uds_Func_Request_oTC37X_VCU_CAN00, to VCU
        pdu triggering PT_Vcu_Uds_Phy_Request: pdu=Vcu_Uds_Phy_Request_oTC37X_VCU_CAN00, to VCU
        pdu triggering PT_Vcu_Uds_Response: pdu=Vcu_Uds_Response_oTC37X_VCU_CAN00, from VCU
    TC37X_VCU_CAN01: baudrate=500000  # VCU_CAN01
      can physical channel CHNL: comm-connectors=CN_TC37X_VCU_CAN01
        frame VCU_Rx_500h_NM_oTC37X_VCU_CAN01: id 0x500, to VCU, frame-length=8, can-addressing-mode=STANDARD
          nm pdu VCU_Rx_500h_NM_oTC37X_VCU_CAN01: length=8, unused-bit-pattern=0
        frame VCU_Tx_51Ch_NM_oTC37X_VCU_CAN01: id 0x51C, from VCU, frame-length=8, can-addressing-mode=STANDARD
          nm pdu VCU_Tx_51Ch_NM_oTC37X_VCU_CAN01: length=8, unused-bit-pattern=0
        frame VcuAdcTxG0Msg0_oTC37X_VCU_CAN01: id 0x102, from VCU, frame-length=8, can-addressing-mode=STANDARD
          pdu VcuAdcTxG0Msg0_oTC37X_VCU_CAN01: length=8, minimum-delay=0, transmission-mode-false-timing=cyclic-timing={time-offset=0, time-period=0.5}, transmission-mode-true-timing=cyclic-timing={time-offset=0, time-period=0.5}, unused-bit-pattern=0
            signal AN0_oVcuAdcTxG0Msg0_oTC37X_VCU_CAN01: start 0, 16 bit, little-endian, i-signal-type=PRIMITIVE, init-value=0, base-type=sint16, compu {identical}, range raw -32768..32767, unit=mV, transfer-property=PENDING
            signal AN1_oVcuAdcTxG0Msg0_oTC37X_VCU_CAN01: start 16, 16 bit, little-endian, i-signal-type=PRIMITIVE, init-value=0, base-type=sint16, compu {identical}, range raw -32768..32767, unit=mV, transfer-property=PENDING
            signal AN2_oVcuAdcTxG0Msg0_oTC37X_VCU_CAN01: start 32, 16 bit, little-endian, i-signal-type=PRIMITIVE, init-value=0, base-type=sint16, compu {identical}, range raw -32768..32767, unit=mV, transfer-property=PENDING
            signal AN3_oVcuAdcTxG0Msg0_oTC37X_VCU_CAN01: start 48, 16 bit, little-endian, i-signal-type=PRIMITIVE, init-value=0, base-type=sint16, compu {identical}, range raw -32768..32767, unit=mV, transfer-property=PENDING
        frame VcuAdcTxG0Msg1_oTC37X_VCU_CAN01: id 0x103, from VCU, frame-length=8, can-addressing-mode=STANDARD
          pdu VcuAdcTxG0Msg1_oTC37X_VCU_CAN01: length=8, minimum-delay=0, transmission-mode-false-timing=cyclic-timing={time-offset=0, time-period=0.5}, transmission-mode-true-timing=cyclic-timing={time-offset=0, time-period=0.5}, unused-bit-pattern=0
            signal AN4_oVcuAdcTxG0Msg1_oTC37X_VCU_CAN01: start 0, 16 bit, little-endian, i-signal-type=PRIMITIVE, init-value=0, base-type=sint16, compu {identical}, range raw -32768..32767, unit=mV, transfer-property=PENDING
            signal AN5_oVcuAdcTxG0Msg1_oTC37X_VCU_CAN01: start 16, 16 bit, little-endian, i-signal-type=PRIMITIVE, init-value=0, base-type=sint16, compu {identical}, range raw -32768..32767, unit=mV, transfer-property=PENDING
            signal AN6_oVcuAdcTxG0Msg1_oTC37X_VCU_CAN01: start 32, 16 bit, little-endian, i-signal-type=PRIMITIVE, init-value=0, base-type=sint16, compu {identical}, range raw -32768..32767, unit=mV, transfer-property=PENDING
            signal AN7_oVcuAdcTxG0Msg1_oTC37X_VCU_CAN01: start 48, 16 bit, little-endian, i-signal-type=PRIMITIVE, init-value=0, base-type=sint16, compu {identical}, range raw -32768..32767, unit=mV, transfer-property=PENDING
        frame VcuAdcTxG1Msg0_oTC37X_VCU_CAN01: id 0x104, from VCU, frame-length=8, can-addressing-mode=STANDARD
          pdu VcuAdcTxG1Msg0_oTC37X_VCU_CAN01: length=8, minimum-delay=0, transmission-mode-false-timing=cyclic-timing={time-offset=0, time-period=0.5}, transmission-mode-true-timing=cyclic-timing={time-offset=0, time-period=0.5}, unused-bit-pattern=0
            signal AN8_oVcuAdcTxG1Msg0_oTC37X_VCU_CAN01: start 0, 16 bit, little-endian, i-signal-type=PRIMITIVE, init-value=0, base-type=sint16, compu {identical}, range raw -32768..32767, unit=mV, transfer-property=PENDING
            signal AN9_oVcuAdcTxG1Msg0_oTC37X_VCU_CAN01: start 16, 16 bit, little-endian, i-signal-type=PRIMITIVE, init-value=0, base-type=sint16, compu {identical}, range raw -32768..32767, unit=mV, transfer-property=PENDING
            signal AN10_oVcuAdcTxG1Msg0_oTC37X_VCU_CAN01: start 32, 16 bit, little-endian, i-signal-type=PRIMITIVE, init-value=0, base-type=sint16, compu {identical}, range raw -32768..32767, unit=mV, transfer-property=PENDING
            signal AN11_oVcuAdcTxG1Msg0_oTC37X_VCU_CAN01: start 48, 16 bit, little-endian, i-signal-type=PRIMITIVE, init-value=0, base-type=sint16, compu {identical}, range raw -32768..32767, unit=mV, transfer-property=PENDING
        frame VcuAdcTxG1Msg1_oTC37X_VCU_CAN01: id 0x105, from VCU, frame-length=8, can-addressing-mode=STANDARD
          pdu VcuAdcTxG1Msg1_oTC37X_VCU_CAN01: length=8, minimum-delay=0, transmission-mode-false-timing=cyclic-timing={time-offset=0, time-period=0.5}, transmission-mode-true-timing=cyclic-timing={time-offset=0, time-period=0.5}, unused-bit-pattern=0
            signal AN12_oVcuAdcTxG1Msg1_oTC37X_VCU_CAN01: start 0, 16 bit, little-endian, i-signal-type=PRIMITIVE, init-value=0, base-type=sint16, compu {identical}, range raw -32768..32767, unit=mV, transfer-property=PENDING
            signal AN13_oVcuAdcTxG1Msg1_oTC37X_VCU_CAN01: start 16, 16 bit, little-endian, i-signal-type=PRIMITIVE, init-value=0, base-type=sint16, compu {identical}, range raw -32768..32767, unit=mV, transfer-property=PENDING
            signal AN14_oVcuAdcTxG1Msg1_oTC37X_VCU_CAN01: start 32, 16 bit, little-endian, i-signal-type=PRIMITIVE, init-value=0, base-type=sint16, compu {identical}, range raw -32768..32767, unit=mV, transfer-property=PENDING
            signal AN15_oVcuAdcTxG1Msg1_oTC37X_VCU_CAN01: start 48, 16 bit, little-endian, i-signal-type=PRIMITIVE, init-value=0, base-type=sint16, compu {identical}, range raw -32768..32767, unit=mV, transfer-property=PENDING
        frame VcuAdcTxG2Msg0_oTC37X_VCU_CAN01: id 0x106, from VCU, frame-length=8, can-addressing-mode=STANDARD
          pdu VcuAdcTxG2Msg0_oTC37X_VCU_CAN01: length=8, minimum-delay=0, transmission-mode-false-timing=cyclic-timing={time-offset=0, time-period=0.5}, transmission-mode-true-timing=cyclic-timing={time-offset=0, time-period=0.5}, unused-bit-pattern=0
            signal AN16_oVcuAdcTxG2Msg0_oTC37X_VCU_CAN01: start 0, 16 bit, little-endian, i-signal-type=PRIMITIVE, init-value=0, base-type=sint16, compu {identical}, range raw -32768..32767, unit=mV, transfer-property=PENDING
            signal AN17_oVcuAdcTxG2Msg0_oTC37X_VCU_CAN01: start 16, 16 bit, little-endian, i-signal-type=PRIMITIVE, init-value=0, base-type=sint16, compu {identical}, range raw -32768..32767, unit=mV, transfer-property=PENDING
            signal AN18_oVcuAdcTxG2Msg0_oTC37X_VCU_CAN01: start 32, 16 bit, little-endian, i-signal-type=PRIMITIVE, init-value=0, base-type=sint16, compu {identical}, range raw -32768..32767, unit=mV, transfer-property=PENDING
            signal AN19_oVcuAdcTxG2Msg0_oTC37X_VCU_CAN01: start 48, 16 bit, little-endian, i-signal-type=PRIMITIVE, init-value=0, base-type=sint16, compu {identical}, range raw -32768..32767, unit=mV, transfer-property=PENDING
        frame VcuAdcTxG2Msg1_oTC37X_VCU_CAN01: id 0x107, from VCU, frame-length=8, can-addressing-mode=STANDARD
          pdu VcuAdcTxG2Msg1_oTC37X_VCU_CAN01: length=8, minimum-delay=0, transmission-mode-false-timing=cyclic-timing={time-offset=0, time-period=0.5}, transmission-mode-true-timing=cyclic-timing={time-offset=0, time-period=0.5}, unused-bit-pattern=0
            signal AN20_oVcuAdcTxG2Msg1_oTC37X_VCU_CAN01: start 0, 16 bit, little-endian, i-signal-type=PRIMITIVE, init-value=0, base-type=sint16, compu {identical}, range raw -32768..32767, unit=mV, transfer-property=PENDING
            signal AN21_oVcuAdcTxG2Msg1_oTC37X_VCU_CAN01: start 16, 16 bit, little-endian, i-signal-type=PRIMITIVE, init-value=0, base-type=sint16, compu {identical}, range raw -32768..32767, unit=mV, transfer-property=PENDING
            signal AN22_oVcuAdcTxG2Msg1_oTC37X_VCU_CAN01: start 32, 16 bit, little-endian, i-signal-type=PRIMITIVE, init-value=0, base-type=sint16, compu {identical}, range raw -32768..32767, unit=mV, transfer-property=PENDING
            signal AN23_oVcuAdcTxG2Msg1_oTC37X_VCU_CAN01: start 48, 16 bit, little-endian, i-signal-type=PRIMITIVE, init-value=0, base-type=sint16, compu {identical}, range raw -32768..32767, unit=mV, transfer-property=PENDING
        frame VcuAdcTxG3Msg0_oTC37X_VCU_CAN01: id 0x108, from VCU, frame-length=8, can-addressing-mode=STANDARD
          pdu VcuAdcTxG3Msg0_oTC37X_VCU_CAN01: length=8, minimum-delay=0, transmission-mode-false-timing=cyclic-timing={time-offset=0, time-period=0.5}, transmission-mode-true-timing=cyclic-timing={time-offset=0, time-period=0.5}, unused-bit-pattern=0
            signal AN24_oVcuAdcTxG3Msg0_oTC37X_VCU_CAN01: start 0, 16 bit, little-endian, i-signal-type=PRIMITIVE, init-value=0, base-type=sint16, compu {identical}, range raw -32768..32767, unit=mV, transfer-property=PENDING
            signal AN25_oVcuAdcTxG3Msg0_oTC37X_VCU_CAN01: start 16, 16 bit, little-endian, i-signal-type=PRIMITIVE, init-value=0, base-type=sint16, compu {identical}, range raw -32768..32767, unit=mV, transfer-property=PENDING
            signal AN26_oVcuAdcTxG3Msg0_oTC37X_VCU_CAN01: start 32, 16 bit, little-endian, i-signal-type=PRIMITIVE, init-value=0, base-type=sint16, compu {identical}, range raw -32768..32767, unit=mV, transfer-property=PENDING
            signal AN27_oVcuAdcTxG3Msg0_oTC37X_VCU_CAN01: start 48, 16 bit, little-endian, i-signal-type=PRIMITIVE, init-value=0, base-type=sint16, compu {identical}, range raw -32768..32767, unit=mV, transfer-property=PENDING
        frame VcuAdcTxG3Msg1_oTC37X_VCU_CAN01: id 0x109, from VCU, frame-length=8, can-addressing-mode=STANDARD
          pdu VcuAdcTxG3Msg1_oTC37X_VCU_CAN01: length=8, minimum-delay=0, transmission-mode-false-timing=cyclic-timing={time-offset=0, time-period=0.5}, transmission-mode-true-timing=cyclic-timing={time-offset=0, time-period=0.5}, unused-bit-pattern=0
            signal AN28_oVcuAdcTxG3Msg1_oTC37X_VCU_CAN01: start 0, 16 bit, little-endian, i-signal-type=PRIMITIVE, init-value=0, base-type=sint16, compu {identical}, range raw -32768..32767, unit=mV, transfer-property=PENDING
            signal AN29_oVcuAdcTxG3Msg1_oTC37X_VCU_CAN01: start 16, 16 bit, little-endian, i-signal-type=PRIMITIVE, init-value=0, base-type=sint16, compu {identical}, range raw -32768..32767, unit=mV, transfer-property=PENDING
            signal AN30_oVcuAdcTxG3Msg1_oTC37X_VCU_CAN01: start 32, 16 bit, little-endian, i-signal-type=PRIMITIVE, init-value=0, base-type=sint16, compu {identical}, range raw -32768..32767, unit=mV, transfer-property=PENDING
            signal AN31_oVcuAdcTxG3Msg1_oTC37X_VCU_CAN01: start 48, 16 bit, little-endian, i-signal-type=PRIMITIVE, init-value=0, base-type=sint16, compu {identical}, range raw -32768..32767, unit=mV, transfer-property=PENDING
        frame VcuAdcTxG8Msg0_oTC37X_VCU_CAN01: id 0x10A, from VCU, frame-length=8, can-addressing-mode=STANDARD
          pdu VcuAdcTxG8Msg0_oTC37X_VCU_CAN01: length=8, minimum-delay=0, transmission-mode-false-timing=cyclic-timing={time-offset=0, time-period=0.5}, transmission-mode-true-timing=cyclic-timing={time-offset=0, time-period=0.5}, unused-bit-pattern=0
            signal AN32_oVcuAdcTxG8Msg0_oTC37X_VCU_CAN01: start 0, 16 bit, little-endian, i-signal-type=PRIMITIVE, init-value=0, base-type=sint16, compu {identical}, range raw -32768..32767, unit=mV, transfer-property=PENDING
            signal AN33_oVcuAdcTxG8Msg0_oTC37X_VCU_CAN01: start 16, 16 bit, little-endian, i-signal-type=PRIMITIVE, init-value=0, base-type=sint16, compu {identical}, range raw -32768..32767, unit=mV, transfer-property=PENDING
            signal AN34_oVcuAdcTxG8Msg0_oTC37X_VCU_CAN01: start 32, 16 bit, little-endian, i-signal-type=PRIMITIVE, init-value=0, base-type=sint16, compu {identical}, range raw -32768..32767, unit=mV, transfer-property=PENDING
            signal AN35_oVcuAdcTxG8Msg0_oTC37X_VCU_CAN01: start 48, 16 bit, little-endian, i-signal-type=PRIMITIVE, init-value=0, base-type=sint16, compu {identical}, range raw -32768..32767, unit=mV, transfer-property=PENDING
        frame VcuAdcTxG8Msg1_oTC37X_VCU_CAN01: id 0x10B, from VCU, frame-length=8, can-addressing-mode=STANDARD
          pdu VcuAdcTxG8Msg1_oTC37X_VCU_CAN01: length=8, minimum-delay=0, transmission-mode-false-timing=cyclic-timing={time-offset=0, time-period=0.5}, transmission-mode-true-timing=cyclic-timing={time-offset=0, time-period=0.5}, unused-bit-pattern=0
            signal AN36_oVcuAdcTxG8Msg1_oTC37X_VCU_CAN01: start 0, 16 bit, little-endian, i-signal-type=PRIMITIVE, init-value=0, base-type=sint16, compu {identical}, range raw -32768..32767, unit=mV, transfer-property=PENDING
            signal AN37_oVcuAdcTxG8Msg1_oTC37X_VCU_CAN01: start 16, 16 bit, little-endian, i-signal-type=PRIMITIVE, init-value=0, base-type=sint16, compu {identical}, range raw -32768..32767, unit=mV, transfer-property=PENDING
            signal AN38_oVcuAdcTxG8Msg1_oTC37X_VCU_CAN01: start 32, 16 bit, little-endian, i-signal-type=PRIMITIVE, init-value=0, base-type=sint16, compu {identical}, range raw -32768..32767, unit=mV, transfer-property=PENDING
            signal AN39_oVcuAdcTxG8Msg1_oTC37X_VCU_CAN01: start 48, 16 bit, little-endian, i-signal-type=PRIMITIVE, init-value=0, base-type=sint16, compu {identical}, range raw -32768..32767, unit=mV, transfer-property=PENDING
        frame VcuAdcTxG8Msg2_oTC37X_VCU_CAN01: id 0x10C, from VCU, frame-length=8, can-addressing-mode=STANDARD
          pdu VcuAdcTxG8Msg2_oTC37X_VCU_CAN01: length=8, minimum-delay=0, transmission-mode-false-timing=cyclic-timing={time-offset=0, time-period=0.5}, transmission-mode-true-timing=cyclic-timing={time-offset=0, time-period=0.5}, unused-bit-pattern=0
            signal AN40_oVcuAdcTxG8Msg2_oTC37X_VCU_CAN01: start 0, 16 bit, little-endian, i-signal-type=PRIMITIVE, init-value=0, base-type=sint16, compu {identical}, range raw -32768..32767, unit=mV, transfer-property=PENDING
            signal AN41_oVcuAdcTxG8Msg2_oTC37X_VCU_CAN01: start 16, 16 bit, little-endian, i-signal-type=PRIMITIVE, init-value=0, base-type=sint16, compu {identical}, range raw -32768..32767, unit=mV, transfer-property=PENDING
            signal AN42_oVcuAdcTxG8Msg2_oTC37X_VCU_CAN01: start 32, 16 bit, little-endian, i-signal-type=PRIMITIVE, init-value=0, base-type=sint16, compu {identical}, range raw -32768..32767, unit=mV, transfer-property=PENDING
            signal AN43_oVcuAdcTxG8Msg2_oTC37X_VCU_CAN01: start 48, 16 bit, little-endian, i-signal-type=PRIMITIVE, init-value=0, base-type=sint16, compu {identical}, range raw -32768..32767, unit=mV, transfer-property=PENDING
        frame VcuAdcTxG8Msg3_oTC37X_VCU_CAN01: id 0x10D, from VCU, frame-length=8, can-addressing-mode=STANDARD
          pdu VcuAdcTxG8Msg3_oTC37X_VCU_CAN01: length=8, minimum-delay=0, transmission-mode-false-timing=cyclic-timing={time-offset=0, time-period=0.5}, transmission-mode-true-timing=cyclic-timing={time-offset=0, time-period=0.5}, unused-bit-pattern=0
            signal AN44_oVcuAdcTxG8Msg3_oTC37X_VCU_CAN01: start 0, 16 bit, little-endian, i-signal-type=PRIMITIVE, init-value=0, base-type=sint16, compu {identical}, range raw -32768..32767, unit=mV, transfer-property=PENDING
            signal AN45_oVcuAdcTxG8Msg3_oTC37X_VCU_CAN01: start 16, 16 bit, little-endian, i-signal-type=PRIMITIVE, init-value=0, base-type=sint16, compu {identical}, range raw -32768..32767, unit=mV, transfer-property=PENDING
            signal AN46_oVcuAdcTxG8Msg3_oTC37X_VCU_CAN01: start 32, 16 bit, little-endian, i-signal-type=PRIMITIVE, init-value=0, base-type=sint16, compu {identical}, range raw -32768..32767, unit=mV, transfer-property=PENDING
            signal AN47_oVcuAdcTxG8Msg3_oTC37X_VCU_CAN01: start 48, 16 bit, little-endian, i-signal-type=PRIMITIVE, init-value=0, base-type=sint16, compu {identical}, range raw -32768..32767, unit=mV, transfer-property=PENDING
        frame VcuRxMsg3_oTC37X_VCU_CAN01: id 0x202, to VCU, frame-length=8, can-addressing-mode=STANDARD
          pdu VcuRxMsg3_oTC37X_VCU_CAN01: length=8, minimum-delay=0, transmission-mode-false-timing=cyclic-timing={time-offset=0, time-period=0.5}, transmission-mode-true-timing=cyclic-timing={time-offset=0, time-period=0.5}, unused-bit-pattern=0
            signal VcuRxMsg3_Sig0_oVcuRxMsg3_oTC37X_VCU_CAN01: start 0, 16 bit, little-endian, i-signal-type=PRIMITIVE, init-value=0, base-type=sint16, compu {identical}, range raw -32768..32767, transfer-property=PENDING, to VCU
            signal VcuRxMsg3_Sig1_oVcuRxMsg3_oTC37X_VCU_CAN01: start 16, 16 bit, little-endian, i-signal-type=PRIMITIVE, init-value=0, base-type=sint16, compu {identical}, range raw -32768..32767, transfer-property=PENDING, to VCU
            signal VcuRxMsg3_Sig2_oVcuRxMsg3_oTC37X_VCU_CAN01: start 32, 16 bit, little-endian, i-signal-type=PRIMITIVE, init-value=0, base-type=sint16, compu {identical}, range raw -32768..32767, transfer-property=PENDING, to VCU
            signal VcuRxMsg3_Sig3_oVcuRxMsg3_oTC37X_VCU_CAN01: start 48, 16 bit, little-endian, i-signal-type=PRIMITIVE, init-value=0, base-type=sint16, compu {identical}, range raw -32768..32767, transfer-property=PENDING, to VCU
        frame VcuRxMsg4_oTC37X_VCU_CAN01: id 0x203, to VCU, frame-length=8, can-addressing-mode=STANDARD
          pdu VcuRxMsg4_oTC37X_VCU_CAN01: length=8, minimum-delay=0, transmission-mode-false-timing=cyclic-timing={time-offset=0, time-period=0.5}, transmission-mode-true-timing=cyclic-timing={time-offset=0, time-period=0.5}, unused-bit-pattern=0
            signal VcuRxMsg4_Sig0_oVcuRxMsg4_oTC37X_VCU_CAN01: start 0, 16 bit, little-endian, i-signal-type=PRIMITIVE, init-value=0, base-type=sint16, compu {identical}, range raw -32768..32767, transfer-property=PENDING, to VCU
            signal VcuRxMsg4_Sig1_oVcuRxMsg4_oTC37X_VCU_CAN01: start 16, 16 bit, little-endian, i-signal-type=PRIMITIVE, init-value=0, base-type=sint16, compu {identical}, range raw -32768..32767, transfer-property=PENDING, to VCU
            signal VcuRxMsg4_Sig2_oVcuRxMsg4_oTC37X_VCU_CAN01: start 32, 16 bit, little-endian, i-signal-type=PRIMITIVE, init-value=0, base-type=sint16, compu {identical}, range raw -32768..32767, transfer-property=PENDING, to VCU
            signal VcuRxMsg4_Sig3_oVcuRxMsg4_oTC37X_VCU_CAN01: start 48, 16 bit, little-endian, i-signal-type=PRIMITIVE, init-value=0, base-type=sint16, compu {identical}, range raw -32768..32767, transfer-property=PENDING, to VCU
    TC37X_VCU_CAN03: baudrate=500000  # VCU_CAN03
      can physical channel CHNL: comm-connectors=CN_TC37X_VCU_CAN03
        frame VCU_Rx_500h_NM_oTC37X_VCU_CAN03: id 0x500, to VCU, frame-length=8, can-addressing-mode=STANDARD
          nm pdu VCU_Rx_500h_NM_oTC37X_VCU_CAN03: length=8, unused-bit-pattern=0
        frame VCU_Tx_51Ch_NM_oTC37X_VCU_CAN03: id 0x51C, from VCU, frame-length=8, can-addressing-mode=STANDARD
          nm pdu VCU_Tx_51Ch_NM_oTC37X_VCU_CAN03: length=8, unused-bit-pattern=0
        frame VcuCan03RxMsg1_oTC37X_VCU_CAN03: id 0x212, to VCU, frame-length=8, can-addressing-mode=STANDARD
          pdu VcuCan03RxMsg1_oTC37X_VCU_CAN03: length=8, minimum-delay=0, transmission-mode-false-timing=cyclic-timing={time-offset=0, time-period=0.5}, transmission-mode-true-timing=cyclic-timing={time-offset=0, time-period=0.5}, unused-bit-pattern=0
            signal VcuRxMsg3_Sig0_oVcuCan03RxMsg1_oTC37X_VCU_CAN03: start 0, 16 bit, little-endian, i-signal-type=PRIMITIVE, init-value=0, base-type=sint16, compu {identical}, range raw -32768..32767, transfer-property=PENDING, to VCU
            signal VcuRxMsg3_Sig1_oVcuCan03RxMsg1_oTC37X_VCU_CAN03: start 16, 16 bit, little-endian, i-signal-type=PRIMITIVE, init-value=0, base-type=sint16, compu {identical}, range raw -32768..32767, transfer-property=PENDING, to VCU
            signal VcuRxMsg3_Sig2_oVcuCan03RxMsg1_oTC37X_VCU_CAN03: start 32, 16 bit, little-endian, i-signal-type=PRIMITIVE, init-value=0, base-type=sint16, compu {identical}, range raw -32768..32767, transfer-property=PENDING, to VCU
            signal VcuRxMsg3_Sig3_oVcuCan03RxMsg1_oTC37X_VCU_CAN03: start 48, 16 bit, little-endian, i-signal-type=PRIMITIVE, init-value=0, base-type=sint16, compu {identical}, range raw -32768..32767, transfer-property=PENDING, to VCU
        frame VcuCan03RxMsg2_oTC37X_VCU_CAN03: id 0x213, to VCU, frame-length=8, can-addressing-mode=STANDARD
          pdu VcuCan03RxMsg2_oTC37X_VCU_CAN03: length=8, minimum-delay=0, transmission-mode-false-timing=cyclic-timing={time-offset=0, time-period=0.5}, transmission-mode-true-timing=cyclic-timing={time-offset=0, time-period=0.5}, unused-bit-pattern=0
            signal VcuRxMsg4_Sig0_oVcuCan03RxMsg2_oTC37X_VCU_CAN03: start 0, 16 bit, little-endian, i-signal-type=PRIMITIVE, init-value=0, base-type=sint16, compu {identical}, range raw -32768..32767, transfer-property=PENDING, to VCU
            signal VcuRxMsg4_Sig1_oVcuCan03RxMsg2_oTC37X_VCU_CAN03: start 16, 16 bit, little-endian, i-signal-type=PRIMITIVE, init-value=0, base-type=sint16, compu {identical}, range raw -32768..32767, transfer-property=PENDING, to VCU
            signal VcuRxMsg4_Sig2_oVcuCan03RxMsg2_oTC37X_VCU_CAN03: start 32, 16 bit, little-endian, i-signal-type=PRIMITIVE, init-value=0, base-type=sint16, compu {identical}, range raw -32768..32767, transfer-property=PENDING, to VCU
            signal VcuRxMsg4_Sig3_oVcuCan03RxMsg2_oTC37X_VCU_CAN03: start 48, 16 bit, little-endian, i-signal-type=PRIMITIVE, init-value=0, base-type=sint16, compu {identical}, range raw -32768..32767, transfer-property=PENDING, to VCU
        frame VcuCan03TxMsg1_oTC37X_VCU_CAN03: id 0x112, from VCU, frame-length=8, can-addressing-mode=STANDARD
          pdu VcuCan03TxMsg1_oTC37X_VCU_CAN03: length=8, minimum-delay=0, transmission-mode-false-timing=cyclic-timing={time-offset=0, time-period=0.5}, transmission-mode-true-timing=cyclic-timing={time-offset=0, time-period=0.5}, unused-bit-pattern=0
            signal VcuAdcTxMsg1_Sig0_oVcuCan03TxMsg1_oTC37X_VCU_CAN03: start 0, 16 bit, little-endian, i-signal-type=PRIMITIVE, init-value=0, base-type=sint16, compu {identical}, range raw -32768..32767, transfer-property=PENDING
            signal VcuAdcTxMsg1_Sig1_oVcuCan03TxMsg1_oTC37X_VCU_CAN03: start 16, 16 bit, little-endian, i-signal-type=PRIMITIVE, init-value=0, base-type=sint16, compu {identical}, range raw -32768..32767, transfer-property=PENDING
            signal VcuAdcTxMsg1_Sig2_oVcuCan03TxMsg1_oTC37X_VCU_CAN03: start 32, 16 bit, little-endian, i-signal-type=PRIMITIVE, init-value=0, base-type=sint16, compu {identical}, range raw -32768..32767, transfer-property=PENDING
            signal VcuAdcTxMsg1_Sig3_oVcuCan03TxMsg1_oTC37X_VCU_CAN03: start 48, 16 bit, little-endian, i-signal-type=PRIMITIVE, init-value=0, base-type=sint16, compu {identical}, range raw -32768..32767, transfer-property=PENDING
        frame VcuCan03TxMsg2_oTC37X_VCU_CAN03: id 0x113, from VCU, frame-length=8, can-addressing-mode=STANDARD
          pdu VcuCan03TxMsg2_oTC37X_VCU_CAN03: length=8, minimum-delay=0, transmission-mode-false-timing=cyclic-timing={time-offset=0, time-period=0.5}, transmission-mode-true-timing=cyclic-timing={time-offset=0, time-period=0.5}, unused-bit-pattern=0
            signal VcuAdcTxMsg2_Sig0_oVcuCan03TxMsg2_oTC37X_VCU_CAN03: start 0, 16 bit, little-endian, i-signal-type=PRIMITIVE, init-value=0, base-type=sint16, compu {identical}, range raw -32768..32767, transfer-property=PENDING
            signal VcuAdcTxMsg2_Sig1_oVcuCan03TxMsg2_oTC37X_VCU_CAN03: start 16, 16 bit, little-endian, i-signal-type=PRIMITIVE, init-value=0, base-type=sint16, compu {identical}, range raw -32768..32767, transfer-property=PENDING
            signal VcuAdcTxMsg2_Sig2_oVcuCan03TxMsg2_oTC37X_VCU_CAN03: start 32, 16 bit, little-endian, i-signal-type=PRIMITIVE, init-value=0, base-type=sint16, compu {identical}, range raw -32768..32767, transfer-property=PENDING
            signal VcuAdcTxMsg2_Sig3_oVcuCan03TxMsg2_oTC37X_VCU_CAN03: start 48, 16 bit, little-endian, i-signal-type=PRIMITIVE, init-value=0, base-type=sint16, compu {identical}, range raw -32768..32767, transfer-property=PENDING
    TC37X_VCU_CAN12: baudrate=500000  # VCU_CAN12
      can physical channel CHNL: comm-connectors=CN_TC37X_VCU_CAN12
        frame VCU_Rx_500h_NM_oTC37X_VCU_CAN12: id 0x500, to VCU, frame-length=8, can-addressing-mode=STANDARD
          nm pdu VCU_Rx_500h_NM_oTC37X_VCU_CAN12: length=8, unused-bit-pattern=0
        frame VCU_Tx_51Ch_NM_oTC37X_VCU_CAN12: id 0x51C, from VCU, frame-length=8, can-addressing-mode=STANDARD
          nm pdu VCU_Tx_51Ch_NM_oTC37X_VCU_CAN12: length=8, unused-bit-pattern=0
        frame VcuCan12RxMsg3_oTC37X_VCU_CAN12: id 0x33, to VCU, frame-length=8, can-addressing-mode=STANDARD
          pdu VcuCan12RxMsg3_oTC37X_VCU_CAN12: length=8, minimum-delay=0, transmission-mode-false-timing=cyclic-timing={time-offset=0, time-period=0.5}, transmission-mode-true-timing=cyclic-timing={time-offset=0, time-period=0.5}, unused-bit-pattern=0
            signal VcuCan12RxMsg3_Sig0_oVcuCan12RxMsg3_oTC37X_VCU_CAN12: start 0, 16 bit, little-endian, i-signal-type=PRIMITIVE, init-value=0, base-type=sint16, compu {identical}, range raw -32768..32767, transfer-property=PENDING, to VCU
            signal VcuCan12RxMsg3_Sig1_oVcuCan12RxMsg3_oTC37X_VCU_CAN12: start 16, 16 bit, little-endian, i-signal-type=PRIMITIVE, init-value=0, base-type=sint16, compu {identical}, range raw -32768..32767, transfer-property=PENDING, to VCU
            signal VcuCan12RxMsg3_Sig2_oVcuCan12RxMsg3_oTC37X_VCU_CAN12: start 32, 16 bit, little-endian, i-signal-type=PRIMITIVE, init-value=0, base-type=sint16, compu {identical}, range raw -32768..32767, transfer-property=PENDING, to VCU
            signal VcuCan12RxMsg3_Sig3_oVcuCan12RxMsg3_oTC37X_VCU_CAN12: start 48, 16 bit, little-endian, i-signal-type=PRIMITIVE, init-value=0, base-type=sint16, compu {identical}, range raw -32768..32767, transfer-property=PENDING, to VCU
        frame VcuCan12RxMsg4_oTC37X_VCU_CAN12: id 0x32, to VCU, frame-length=8, can-addressing-mode=STANDARD
          pdu VcuCan12RxMsg4_oTC37X_VCU_CAN12: length=8, minimum-delay=0, transmission-mode-false-timing=cyclic-timing={time-offset=0, time-period=0.5}, transmission-mode-true-timing=cyclic-timing={time-offset=0, time-period=0.5}, unused-bit-pattern=0
            signal VcuCan12RxMsg4_Sig0_oVcuCan12RxMsg4_oTC37X_VCU_CAN12: start 0, 16 bit, little-endian, i-signal-type=PRIMITIVE, init-value=0, base-type=sint16, compu {identical}, range raw -32768..32767, transfer-property=PENDING, to VCU
            signal VcuCan12RxMsg4_Sig1_oVcuCan12RxMsg4_oTC37X_VCU_CAN12: start 16, 16 bit, little-endian, i-signal-type=PRIMITIVE, init-value=0, base-type=sint16, compu {identical}, range raw -32768..32767, transfer-property=PENDING, to VCU
            signal VcuCan12RxMsg4_Sig2_oVcuCan12RxMsg4_oTC37X_VCU_CAN12: start 32, 16 bit, little-endian, i-signal-type=PRIMITIVE, init-value=0, base-type=sint16, compu {identical}, range raw -32768..32767, transfer-property=PENDING, to VCU
            signal VcuCan12RxMsg4_Sig3_oVcuCan12RxMsg4_oTC37X_VCU_CAN12: start 48, 16 bit, little-endian, i-signal-type=PRIMITIVE, init-value=0, base-type=sint16, compu {identical}, range raw -32768..32767, transfer-property=PENDING, to VCU
        frame VcuCan12TxMsg1_oTC37X_VCU_CAN12: id 0x35, from VCU, frame-length=8, can-addressing-mode=STANDARD
          pdu VcuCan12TxMsg1_oTC37X_VCU_CAN12: length=8, minimum-delay=0, transmission-mode-false-timing=cyclic-timing={time-offset=0, time-period=0.5}, transmission-mode-true-timing=cyclic-timing={time-offset=0, time-period=0.5}, unused-bit-pattern=0
            signal VcuCan12TxMsg1_Sig0_oVcuCan12TxMsg1_oTC37X_VCU_CAN12: start 0, 16 bit, little-endian, i-signal-type=PRIMITIVE, init-value=0, base-type=sint16, compu {identical}, range raw -32768..32767, transfer-property=PENDING
            signal VcuCan12TxMsg1_Sig1_oVcuCan12TxMsg1_oTC37X_VCU_CAN12: start 16, 16 bit, little-endian, i-signal-type=PRIMITIVE, init-value=0, base-type=sint16, compu {identical}, range raw -32768..32767, transfer-property=PENDING
            signal VcuCan12TxMsg1_Sig2_oVcuCan12TxMsg1_oTC37X_VCU_CAN12: start 32, 16 bit, little-endian, i-signal-type=PRIMITIVE, init-value=0, base-type=sint16, compu {identical}, range raw -32768..32767, transfer-property=PENDING
            signal VcuCan12TxMsg1_Sig3_oVcuCan12TxMsg1_oTC37X_VCU_CAN12: start 48, 16 bit, little-endian, i-signal-type=PRIMITIVE, init-value=0, base-type=sint16, compu {identical}, range raw -32768..32767, transfer-property=PENDING
        frame VcuCan12TxMsg2_oTC37X_VCU_CAN12: id 0x34, from VCU, frame-length=8, can-addressing-mode=STANDARD
          pdu VcuCan12TxMsg2_oTC37X_VCU_CAN12: length=8, minimum-delay=0, transmission-mode-false-timing=cyclic-timing={time-offset=0, time-period=0.5}, transmission-mode-true-timing=cyclic-timing={time-offset=0, time-period=0.5}, unused-bit-pattern=0
            signal VcuCan12TxMsg2_Sig0_oVcuCan12TxMsg2_oTC37X_VCU_CAN12: start 0, 16 bit, little-endian, i-signal-type=PRIMITIVE, init-value=0, base-type=sint16, compu {identical}, range raw -32768..32767, transfer-property=PENDING
            signal VcuCan12TxMsg2_Sig1_oVcuCan12TxMsg2_oTC37X_VCU_CAN12: start 16, 16 bit, little-endian, i-signal-type=PRIMITIVE, init-value=0, base-type=sint16, compu {identical}, range raw -32768..32767, transfer-property=PENDING
            signal VcuCan12TxMsg2_Sig2_oVcuCan12TxMsg2_oTC37X_VCU_CAN12: start 32, 16 bit, little-endian, i-signal-type=PRIMITIVE, init-value=0, base-type=sint16, compu {identical}, range raw -32768..32767, transfer-property=PENDING
            signal VcuCan12TxMsg2_Sig3_oVcuCan12TxMsg2_oTC37X_VCU_CAN12: start 48, 16 bit, little-endian, i-signal-type=PRIMITIVE, init-value=0, base-type=sint16, compu {identical}, range raw -32768..32767, transfer-property=PENDING
  lin cluster LIN00: baudrate=19200, protocol-name=LIN, protocol-version=LIN21  # /*************************************************************************************/ // // Description: // Created: // Author: // Version: // Vehicle Project: // /*************************************************************************************/
    lin physical channel CHNL: comm-connectors=CN_LIN00
      frame EDCU_EXV2_oLIN00: id 0x22, from VCU, frame-length=8, lin-checksum=ENHANCED
        pdu EDCU_EXV2_oLIN00: length=8, unused-bit-pattern=255
          signal EDCU_EXV2_Cmd_Set_Rq_oEDCU_EXV2_oLIN00: start 0, 16 bit, little-endian, i-signal-type=PRIMITIVE, init-value=0, base-type=uint16, compu {identical}, range raw 0..576
          signal EDCU_EXV2_Cmd_Move_Enbl_oEDCU_EXV2_oLIN00: start 16, 1 bit, little-endian, i-signal-type=PRIMITIVE, init-value=0, base-type=boolean, compu {0=Cx0_DSABL, 1=Cx1_ENBL}, range raw 0..1
          signal EDCU_EXV2_Cmd_Init_Rq_oEDCU_EXV2_oLIN00: start 24, 3 bit, little-endian, i-signal-type=PRIMITIVE, init-value=0, base-type=uint8, compu {0=Cx0_NO_RQ, 1=Cx1_START_INIT_SQC, 2=Cx2_WAIT_SQC_FINISH}, range raw 0..7
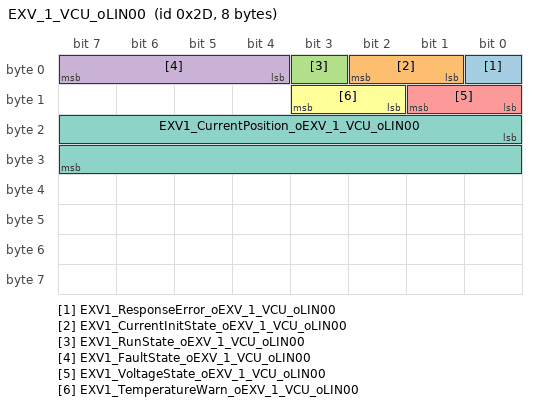
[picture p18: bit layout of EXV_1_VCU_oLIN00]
      frame EXV_1_VCU_oLIN00: id 0x2D, to VCU, frame-length=8, lin-checksum=ENHANCED
        pdu EXV_1_VCU_oLIN00: length=8, unused-bit-pattern=255
          signal EXV1_ResponseError_oEXV_1_VCU_oLIN00: start 0, 1 bit, little-endian, i-signal-type=PRIMITIVE, init-value=0, base-type=boolean, compu {0=Cx0_No_Comm_Error (No Comm Error), 1=Cx1_Comm_Error_Active (Comm Error Active)}, range raw 0..1, to VCU
          signal EXV1_CurrentInitState_oEXV_1_VCU_oLIN00: start 1, 2 bit, little-endian, i-signal-type=PRIMITIVE, init-value=0, base-type=uint8, compu {0=Cx0_NO_INIT, 1=Cx1_INIT_IN_PROCESS, 2=Cx2_Initialized}, range raw 0..3, to VCU
          signal EXV1_RunState_oEXV_1_VCU_oLIN00: start 3, 1 bit, little-endian, i-signal-type=PRIMITIVE, init-value=0, base-type=boolean, compu {0=Cx0_NO_MOVEMENT, 1=Cx1_ACT_MOVING}, range raw 0..1, to VCU
          signal EXV1_FaultState_oEXV_1_VCU_oLIN00: start 4, 4 bit, little-endian, i-signal-type=PRIMITIVE, init-value=0, base-type=uint8, compu {0=Cx0_No_Fault (No Fault), 1=Cx1_COIL_SHRT, 2=Cx2_COIL_OPN, 3=Cx3_Over_temp_shut_down (Over temp shut down), 4=Cx4_Reserved}, range raw 0..4, to VCU
          signal EXV1_VoltageState_oEXV_1_VCU_oLIN00: start 8, 2 bit, little-endian, i-signal-type=PRIMITIVE, init-value=0, base-type=uint8, compu {0=Cx0_Voltage_Range_OK_ (Voltage Range OK), 1=Cx1_Over_Voltage_ (Over Voltage), 2=Cx2_Under_Voltage (Under Voltage)}, range raw 0..2, to VCU
          signal EXV1_TemperatureWarn_oEXV_1_VCU_oLIN00: start 10, 2 bit, little-endian, i-signal-type=PRIMITIVE, init-value=0, base-type=uint8, compu {0=Cx0_OK_, 1=Cx1_WARNING}, range raw 0..1, to VCU
          signal EXV1_CurrentPosition_oEXV_1_VCU_oLIN00: start 16, 16 bit, little-endian, i-signal-type=PRIMITIVE, init-value=0, base-type=uint16, compu {identical}, range raw 0..500, to VCU
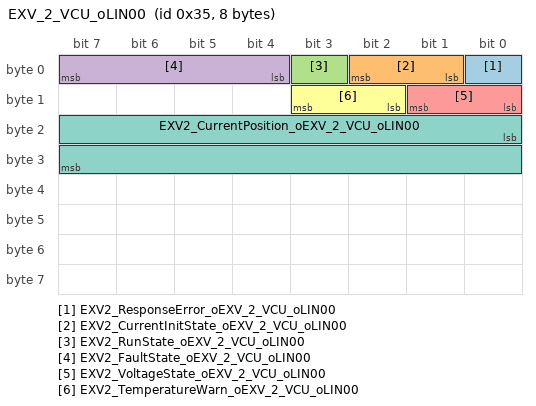
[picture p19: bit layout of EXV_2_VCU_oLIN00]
      frame EXV_2_VCU_oLIN00: id 0x35, to VCU, frame-length=8, lin-checksum=ENHANCED
        pdu EXV_2_VCU_oLIN00: length=8, unused-bit-pattern=255
          signal EXV2_ResponseError_oEXV_2_VCU_oLIN00: start 0, 1 bit, little-endian, i-signal-type=PRIMITIVE, init-value=0, base-type=boolean, compu {0=Cx0_No_Comm_Error (No Comm Error), 1=Cx1_Comm_Error_Active (Comm Error Active)}, range raw 0..1, to VCU
          signal EXV2_CurrentInitState_oEXV_2_VCU_oLIN00: start 1, 2 bit, little-endian, i-signal-type=PRIMITIVE, init-value=0, base-type=uint8, compu {0=Cx0_NO_INIT, 1=Cx1_INIT_IN_PROCESS, 2=Cx2_Initialized}, range raw 0..3, to VCU
          signal EXV2_RunState_oEXV_2_VCU_oLIN00: start 3, 1 bit, little-endian, i-signal-type=PRIMITIVE, init-value=0, base-type=boolean, compu {0=Cx0_NO_MOVEMENT, 1=Cx1_ACT_MOVING}, range raw 0..1, to VCU
          signal EXV2_FaultState_oEXV_2_VCU_oLIN00: start 4, 4 bit, little-endian, i-signal-type=PRIMITIVE, init-value=0, base-type=uint8, compu {0=Cx0_No_Fault (No Fault), 1=Cx1_COIL_SHRT, 2=Cx2_COIL_OPN, 3=Cx3_Over_temp_shut_down (Over temp shut down), 4=Cx4_Reserved}, range raw 0..4, to VCU
          signal EXV2_VoltageState_oEXV_2_VCU_oLIN00: start 8, 2 bit, little-endian, i-signal-type=PRIMITIVE, init-value=0, base-type=uint8, compu {0=Cx0_Voltage_Range_OK_ (Voltage Range OK), 1=Cx1_Over_Voltage_ (Over Voltage), 2=Cx2_Under_Voltage (Under Voltage)}, range raw 0..2, to VCU
          signal EXV2_TemperatureWarn_oEXV_2_VCU_oLIN00: start 10, 2 bit, little-endian, i-signal-type=PRIMITIVE, init-value=0, base-type=uint8, compu {0=Cx0_OK_, 1=Cx1_WARNING}, range raw 0..1, to VCU
          signal EXV2_CurrentPosition_oEXV_2_VCU_oLIN00: start 16, 16 bit, little-endian, i-signal-type=PRIMITIVE, init-value=0, base-type=uint16, compu {identical}, range raw 0..500, to VCU
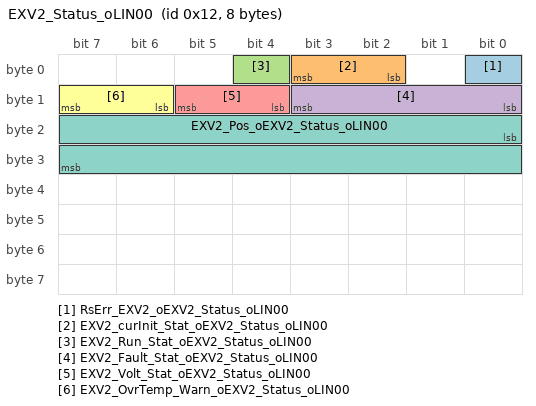
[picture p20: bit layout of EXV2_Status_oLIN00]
      frame EXV2_Status_oLIN00: id 0x12, to VCU, frame-length=8, lin-checksum=ENHANCED
        pdu EXV2_Status_oLIN00: length=8, unused-bit-pattern=255
          signal RsErr_EXV2_oEXV2_Status_oLIN00: start 0, 1 bit, little-endian, i-signal-type=PRIMITIVE, init-value=0, base-type=boolean, compu {0=Cx0_NO_COMM_ERROR (NO COMM ERROR), 1=Cx1_COMM_ERROR_DETECTED (COMM ERROR DETECTED)}, range raw 0..1, to VCU
          signal EXV2_curInit_Stat_oEXV2_Status_oLIN00: start 2, 2 bit, little-endian, i-signal-type=PRIMITIVE, init-value=0, base-type=uint8, compu {0=Cx0_NO_INIT, 1=Cx1_INIT_IN_PROCESS, 2=Cx2_INIT_READY, 3=Cx3_Invalid}, range raw 0..3, to VCU
          signal EXV2_Run_Stat_oEXV2_Status_oLIN00: start 4, 1 bit, little-endian, i-signal-type=PRIMITIVE, init-value=0, base-type=boolean, compu {0=Cx0_NO_MOVEMENT, 1=Cx1_ACT_MOVING}, range raw 0..1, to VCU
          signal EXV2_Fault_Stat_oEXV2_Status_oLIN00: start 8, 4 bit, little-endian, i-signal-type=PRIMITIVE, init-value=0, base-type=uint8, compu {0=Cx0_Actuator_Not_Faulted (Actuator Not Faulted), 1=Cx1_Motor_Coil_shorted (Motor-Coil shorted), 2=Cx2_Motor_Coil_open_load (Motor-Coil open load), 3=Cx3_Over_temperature_shutdown (Over temperature shutdown), 4=Cx4_not_defined (not defined), 5=Cx5_Motor_Stall_ (Motor_Stall?????????)} "Source signal range: [0,4]", range raw 0..5, to VCU
          signal EXV2_Volt_Stat_oEXV2_Status_oLIN00: start 12, 2 bit, little-endian, i-signal-type=PRIMITIVE, init-value=0, base-type=uint8, compu {0=Cx0_VOLT_RANGE_OK, 1=Cx1_OVERVOLTAGE, 2=Cx2_UNDERVOLTAGE, 3=Cx3_not_defined (not defined)} "Source signal range: [0,2]", range raw 0..3, to VCU
          signal EXV2_OvrTemp_Warn_oEXV2_Status_oLIN00: start 14, 2 bit, little-endian, i-signal-type=PRIMITIVE, init-value=0, base-type=uint8, compu {0=Cx0_Ok, 1=Cx1_High_Temperature_Warning (High Temperature Warning), 2=Cx2_not_defined (not defined), 3=Cx3_not_defined (not defined)} "Source signal range: [0,1]", range raw 0..3, to VCU
          signal EXV2_Pos_oEXV2_Status_oLIN00: start 16, 16 bit, little-endian, i-signal-type=PRIMITIVE, init-value=0, base-type=uint16, compu {identical}, range raw 0..576, to VCU
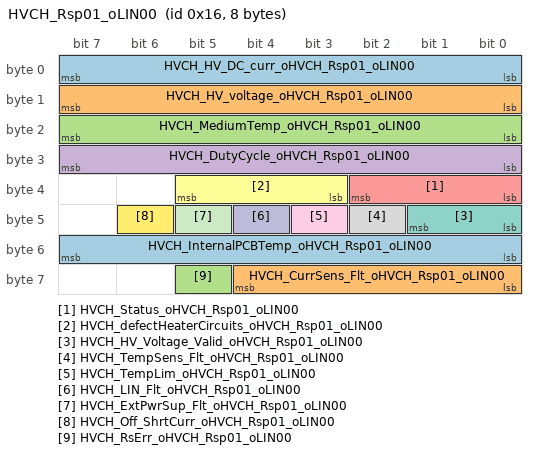
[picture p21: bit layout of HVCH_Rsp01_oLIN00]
      frame HVCH_Rsp01_oLIN00: id 0x16, to VCU, frame-length=8, lin-checksum=ENHANCED
        pdu HVCH_Rsp01_oLIN00: length=8, unused-bit-pattern=255
          signal HVCH_HV_DC_curr_oHVCH_Rsp01_oLIN00: start 0, 8 bit, little-endian, i-signal-type=PRIMITIVE, init-value=0, base-type=uint8, compu {0=Cx00_0x00_0xFE_Valid_value (0x00~0xFE, Valid value), 255=CxFF_invalid, phys=raw*0.25 for raw 1..254; unit A} "Source signal range: [0,254]", range raw 0..255, unit=A, to VCU
          signal HVCH_HV_voltage_oHVCH_Rsp01_oLIN00: start 8, 8 bit, little-endian, i-signal-type=PRIMITIVE, init-value=0, base-type=uint8, compu {0=Cx00_0x00_0xFE_Valid_value (0x00~0xFE, Valid value), 255=CxFF_invalid, phys=raw*2 for raw 1..254; unit V} "Source signal range: [0,254]", range raw 0..255, unit=V, to VCU
          signal HVCH_MediumTemp_oHVCH_Rsp01_oLIN00: start 16, 8 bit, little-endian, i-signal-type=PRIMITIVE, init-value=0, base-type=uint8, compu {0=Cx00_0x00_0xFE_Valid_value (0x00~0xFE, Valid value), 255=CxFF_invalid, phys=raw-50 for raw 1..254; unit celsius} "Source signal range: [0,254]", range raw 0..255, unit=celsius, to VCU
          signal HVCH_DutyCycle_oHVCH_Rsp01_oLIN00: start 24, 8 bit, little-endian, i-signal-type=PRIMITIVE, init-value=50, base-type=uint8, compu {0=Cx00_0x00_0x96_Valid_value (0x00~0x96, Valid value), 255=CxFF_invalid, phys=raw-50 for raw 1..150; unit percent} "Source signal range: [0,150]", range raw 0..255, unit=percent, to VCU
          signal HVCH_Status_oHVCH_Rsp01_oLIN00: start 32, 3 bit, little-endian, i-signal-type=PRIMITIVE, init-value=0, base-type=uint8, compu {0=Cx0_HV_PTC_off_HVCH_OFF (HV PTC off / HVCH_OFF), 1=Cx1_HV_PTC_on_HVCH_ON (HV PTC on / HVCH_ON), 2=Cx2_0x2_0x7_SNA (0x2~0x7, SNA)}, range raw 0..7, to VCU
          signal HVCH_defectHeaterCircuits_oHVCH_Rsp01_oLIN00: start 35, 3 bit, little-endian, i-signal-type=PRIMITIVE, init-value=0, base-type=uint8, compu {0=Cx0_No_defect (No defect), 1=Cx1_Leg_1_defect (Leg 1 defect), 2=Cx2_Leg_2_defect (Leg 2 defect), 3=Cx3_Leg_1_2_defect (Leg 1 + 2 defect), 4=Cx4_Leg_3_defect (Leg 3 defect), 5=Cx5_Leg_1_3_defect (Leg 1 + 3 defect), 6=Cx6_Leg_2_3_defect (Leg 2 + 3 defect), 7=Cx7_Leg_1_2_3_defect (Leg 1 + 2 + 3 defect)}, range raw 0..7, to VCU
          signal HVCH_HV_Voltage_Valid_oHVCH_Rsp01_oLIN00: start 40, 2 bit, little-endian, i-signal-type=PRIMITIVE, init-value=0, base-type=uint8, compu {0=Cx0_NO_HV_detected (NO HV detected), 1=Cx1_HV_valid (HV valid), 2=Cx2_Under_Voltage (Under Voltage), 3=Cx3_Over_Voltage (Over Voltage)}, range raw 0..3, to VCU
          signal HVCH_TempSens_Flt_oHVCH_Rsp01_oLIN00: start 42, 1 bit, little-endian, i-signal-type=PRIMITIVE, init-value=0, base-type=boolean, compu {0=Cx0_No_fault (No fault), 1=Cx1_fault}, range raw 0..1, to VCU
          signal HVCH_TempLim_oHVCH_Rsp01_oLIN00: start 43, 1 bit, little-endian, i-signal-type=PRIMITIVE, init-value=0, base-type=boolean, compu {0=Cx0_No_over_temperature_detected (No over temperature detected), 1=Cx1_Over_temp_situation_active (Over temp. situation active)}, range raw 0..1, to VCU
          signal HVCH_LIN_Flt_oHVCH_Rsp01_oLIN00: start 44, 1 bit, little-endian, i-signal-type=PRIMITIVE, init-value=0, base-type=boolean, compu {0=Cx0_No_LIN_timeout_detected (No LIN timeout detected), 1=Cx1_LIN_timeout_active (LIN timeout active)}, range raw 0..1, to VCU
          signal HVCH_ExtPwrSup_Flt_oHVCH_Rsp01_oLIN00: start 45, 1 bit, little-endian, i-signal-type=PRIMITIVE, init-value=0, base-type=boolean, compu {0=Cx0_Battery_voltage_okay (Battery voltage okay), 1=Cx1_Battery_voltage_off (Battery voltage off)}, range raw 0..1, to VCU
          signal HVCH_Off_ShrtCurr_oHVCH_Rsp01_oLIN00: start 46, 1 bit, little-endian, i-signal-type=PRIMITIVE, init-value=0, base-type=boolean, compu {0=Cx0_No_short_detected (No short detected), 1=Cx1_Short_detected (Short detected)}, range raw 0..1, to VCU
          signal HVCH_InternalPCBTemp_oHVCH_Rsp01_oLIN00: start 48, 8 bit, little-endian, i-signal-type=PRIMITIVE, init-value=0, base-type=uint8, compu {0=Cx00_0x00_0xFE_Valid_value (0x00~0xFE, Valid value), 255=CxFF_invalid, phys=raw-50 for raw 1..254} "Source signal range: [0,254]", range raw 0..255, to VCU
          signal HVCH_CurrSens_Flt_oHVCH_Rsp01_oLIN00: start 56, 5 bit, little-endian, i-signal-type=PRIMITIVE, init-value=0, base-type=uint8, compu {0=Cx00_Diagnostic_pending (Diagnostic pending), 1=Cx01_Diagnostic_passed (Diagnostic passed), 2=Cx02_0x2_0x1F_Reserve (0x2~0x1F, Reserve)}, range raw 0..31, to VCU
          signal HVCH_RsErr_oHVCH_Rsp01_oLIN00: start 61, 1 bit, little-endian, i-signal-type=PRIMITIVE, init-value=0, base-type=boolean, compu {0=Cx0_No_LIN_response_error_detected (No LIN response error detected), 1=Cx1_LIN_response_error_active (LIN response error active)}, range raw 0..1, to VCU
      frame HVCH_Rsp02_oLIN00: id 0x17, to VCU, frame-length=8, lin-checksum=ENHANCED
        pdu HVCH_Rsp02_oLIN00: length=8, unused-bit-pattern=255
          signal HVCH_IntelTemp_oHVCH_Rsp02_oLIN00: start 0, 8 bit, little-endian, i-signal-type=PRIMITIVE, init-value=0, base-type=uint8, compu {0=Cx00_0x00_0xFE_Valid_value (0x00~0xFE, Valid value), 255=CxFF_invalid, phys=raw-50 for raw 1..254; unit celsius} "Source signal range: [0,254]", range raw 0..255, unit=celsius, to VCU
      frame MasterReq_oLIN00: id 0x3C, from VCU, frame-length=8, lin-checksum=CLASSIC
        n pdu MasterReq_Tp_oLIN00: length=8
      frame PMP_Cmd_oLIN00: id 0x24, from VCU, frame-length=8, lin-checksum=ENHANCED
        pdu PMP_Cmd_oLIN00: length=8, unused-bit-pattern=255
          signal ECC_PMP2_SpdSet_oPMP_Cmd_oLIN00: start 8, 8 bit, little-endian, i-signal-type=PRIMITIVE, init-value=0, base-type=uint8, compu {phys=raw*0.4 for raw 0..100; unit %}, range raw 0..100, unit=%
          signal ECC_PMP3_SpdSet_oPMP_Cmd_oLIN00: start 16, 8 bit, little-endian, i-signal-type=PRIMITIVE, init-value=0, base-type=uint8, compu {phys=raw*0.4 for raw 0..100; unit %}, range raw 0..100, unit=%
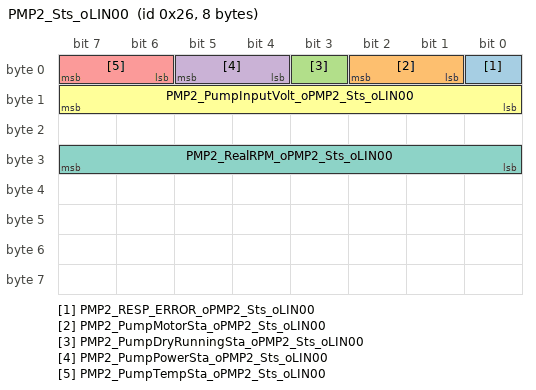
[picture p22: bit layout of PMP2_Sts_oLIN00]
      frame PMP2_Sts_oLIN00: id 0x26, to VCU, frame-length=8, lin-checksum=ENHANCED
        pdu PMP2_Sts_oLIN00: length=8, unused-bit-pattern=255
          signal PMP2_RESP_ERROR_oPMP2_Sts_oLIN00: start 0, 1 bit, little-endian, i-signal-type=PRIMITIVE, init-value=0, base-type=boolean, compu {0=Cx0_Normal, 1=Cx1_Error}, range raw 0..1, to VCU
          signal PMP2_PumpMotorSta_oPMP2_Sts_oLIN00: start 1, 2 bit, little-endian, i-signal-type=PRIMITIVE, init-value=0, base-type=uint8, compu {0=Cx0_Normal, 1=Cx1_ShortCircuit, 2=Cx2_OpenCircuit, 3=Cx3_Stall}, range raw 0..3, to VCU
          signal PMP2_PumpDryRunningSta_oPMP2_Sts_oLIN00: start 3, 1 bit, little-endian, i-signal-type=PRIMITIVE, init-value=0, base-type=boolean, compu {0=Cx0_Normal, 1=Cx1_DryRun}, range raw 0..1, to VCU
          signal PMP2_PumpPowerSta_oPMP2_Sts_oLIN00: start 4, 2 bit, little-endian, i-signal-type=PRIMITIVE, init-value=0, base-type=uint8, compu {0=Cx0_Normal, 1=Cx1_OverVol, 2=Cx2_BelowVol, 3=Cx3_Reserved}, range raw 0..3, to VCU
          signal PMP2_PumpTempSta_oPMP2_Sts_oLIN00: start 6, 2 bit, little-endian, i-signal-type=PRIMITIVE, init-value=0, base-type=uint8, compu {0=Cx0_Normal, 1=Cx1_OverTempReduction, 2=Cx2_OverTempShutDown, 3=Cx3_Reserved}, range raw 0..3, to VCU
          signal PMP2_PumpInputVolt_oPMP2_Sts_oLIN00: start 8, 8 bit, little-endian, i-signal-type=PRIMITIVE, init-value=0, base-type=uint8, compu {phys=raw*0.1 for raw 0..30; unit V}, range raw 0..30, unit=V, to VCU
          signal PMP2_RealRPM_oPMP2_Sts_oLIN00: start 24, 8 bit, little-endian, i-signal-type=PRIMITIVE, init-value=0, base-type=uint8, compu {phys=raw*0.4 for raw 0..100; unit %}, range raw 0..100, unit=%, to VCU
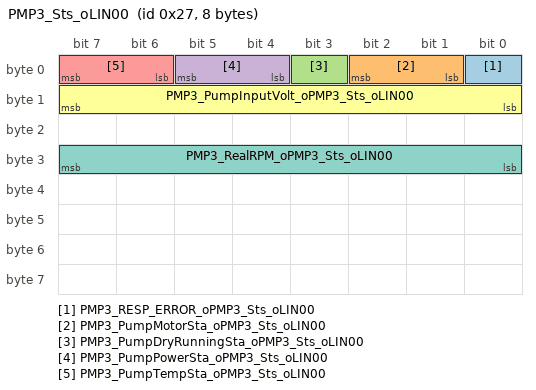
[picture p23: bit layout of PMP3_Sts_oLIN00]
      frame PMP3_Sts_oLIN00: id 0x27, to VCU, frame-length=8, lin-checksum=ENHANCED
        pdu PMP3_Sts_oLIN00: length=8, unused-bit-pattern=255
          signal PMP3_RESP_ERROR_oPMP3_Sts_oLIN00: start 0, 1 bit, little-endian, i-signal-type=PRIMITIVE, init-value=0, base-type=boolean, compu {0=Cx0_Normal, 1=Cx1_Error}, range raw 0..1, to VCU
          signal PMP3_PumpMotorSta_oPMP3_Sts_oLIN00: start 1, 2 bit, little-endian, i-signal-type=PRIMITIVE, init-value=0, base-type=uint8, compu {0=Cx0_Normal, 1=Cx1_ShortCircuit, 2=Cx2_OpenCircuit, 3=Cx3_Stall}, range raw 0..3, to VCU
          signal PMP3_PumpDryRunningSta_oPMP3_Sts_oLIN00: start 3, 1 bit, little-endian, i-signal-type=PRIMITIVE, init-value=0, base-type=boolean, compu {0=Cx0_Normal, 1=Cx1_DryRun}, range raw 0..1, to VCU
          signal PMP3_PumpPowerSta_oPMP3_Sts_oLIN00: start 4, 2 bit, little-endian, i-signal-type=PRIMITIVE, init-value=0, base-type=uint8, compu {0=Cx0_Normal, 1=Cx1_OverVol, 2=Cx2_BelowVol, 3=Cx3_Reserved}, range raw 0..3, to VCU
          signal PMP3_PumpTempSta_oPMP3_Sts_oLIN00: start 6, 2 bit, little-endian, i-signal-type=PRIMITIVE, init-value=0, base-type=uint8, compu {0=Cx0_Normal, 1=Cx1_OverTempReduction, 2=Cx2_OverTempShutDown, 3=Cx3_Reserved}, range raw 0..3, to VCU
          signal PMP3_PumpInputVolt_oPMP3_Sts_oLIN00: start 8, 8 bit, little-endian, i-signal-type=PRIMITIVE, init-value=0, base-type=uint8, compu {phys=raw*0.1 for raw 0..30; unit V}, range raw 0..30, unit=V, to VCU
          signal PMP3_RealRPM_oPMP3_Sts_oLIN00: start 24, 8 bit, little-endian, i-signal-type=PRIMITIVE, init-value=0, base-type=uint8, compu {phys=raw*0.4 for raw 0..100; unit %}, range raw 0..100, unit=%, to VCU
      frame SlaveResp_oLIN00: id 0x3D, to VCU, frame-length=8, lin-checksum=CLASSIC
        n pdu SlaveResp_Tp_oLIN00: length=8
      frame SVA_VCU_STD_oLIN00: id 0x11, to VCU, frame-length=8, lin-checksum=ENHANCED
        pdu SVA_VCU_STD_oLIN00: length=8, unused-bit-pattern=255
          signal Calibration_sta_oSVA_VCU_STD_oLIN00: start 0, 2 bit, little-endian, i-signal-type=PRIMITIVE, init-value=0, base-type=uint8, compu {0=Cx0_not_calibration (not calibration), 1=Cx1_calibration_ongoing (calibration ongoing), 2=Cx2_calibration_finished (calibration finished), 3=Cx3_calibration_failed (calibration failed)}, range raw 0..3, to VCU
          signal Blockage_Fault_STA_oSVA_VCU_STD_oLIN00: start 2, 1 bit, little-endian, i-signal-type=PRIMITIVE, init-value=0, base-type=boolean, compu {0=Cx0_False, 1=Cx1_True}, range raw 0..1, to VCU
          signal Breakage_Fault_STA_oSVA_VCU_STD_oLIN00: start 3, 1 bit, little-endian, i-signal-type=PRIMITIVE, init-value=0, base-type=boolean, compu {0=Cx0_False, 1=Cx1_True}, range raw 0..1, to VCU
          signal Act_Pos_sta_oSVA_VCU_STD_oLIN00: start 8, 12 bit, little-endian, i-signal-type=PRIMITIVE, init-value=0, base-type=uint16, compu {phys=raw*0.1-5 for raw 0..3600; unit Degree}, range raw 0..3600, unit=Degree, to VCU
          signal LIN_Resp_Error_sta_oSVA_VCU_STD_oLIN00: start 32, 1 bit, little-endian, i-signal-type=PRIMITIVE, init-value=0, base-type=boolean, compu {0=Cx0_False, 1=Cx1_True}, range raw 0..1, to VCU
      frame TCU_HVCH_Cmd_oLIN00: id 0x15, from VCU, frame-length=4, lin-checksum=ENHANCED
        pdu TCU_HVCH_Cmd_oLIN00: length=4, unused-bit-pattern=255
          signal TCU_HVCH_heating_rq_oTCU_HVCH_Cmd_oLIN00: start 0, 7 bit, little-endian, i-signal-type=PRIMITIVE, init-value=0, base-type=uint8, compu {0=Cx00_Level0, 1=Cx01_Level1, 2=Cx02_Level2, 3=Cx03_Level3, 4=Cx04_Level4, 5=Cx05_Level5, 6=Cx06_Level6, 7=Cx07_Reserve; unit percent}, range raw 0..100, unit=percent
          signal TCU_HVCH_On_Rq_oTCU_HVCH_Cmd_oLIN00: start 8, 2 bit, little-endian, i-signal-type=PRIMITIVE, init-value=0, base-type=uint8, invalid-value=3, compu {0=Cx0_PTC_OFF, 1=Cx1_PTC_ON, 2=Cx2_reserved_RES (reserved / RES), 3=Cx3_SNA}, range raw 0..3
          signal TCU_HVCHMaxPowerLimit_oTCU_HVCH_Cmd_oLIN00: start 16, 8 bit, little-endian, i-signal-type=PRIMITIVE, init-value=0, base-type=uint8, compu {0=Cx00_0x00_0xFE_Valid_value (0x00~0xFE, Valid value), 255=CxFF_invalid, phys=raw*0.04 for raw 1..254; unit KW} "Source signal range: [0,254]", range raw 0..255, unit=KW
          signal TCU_HVCH_TmaxLim_output_oTCU_HVCH_Cmd_oLIN00: start 24, 8 bit, little-endian, i-signal-type=PRIMITIVE, init-value=0, base-type=uint8, compu {0=Cx00_0x00_0xFE_Valid_value (0x00~0xFE, Valid value), 255=CxFF_invalid, phys=raw-50 for raw 1..254; unit celsius} "Source signal range: [0,254]", range raw 0..255, unit=celsius
      frame VCU_EXV_1_oLIN00: id 0x1F, from VCU, frame-length=8, lin-checksum=ENHANCED
        pdu VCU_EXV_1_oLIN00: length=8, unused-bit-pattern=255
          signal TMM_EXV1_PositionRequest_oVCU_EXV_1_oLIN00: start 0, 16 bit, little-endian, i-signal-type=PRIMITIVE, init-value=0, base-type=uint16, compu {identical}, range raw 0..500
          signal TMM_EXV1_EnableRequest_oVCU_EXV_1_oLIN00: start 16, 1 bit, little-endian, i-signal-type=PRIMITIVE, init-value=0, base-type=boolean, compu {0=Cx0_EXVNotEnable, 1=Cx1_EXVEnable}, range raw 0..1
          signal TMM_EXV1_initRequest_oVCU_EXV_1_oLIN00: start 24, 3 bit, little-endian, i-signal-type=PRIMITIVE, init-value=0, base-type=uint8, compu {0=Cx0_NO_RQ, 1=Cx1_InitializationReq_, 2=Cx2_waiting_for_Sequence_to_finish (waiting for Sequence to finish)}, range raw 0..7
      frame VCU_EXV_2_oLIN00: id 0x34, from VCU, frame-length=8, lin-checksum=ENHANCED
        pdu VCU_EXV_2_oLIN00: length=8, unused-bit-pattern=255
          signal TMM_EXV2_PositionRequest_oVCU_EXV_2_oLIN00: start 0, 16 bit, little-endian, i-signal-type=PRIMITIVE, init-value=0, base-type=uint16, compu {identical}, range raw 0..500
          signal TMM_EXV2_EnableRequest_oVCU_EXV_2_oLIN00: start 16, 1 bit, little-endian, i-signal-type=PRIMITIVE, init-value=0, base-type=boolean, compu {0=Cx0_EXVNotEnable, 1=Cx1_EXVEnable}, range raw 0..1
          signal TMM_EXV2_initRequest_oVCU_EXV_2_oLIN00: start 24, 3 bit, little-endian, i-signal-type=PRIMITIVE, init-value=0, base-type=uint8, compu {0=Cx0_NO_RQ, 1=Cx1_InitializationReq_, 2=Cx2_waiting_for_Sequence_to_finish (waiting for Sequence to finish)}, range raw 0..7
      frame VCU_SVA_CMD_oLIN00: id 0x10, from VCU, frame-length=8, lin-checksum=ENHANCED
        pdu VCU_SVA_CMD_oLIN00: length=8, unused-bit-pattern=255
          signal Calibration_cmd_oVCU_SVA_CMD_oLIN00: start 8, 1 bit, little-endian, i-signal-type=PRIMITIVE, init-value=0, base-type=boolean, compu {0=Cx0_Normal, 1=Cx1_SVA_performs_calibration (SVA performs calibration)}, range raw 0..1
          signal Target_Pos_cmd_oVCU_SVA_CMD_oLIN00: start 16, 12 bit, little-endian, i-signal-type=PRIMITIVE, init-value=0, base-type=uint16, compu {phys=raw*0.1-5 for raw 0..3600; unit Degree}, range raw 0..3600, unit=Degree
      pdu triggering PT_MasterReq: pdu=MasterReq_oLIN00, from VCU
      pdu triggering PT_MasterReq_ERV: pdu=MasterReq_ERV_oLIN00, from VCU
      pdu triggering PT_MasterReq_EXV_1: pdu=MasterReq_EXV_1_oLIN00, from VCU
      pdu triggering PT_MasterReq_EXV_2: pdu=MasterReq_EXV_2_oLIN00, from VCU
      pdu triggering PT_MasterReq_HVCH: pdu=MasterReq_HVCH_oLIN00, from VCU
      pdu triggering PT_MasterReq_PMP_1: pdu=MasterReq_PMP_1_oLIN00, from VCU
      pdu triggering PT_MasterReq_PMP_2: pdu=MasterReq_PMP_2_oLIN00, from VCU
      pdu triggering PT_MasterReq_SVA: pdu=MasterReq_SVA_oLIN00, from VCU
      pdu triggering PT_SlaveResp_ERV: pdu=SlaveResp_ERV_oLIN00, to VCU
      pdu triggering PT_SlaveResp_EXV_1: pdu=SlaveResp_EXV_1_oLIN00, to VCU
      pdu triggering PT_SlaveResp_EXV_2: pdu=SlaveResp_EXV_2_oLIN00, to VCU
      pdu triggering PT_SlaveResp_HVCH: pdu=SlaveResp_HVCH_oLIN00, to VCU
      pdu triggering PT_SlaveResp_PMP_1: pdu=SlaveResp_PMP_1_oLIN00, to VCU
      pdu triggering PT_SlaveResp_PMP_2: pdu=SlaveResp_PMP_2_oLIN00, to VCU
      pdu triggering PT_SlaveResp_SVA: pdu=SlaveResp_SVA_oLIN00, to VCU
      lin schedule table TCU_LIN_Schedule: run-mode=RUN-CONTINUOUS
        table-entrys:
          delay=0.01, position-in-table=0, frame-triggering=FT_EDCU_EXV2
          delay=0.01, position-in-table=1, frame-triggering=FT_EXV2_Status
          delay=0.1, position-in-table=2, frame-triggering=FT_VCU_EXV_1
          delay=0.1, position-in-table=3, frame-triggering=FT_EXV_1_VCU
          delay=0.1, position-in-table=4, frame-triggering=FT_VCU_EXV_2
          delay=0.1, position-in-table=5, frame-triggering=FT_EXV_2_VCU
          delay=0.01, position-in-table=6, frame-triggering=FT_PMP_Cmd
          delay=0.01, position-in-table=7, frame-triggering=FT_PMP2_Sts
          delay=0.01, position-in-table=8, frame-triggering=FT_PMP3_Sts
          delay=0.015, position-in-table=9, frame-triggering=FT_VCU_SVA_CMD
          delay=0.015, position-in-table=10, frame-triggering=FT_SVA_VCU_STD
          delay=0.02, position-in-table=11, frame-triggering=FT_TCU_HVCH_Cmd
          delay=0.02, position-in-table=12, frame-triggering=FT_HVCH_Rsp01
          delay=0.02, position-in-table=13, frame-triggering=FT_HVCH_Rsp02
  lin cluster LIN01: baudrate=19200, protocol-name=LIN, protocol-version=LIN21  # LIN4 | /*************************************************************************************/ // // Description: // Created: // Author: // Version: // Vehicle Project: // /*************************************************************************************/
    lin physical channel CHNL: comm-connectors=CN_LIN01
      frame MasterReq_oLIN01: id 0x3C, from VCU, frame-length=8, lin-checksum=CLASSIC
        n pdu MasterReq_Tp_oLIN01: length=8
      frame SlaveResp_oLIN01: id 0x3D, to VCU, frame-length=8, lin-checksum=CLASSIC
        n pdu SlaveResp_Tp_oLIN01: length=8
      frame Vcu_Lin0_RxMsg1_oLIN01: id 0x20, to VCU, frame-length=8, lin-checksum=ENHANCED
        pdu Vcu_Lin0_RxMsg1_oLIN01: length=8, unused-bit-pattern=255
          signal Vcu_Lin0_RxMsg1_Sig1_oVcu_Lin0_RxMsg1_oLIN01: start 0, 8 bit, little-endian, i-signal-type=PRIMITIVE, init-value=0, base-type=uint8, compu {identical}, range raw 0..255, to VCU
          signal Vcu_Lin0_RxMsg1_Sig0_oVcu_Lin0_RxMsg1_oLIN01: start 8, 8 bit, little-endian, i-signal-type=PRIMITIVE, init-value=0, base-type=uint8, compu {identical}, range raw 0..255, to VCU
          signal Vcu_Lin0_RxMsg2_Sig2_oVcu_Lin0_RxMsg1_oLIN01: start 16, 8 bit, little-endian, i-signal-type=PRIMITIVE, init-value=0, base-type=uint8, compu {identical}, range raw 0..255, to VCU
          signal Vcu_Lin0_RxMsg2_Sig3_oVcu_Lin0_RxMsg1_oLIN01: start 24, 8 bit, little-endian, i-signal-type=PRIMITIVE, init-value=0, base-type=uint8, compu {identical}, range raw 0..255, to VCU
      frame Vcu_Lin0_RxMsg2_oLIN01: id 0x21, to VCU, frame-length=8, lin-checksum=ENHANCED
        pdu Vcu_Lin0_RxMsg2_oLIN01: length=8, unused-bit-pattern=255
          signal Vcu_Lin0_RxMsg2_Sig0_oVcu_Lin0_RxMsg2_oLIN01: start 0, 8 bit, little-endian, i-signal-type=PRIMITIVE, init-value=0, base-type=uint8, compu {identical}, range raw 0..255, to VCU
          signal Vcu_Lin0_RxMsg2_Sig1_oVcu_Lin0_RxMsg2_oLIN01: start 8, 8 bit, little-endian, i-signal-type=PRIMITIVE, init-value=0, base-type=uint8, compu {identical}, range raw 0..255, to VCU
          signal Vcu_Lin0_RxMsg2_Sig2_oVcu_Lin0_RxMsg2_oLIN01: start 16, 8 bit, little-endian, i-signal-type=PRIMITIVE, init-value=0, base-type=uint8, compu {identical}, range raw 0..255, to VCU
          signal Vcu_Lin0_RxMsg2_Sig3_oVcu_Lin0_RxMsg2_oLIN01: start 32, 8 bit, little-endian, i-signal-type=PRIMITIVE, init-value=0, base-type=uint8, compu {identical}, range raw 0..255, to VCU
      frame Vcu_Lin0_TxMsg1_oLIN01: id 0x1E, from VCU, frame-length=8, lin-checksum=ENHANCED
        pdu Vcu_Lin0_TxMsg1_oLIN01: length=8, unused-bit-pattern=255
          signal Vcu_Lin0_TxMsg1_Sig0_oVcu_Lin0_TxMsg1_oLIN01: start 0, 8 bit, little-endian, i-signal-type=PRIMITIVE, init-value=0, base-type=uint8, compu {identical}, range raw 0..255
          signal Vcu_Lin0_TxMsg1_Sig1_oVcu_Lin0_TxMsg1_oLIN01: start 8, 8 bit, little-endian, i-signal-type=PRIMITIVE, init-value=0, base-type=uint8, compu {identical}, range raw 0..255
          signal Vcu_Lin0_TxMsg1_Sig2_oVcu_Lin0_TxMsg1_oLIN01: start 16, 8 bit, little-endian, i-signal-type=PRIMITIVE, init-value=0, base-type=uint8, compu {identical}, range raw 0..255
          signal Vcu_Lin0_TxMsg1_Sig3_oVcu_Lin0_TxMsg1_oLIN01: start 24, 8 bit, little-endian, i-signal-type=PRIMITIVE, init-value=0, base-type=uint8, compu {identical}, range raw 0..255
      frame Vcu_Lin0_TxMsg2_oLIN01: id 0x1F, from VCU, frame-length=8, lin-checksum=ENHANCED
        pdu Vcu_Lin0_TxMsg2_oLIN01: length=8, unused-bit-pattern=255
          signal Vcu_Lin0_TxMsg2_Sig0_oVcu_Lin0_TxMsg2_oLIN01: start 0, 8 bit, little-endian, i-signal-type=PRIMITIVE, init-value=0, base-type=uint8, compu {identical}, range raw 0..255
          signal Vcu_Lin0_TxMsg2_Sig1_oVcu_Lin0_TxMsg2_oLIN01: start 8, 8 bit, little-endian, i-signal-type=PRIMITIVE, init-value=0, base-type=uint8, compu {identical}, range raw 0..255
          signal Vcu_Lin0_TxMsg2_Sig2_oVcu_Lin0_TxMsg2_oLIN01: start 16, 8 bit, little-endian, i-signal-type=PRIMITIVE, init-value=0, base-type=uint8, compu {identical}, range raw 0..255
          signal Vcu_Lin0_TxMsg2_Sig3_oVcu_Lin0_TxMsg2_oLIN01: start 24, 8 bit, little-endian, i-signal-type=PRIMITIVE, init-value=0, base-type=uint8, compu {identical}, range raw 0..255
      pdu triggering PT_MasterReq: pdu=MasterReq_oLIN01, from VCU
      pdu triggering PT_MasterReq_GWM: pdu=MasterReq_GWM_oLIN01, from VCU
      pdu triggering PT_SlaveResp_GWM: pdu=SlaveResp_GWM_oLIN01, to VCU
      lin schedule table Vcu_Lin0_Schedule: run-mode=RUN-CONTINUOUS
        table-entrys:
          delay=0.02, position-in-table=0, frame-triggering=FT_Vcu_Lin0_TxMsg1
          delay=0.02, position-in-table=1, frame-triggering=FT_Vcu_Lin0_TxMsg2
          delay=0.02, position-in-table=2, frame-triggering=FT_Vcu_Lin0_RxMsg1
          delay=0.02, position-in-table=3, frame-triggering=FT_Vcu_Lin0_RxMsg2
